VERSION ""

NS_ :

BS_:

BU_: BMS CVC_P EVCC FMCU RMCU POD_GW PCU ADCU_P DUMMY_ECU

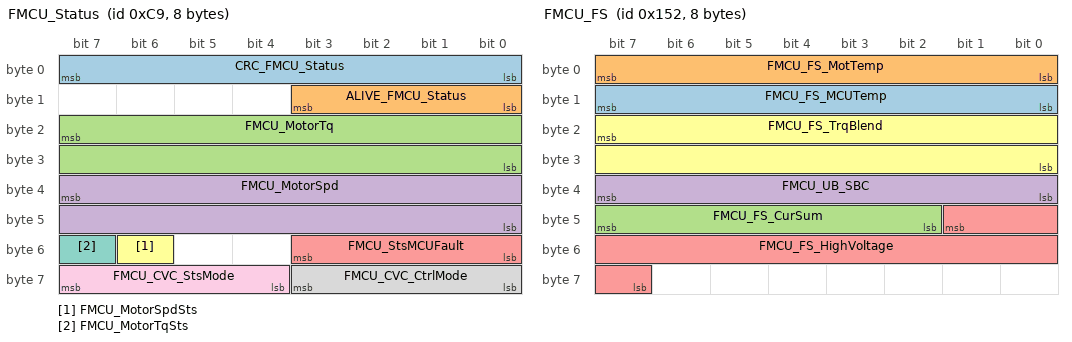
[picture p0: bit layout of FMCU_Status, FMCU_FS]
BO_ 201 FMCU_Status: 8 FMCU
 SG_ CRC_FMCU_Status : 7|8@0+ (1,0) [0|255] ""  BMS,CVC_P,EVCC
 SG_ ALIVE_FMCU_Status : 11|4@0+ (1,0) [0|15] ""  BMS,CVC_P,EVCC
 SG_ FMCU_MotorTq : 23|16@0+ (0.1,-400) [-400|400] "Nm"  BMS,CVC_P,EVCC
 SG_ FMCU_MotorSpd : 39|16@0+ (1,-20000) [-20000|45531] "rpm"  BMS,CVC_P,EVCC
 SG_ FMCU_StsMCUFault : 51|4@0+ (1,0) [0|15] ""  BMS,CVC_P,EVCC
 SG_ FMCU_MotorSpdSts : 54|1@0+ (1,0) [0|1] ""  BMS,CVC_P,EVCC
 SG_ FMCU_MotorTqSts : 55|1@0+ (1,0) [0|1] ""  BMS,CVC_P,EVCC
 SG_ FMCU_CVC_CtrlMode : 59|4@0+ (1,0) [0|15] ""  BMS,CVC_P,EVCC
 SG_ FMCU_CVC_StsMode : 63|4@0+ (1,0) [0|15] ""  BMS,CVC_P,EVCC

BO_ 202 FMCU_Ability: 12 FMCU
 SG_ CRC_FMCU_Ability : 7|8@0+ (1,0) [0|255] ""  CVC_P
 SG_ ALIVE_FMCU_Ability : 11|4@0+ (1,0) [0|15] ""  CVC_P
 SG_ FMCU_CVC_PosTrqLmt : 53|12@0+ (0.1,0) [0|400] ""  CVC_P
 SG_ FMCU_CVC_NegTrqLmt : 57|12@0+ (0.1,-400) [-400|0] "Nm"  CVC_P
 SG_ FMCU_ActInputCurrent : 31|12@0+ (0.5,-1000) [-1000|1000] "A"  CVC_P
 SG_ FMCU_ActInputVolt : 35|12@0+ (0.5,0) [0|1000] "V"  CVC_P
 SG_ FMCU_ActInputVoltV : 54|1@0+ (1,0) [0|1] ""  CVC_P
 SG_ FMCU_ActInputCurrentV : 55|1@0+ (1,0) [0|1] ""  CVC_P

BO_ 338 FMCU_FS: 8 FMCU
 SG_ FMCU_FS_MCUTemp : 15|8@0+ (1,-50) [-50|200] "Degree C"  DUMMY_ECU
 SG_ FMCU_FS_MotTemp : 7|8@0+ (1,-50) [-50|200] "Degree C"  DUMMY_ECU
 SG_ FMCU_FS_CurSum : 47|6@0+ (1,0) [0|63] "V"  DUMMY_ECU
 SG_ FMCU_UB_SBC : 39|8@0+ (0.1,0) [0|25.5] "V"  DUMMY_ECU
 SG_ FMCU_FS_HighVoltage : 41|11@0+ (0.5,0) [0|1023.5] "V"  DUMMY_ECU
 SG_ FMCU_FS_TrqBlend : 23|16@0+ (0.1,-400) [-400|400] "Nm"  DUMMY_ECU

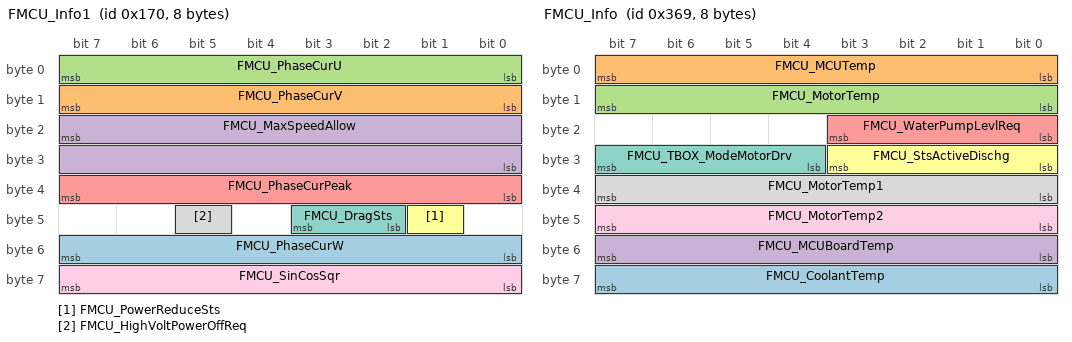
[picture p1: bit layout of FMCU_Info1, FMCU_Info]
BO_ 368 FMCU_Info1: 8 FMCU
 SG_ FMCU_PhaseCurW : 55|8@0+ (12,-1500) [-1500|1560] "A"  CVC_P
 SG_ FMCU_PhaseCurV : 15|8@0+ (12,-1500) [-1500|1560] "A"  CVC_P
 SG_ FMCU_PhaseCurU : 7|8@0+ (12,-1500) [-1500|1560] "A"  CVC_P
 SG_ FMCU_MaxSpeedAllow : 23|16@0+ (1,-17000) [-17000|17000] "rpm"  CVC_P
 SG_ FMCU_PhaseCurPeak : 39|8@0+ (12,-1500) [-1500|1560] "A"  CVC_P
 SG_ FMCU_PowerReduceSts : 41|1@0+ (1,0) [0|1] ""  CVC_P
 SG_ FMCU_DragSts : 43|2@0+ (1,0) [0|3] ""  CVC_P
 SG_ FMCU_HighVoltPowerOffReq : 45|1@0+ (1,0) [0|1] ""  CVC_P
 SG_ FMCU_SinCosSqr : 63|8@0+ (0.2,0) [0|51] ""  CVC_P

BO_ 568 FMCU_curSts: 12 FMCU
 SG_ FMCU_IGBT_WTemp : 63|8@0+ (1,-50) [-50|200] "Degree C"  CVC_P
 SG_ FMCU_IGBT_VTemp : 55|8@0+ (1,-50) [-50|200] "Degree C"  CVC_P
 SG_ FMCU_IGBT_UTemp : 47|8@0+ (1,-50) [-50|200] "Degree C"  CVC_P
 SG_ FMCU_JunctionIGBT_WTemp : 31|8@0+ (1,-50) [-50|200] "Degree C"  CVC_P
 SG_ FMCU_JunctionIGBT_VTemp : 23|8@0+ (1,-50) [-50|200] "Degree C"  CVC_P
 SG_ FMCU_JunctionIGBT_UTemp : 15|8@0+ (1,-50) [-50|200] "Degree C"  CVC_P
 SG_ FMCU_KL15 : 32|1@0+ (1,0) [0|1] ""  CVC_P
 SG_ FMCU_KL30 : 71|8@0+ (0.1,0) [0|25.5] "V"  CVC_P
 SG_ FMCU_SSUState : 36|3@0+ (1,0) [0|7] ""  CVC_P
 SG_ FMCU_DampingState : 37|1@0+ (1,0) [0|1] ""  CVC_P
 SG_ FMCU_IGBTState : 39|2@0+ (1,0) [0|3] ""  CVC_P
 SG_ FMCU_ASRSts : 33|1@0+ (1,0) [0|1] ""  CVC_P
 SG_ FMCU_ActualActiveHeatingPwr : 74|3@0+ (1,0) [0|8] "kW"  CVC_P

BO_ 872 FMCU_Fault: 8 FMCU
 SG_ FMCU_PhaseOverCurrentSWFault : 0|1@0+ (1,0) [0|1] ""  CVC_P
 SG_ FMCU_MCUOverTempFault : 1|1@0+ (1,0) [0|1] ""  CVC_P
 SG_ FMCU_MCUOverTempAlarm : 2|1@0+ (1,0) [0|1] ""  CVC_P
 SG_ FMCU_MotOverTemp2Fault : 5|1@0+ (1,0) [0|1] ""  CVC_P
 SG_ FMCU_MotTempSenFault : 6|1@0+ (1,0) [0|1] ""  CVC_P
 SG_ FMCU_MotOverTemp1Fault : 7|1@0+ (1,0) [0|1] ""  CVC_P
 SG_ FMCU_MotOverTempAlarm : 8|1@0+ (1,0) [0|1] ""  CVC_P
 SG_ FMCU_MCUHVUnderVoltageFault : 9|1@0+ (1,0) [0|1] ""  CVC_P
 SG_ FMCU_MCUHVUnderVoltageAlarm : 10|1@0+ (1,0) [0|1] ""  CVC_P
 SG_ FMCU_MCUHVOverVoltageFault : 11|1@0+ (1,0) [0|1] ""  CVC_P
 SG_ FMCU_MCUHVOverVoltageAlarm : 12|1@0+ (1,0) [0|1] ""  CVC_P
 SG_ FMCU_MCUCurrentSenWFault : 13|1@0+ (1,0) [0|1] ""  CVC_P
 SG_ FMCU_MCUCurrentSenVFault : 14|1@0+ (1,0) [0|1] ""  CVC_P
 SG_ FMCU_MCUCurrentSenUFault : 15|1@0+ (1,0) [0|1] ""  CVC_P
 SG_ FMCU_PhaseOverCurrentHWFault : 16|1@0+ (1,0) [0|1] ""  CVC_P
 SG_ FMCU_MotOverFault : 17|1@0+ (1,0) [0|1] ""  CVC_P
 SG_ FMCU_MotOverAlarm : 18|1@0+ (1,0) [0|1] ""  CVC_P
 SG_ FMCU_12VUnderVoltageAlarm : 20|1@0+ (1,0) [0|1] ""  CVC_P
 SG_ FMCU_12VOverVoltageAlarm : 21|1@0+ (1,0) [0|1] ""  CVC_P
 SG_ FMCU_MCUHVSensorFault : 22|1@0+ (1,0) [0|1] ""  CVC_P
 SG_ FMCU_MCUDisChgFault : 24|1@0+ (1,0) [0|1] ""  CVC_P
 SG_ FMCU_MotBlockedFault : 30|1@0+ (1,0) [0|1] ""  CVC_P
 SG_ FMCU_MotRotSenFault : 31|1@0+ (1,0) [0|1] ""  CVC_P
 SG_ FMCU_BMSLostFault : 34|1@0+ (1,0) [0|1] ""  CVC_P
 SG_ FMCU_CVCLostFault : 35|1@0+ (1,0) [0|1] ""  CVC_P
 SG_ FMCU_CANBusoffFault : 36|1@0+ (1,0) [0|1] ""  CVC_P
 SG_ FMCU_IGBTFault : 37|1@0+ (1,0) [0|1] ""  CVC_P
 SG_ FMCU_MCUCurrentSenWZeroFault : 38|1@0+ (1,0) [0|1] ""  CVC_P
 SG_ FMCU_MCUCurrentSenVZeroFault : 43|1@0+ (1,0) [0|1] ""  CVC_P
 SG_ FMCU_MCUCurrentSenUZeroFault : 44|1@0+ (1,0) [0|1] ""  CVC_P
 SG_ FMCU_MCUTempSenWFault : 45|1@0+ (1,0) [0|1] ""  CVC_P
 SG_ FMCU_MCUTempSenVFault : 46|1@0+ (1,0) [0|1] ""  CVC_P
 SG_ FMCU_MCUTempSenUFault : 47|1@0+ (1,0) [0|1] ""  CVC_P
 SG_ FMCU_InitMode : 50|1@0+ (1,0) [0|1] ""  CVC_P
 SG_ FMCU_MCUFaultCode : 63|8@0+ (1,0) [0|255] ""  CVC_P

BO_ 873 FMCU_Info: 8 FMCU
 SG_ FMCU_CoolantTemp : 63|8@0+ (1,-50) [-50|200] "Degree C"  CVC_P
 SG_ FMCU_MCUTemp : 7|8@0+ (1,-40) [-40|210] "Degree C"  CVC_P
 SG_ FMCU_MotorTemp : 15|8@0+ (1,-40) [-40|210] "Degree C"  CVC_P
 SG_ FMCU_MCUBoardTemp : 55|8@0+ (1,-40) [-40|210] "Degree C"  CVC_P
 SG_ FMCU_WaterPumpLevlReq : 19|4@0+ (2,0) [0|30] "lpm"  CVC_P
 SG_ FMCU_StsActiveDischg : 27|4@0+ (1,0) [0|15] ""  CVC_P
 SG_ FMCU_TBOX_ModeMotorDrv : 31|4@0+ (1,0) [0|15] ""  CVC_P
 SG_ FMCU_MotorTemp1 : 39|8@0+ (1,-40) [-40|210] "Degree C"  CVC_P
 SG_ FMCU_MotorTemp2 : 47|8@0+ (1,-40) [-40|210] "Degree C"  CVC_P

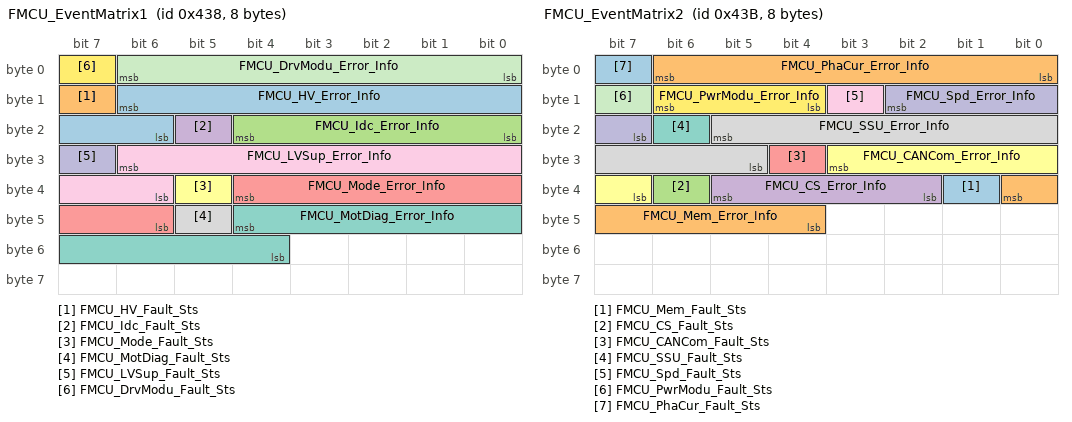
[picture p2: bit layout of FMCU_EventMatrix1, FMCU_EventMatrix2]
BO_ 1080 FMCU_EventMatrix1: 8 FMCU
 SG_ FMCU_HV_Error_Info : 14|9@0+ (1,0) [0|511] ""  DUMMY_ECU
 SG_ FMCU_HV_Fault_Sts : 15|1@0+ (1,0) [0|1] ""  DUMMY_ECU
 SG_ FMCU_Idc_Error_Info : 20|5@0+ (1,0) [0|31] ""  DUMMY_ECU
 SG_ FMCU_Idc_Fault_Sts : 21|1@0+ (1,0) [0|1] ""  DUMMY_ECU
 SG_ FMCU_Mode_Error_Info : 36|7@0+ (1,0) [0|127] ""  DUMMY_ECU
 SG_ FMCU_Mode_Fault_Sts : 37|1@0+ (1,0) [0|1] ""  DUMMY_ECU
 SG_ FMCU_MotDiag_Error_Info : 44|9@0+ (1,0) [0|511] ""  DUMMY_ECU
 SG_ FMCU_MotDiag_Fault_Sts : 45|1@0+ (1,0) [0|1] ""  DUMMY_ECU
 SG_ FMCU_LVSup_Error_Info : 30|9@0+ (1,0) [0|511] ""  DUMMY_ECU
 SG_ FMCU_LVSup_Fault_Sts : 31|1@0+ (1,0) [0|1] ""  DUMMY_ECU
 SG_ FMCU_DrvModu_Error_Info : 6|7@0+ (1,0) [0|127] ""  DUMMY_ECU
 SG_ FMCU_DrvModu_Fault_Sts : 7|1@0+ (1,0) [0|1] ""  DUMMY_ECU

BO_ 1083 FMCU_EventMatrix2: 8 FMCU
 SG_ FMCU_Mem_Fault_Sts : 33|1@0+ (1,0) [0|1] ""  DUMMY_ECU
 SG_ FMCU_Mem_Error_Info : 32|5@0+ (1,0) [0|31] ""  DUMMY_ECU
 SG_ FMCU_CS_Fault_Sts : 38|1@0+ (1,0) [0|1] ""  DUMMY_ECU
 SG_ FMCU_CS_Error_Info : 37|4@0+ (1,0) [0|15] ""  DUMMY_ECU
 SG_ FMCU_CANCom_Fault_Sts : 28|1@0+ (1,0) [0|1] ""  DUMMY_ECU
 SG_ FMCU_CANCom_Error_Info : 27|5@0+ (1,0) [0|31] ""  DUMMY_ECU
 SG_ FMCU_SSU_Fault_Sts : 22|1@0+ (1,0) [0|1] ""  DUMMY_ECU
 SG_ FMCU_SSU_Error_Info : 21|9@0+ (1,0) [0|511] ""  DUMMY_ECU
 SG_ FMCU_Spd_Fault_Sts : 11|1@0+ (1,0) [0|1] ""  DUMMY_ECU
 SG_ FMCU_Spd_Error_Info : 10|4@0+ (1,0) [0|15] ""  DUMMY_ECU
 SG_ FMCU_PwrModu_Fault_Sts : 15|1@0+ (1,0) [0|1] ""  DUMMY_ECU
 SG_ FMCU_PwrModu_Error_Info : 14|3@0+ (1,0) [0|7] ""  DUMMY_ECU
 SG_ FMCU_PhaCur_Fault_Sts : 7|1@0+ (1,0) [0|1] ""  DUMMY_ECU
 SG_ FMCU_PhaCur_Error_Info : 6|7@0+ (1,0) [0|127] ""  DUMMY_ECU

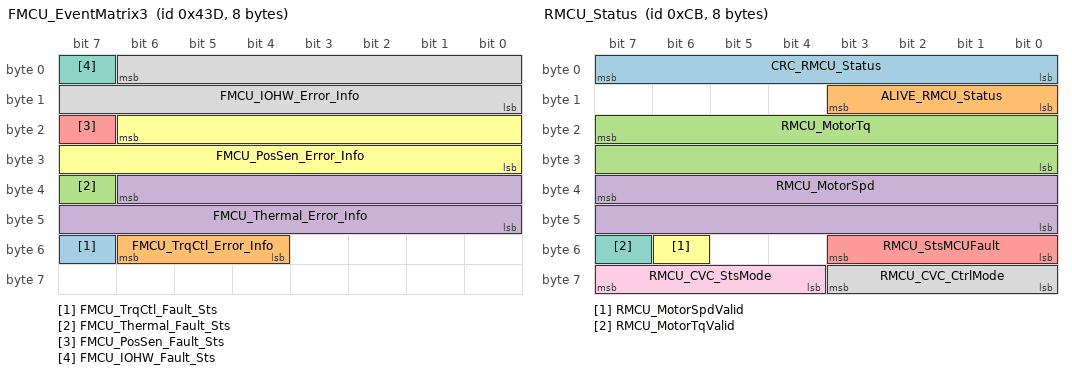
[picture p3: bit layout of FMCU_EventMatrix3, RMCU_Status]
BO_ 1085 FMCU_EventMatrix3: 8 FMCU
 SG_ FMCU_TrqCtl_Fault_Sts : 55|1@0+ (1,0) [0|1] ""  DUMMY_ECU
 SG_ FMCU_TrqCtl_Error_Info : 54|3@0+ (1,0) [0|7] ""  DUMMY_ECU
 SG_ FMCU_Thermal_Fault_Sts : 39|1@0+ (1,0) [0|1] ""  DUMMY_ECU
 SG_ FMCU_Thermal_Error_Info : 38|15@0+ (1,0) [0|32767] ""  DUMMY_ECU
 SG_ FMCU_PosSen_Fault_Sts : 23|1@0+ (1,0) [0|1] ""  DUMMY_ECU
 SG_ FMCU_PosSen_Error_Info : 22|15@0+ (1,0) [0|32767] ""  DUMMY_ECU
 SG_ FMCU_IOHW_Fault_Sts : 7|1@0+ (1,0) [0|1] ""  DUMMY_ECU
 SG_ FMCU_IOHW_Error_Info : 6|15@0+ (1,0) [0|32767] ""  DUMMY_ECU

BO_ 1087 FMCU_EventMatrix4: 8 FMCU
 SG_ FMCU_FS_PhaCurMon_Error_Info : 28|4@0+ (1,0) [0|15] ""  DUMMY_ECU
 SG_ FMCU_FS_SOPMon_Error_Info : 48|5@0+ (1,0) [0|15] ""  DUMMY_ECU
 SG_ FMCU_FS_MCUMon_Error_Info : 53|4@0+ (1,0) [0|15] ""  DUMMY_ECU
 SG_ FMCU_FS_SBCMon_Error_Info : 42|4@0+ (1,0) [0|15] ""  DUMMY_ECU
 SG_ FMCU_FS_TempMon_Error_Info : 35|8@0+ (1,0) [0|255] ""  DUMMY_ECU
 SG_ FMCU_FS_SpdMon_Error_Info : 39|3@0+ (1,0) [0|7] ""  DUMMY_ECU
 SG_ FMCU_FS_TrqMon_Error_Info : 21|8@0+ (1,0) [0|255] ""  DUMMY_ECU
 SG_ FMCU_FS_HVMon_Error_Info : 6|8@0+ (1,0) [0|255] ""  DUMMY_ECU
 SG_ FMCU_FS_LVMon_Error_Info : 13|7@0+ (1,0) [0|127] ""  DUMMY_ECU
 SG_ FMCU_FS_SOPMonFault : 49|1@0+ (1,0) [0|1] ""  DUMMY_ECU
 SG_ FMCU_FS_MCUMonFault : 54|1@0+ (1,0) [0|1] ""  DUMMY_ECU
 SG_ FMCU_FS_SBCMonFault : 43|1@0+ (1,0) [0|1] ""  DUMMY_ECU
 SG_ FMCU_FS_TempMonFault : 36|1@0+ (1,0) [0|1] ""  DUMMY_ECU
 SG_ FMCU_FS_SpdMonFault : 24|1@0+ (1,0) [0|1] ""  DUMMY_ECU
 SG_ FMCU_FS_PhaCurMonFault : 29|1@0+ (1,0) [0|1] ""  DUMMY_ECU
 SG_ FMCU_FS_TrqMonFault : 22|1@0+ (1,0) [0|1] ""  DUMMY_ECU
 SG_ FMCU_FS_LVMonFault : 14|1@0+ (1,0) [0|1] ""  DUMMY_ECU
 SG_ FMCU_FS_HVFault : 7|1@0+ (1,0) [0|1] ""  DUMMY_ECU

BO_ 1179 FMCU_WarnMsg: 8 FMCU
 SG_ CRC_FMCU_WarnMsg : 7|8@0+ (1,0) [0|255] ""  CVC_P
 SG_ ALIVE_FMCU_WarnMsg : 11|4@0+ (1,0) [0|15] ""  CVC_P
 SG_ FMCU_Warning_Flag_1 : 12|1@0+ (1,0) [0|1] ""  CVC_P
 SG_ FMCU_Warning_Flag_2 : 13|1@0+ (1,0) [0|1] ""  CVC_P
 SG_ FMCU_Warning_Flag_3 : 14|1@0+ (1,0) [0|1] ""  CVC_P
 SG_ FMCU_Warning_Flag_4 : 15|1@0+ (1,0) [0|1] ""  CVC_P
 SG_ FMCU_Warning_Flag_5 : 16|1@0+ (1,0) [0|1] ""  CVC_P
 SG_ FMCU_Warning_Flag_6 : 17|1@0+ (1,0) [0|1] ""  CVC_P
 SG_ FMCU_Warning_Flag_7 : 18|1@0+ (1,0) [0|1] ""  CVC_P
 SG_ FMCU_Warning_Flag_8 : 19|1@0+ (1,0) [0|1] ""  CVC_P
 SG_ FMCU_Warning_Flag_9 : 20|1@0+ (1,0) [0|1] ""  CVC_P
 SG_ FMCU_Warning_Flag_10 : 21|1@0+ (1,0) [0|1] ""  CVC_P
 SG_ FMCU_Warning_Flag_11 : 22|1@0+ (1,0) [0|1] ""  CVC_P
 SG_ FMCU_Warning_Flag_12 : 23|1@0+ (1,0) [0|1] ""  CVC_P
 SG_ FMCU_Reserved_signal1 : 31|8@0+ (1,0) [0|255] ""  CVC_P
 SG_ FMCU_Reserved_signal2 : 39|8@0+ (1,0) [0|255] ""  CVC_P
 SG_ FMCU_Reserved_signal3 : 47|8@0+ (1,0) [0|255] ""  CVC_P
 SG_ FMCU_Reserved_signal4 : 55|8@0+ (1,0) [0|255] ""  CVC_P
 SG_ FMCU_Reserved_signal5 : 63|8@0+ (1,0) [0|255] ""  CVC_P

BO_ 1976 FMCU_Synchronization_Req: 8 FMCU
 SG_ FMCU_Req_RandomData : 7|24@0+ (1,0) [0|16777215] ""  CVC_P
 SG_ FMCU_Req_MAC : 31|40@0+ (1,0) [0|1099511627775] ""  CVC_P

BO_ 91 RMCU_ResetInfo: 12 RMCU
 SG_ RMCU_Trap_Tin : 7|16@0+ (1,0) [0|65535] ""  DUMMY_ECU
 SG_ RMCU_Trap_Class : 23|16@0+ (1,0) [0|65535] ""  DUMMY_ECU
 SG_ RMCU_ReturnAddress : 71|32@0+ (1,0) [0|4294967295] ""  DUMMY_ECU
 SG_ RMCU_DEADD_Value : 39|32@0+ (1,0) [0|4294967295] ""  DUMMY_ECU

BO_ 203 RMCU_Status: 8 RMCU
 SG_ CRC_RMCU_Status : 7|8@0+ (1,0) [0|255] ""  CVC_P,EVCC,PCU
 SG_ ALIVE_RMCU_Status : 11|4@0+ (1,0) [0|15] ""  CVC_P,EVCC,PCU
 SG_ RMCU_MotorTq : 23|16@0+ (0.1,-400) [-400|400] "Nm"  CVC_P,EVCC,PCU
 SG_ RMCU_MotorSpd : 39|16@0+ (1,-20000) [-20000|45531] "rpm"  CVC_P,EVCC,PCU
 SG_ RMCU_StsMCUFault : 51|4@0+ (1,0) [0|15] ""  CVC_P,EVCC
 SG_ RMCU_MotorSpdValid : 54|1@0+ (1,0) [0|1] ""  CVC_P,EVCC
 SG_ RMCU_MotorTqValid : 55|1@0+ (1,0) [0|1] ""  CVC_P,EVCC
 SG_ RMCU_CVC_CtrlMode : 59|4@0+ (1,0) [0|15] ""  CVC_P,EVCC
 SG_ RMCU_CVC_StsMode : 63|4@0+ (1,0) [0|15] ""  CVC_P,EVCC

BO_ 204 RMCU_Ability: 12 RMCU
 SG_ CRC_RMCU_Ability : 7|8@0+ (1,0) [0|255] ""  CVC_P,PCU
 SG_ ALIVE_RMCU_Ability : 11|4@0+ (1,0) [0|15] ""  CVC_P,PCU
 SG_ RMCU_CVC_PosTrqLmt : 53|12@0+ (0.1,0) [0|400] ""  CVC_P
 SG_ RMCU_CVC_NegTrqLmt : 57|12@0+ (0.1,-400) [-400|0] "Nm"  CVC_P
 SG_ RMCU_ActInputCurrent : 31|12@0+ (0.5,-1000) [-1000|1000] "A"  CVC_P,PCU
 SG_ RMCU_ActInputVolt : 35|12@0+ (0.5,0) [0|1000] "V"  CVC_P,PCU
 SG_ RMCU_ActInputVoltV : 54|1@0+ (1,0) [0|1] ""  CVC_P,PCU
 SG_ RMCU_ActInputCurrentV : 55|1@0+ (1,0) [0|1] ""  CVC_P,PCU

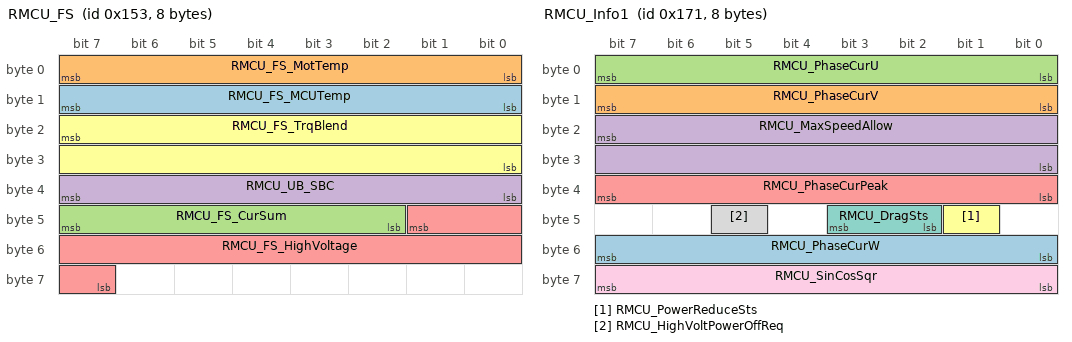
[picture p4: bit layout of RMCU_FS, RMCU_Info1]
BO_ 339 RMCU_FS: 8 RMCU
 SG_ RMCU_FS_MCUTemp : 15|8@0+ (1,-50) [-50|200] "Degree C"  DUMMY_ECU
 SG_ RMCU_FS_MotTemp : 7|8@0+ (1,-50) [-50|200] "Degree C"  DUMMY_ECU
 SG_ RMCU_FS_CurSum : 47|6@0+ (1,0) [0|63] "V"  DUMMY_ECU
 SG_ RMCU_UB_SBC : 39|8@0+ (0.1,0) [0|25.5] "V"  DUMMY_ECU
 SG_ RMCU_FS_HighVoltage : 41|11@0+ (0.5,0) [0|1023.5] "V"  DUMMY_ECU
 SG_ RMCU_FS_TrqBlend : 23|16@0+ (0.1,-400) [-400|400] "Nm"  DUMMY_ECU

BO_ 369 RMCU_Info1: 8 RMCU
 SG_ RMCU_PhaseCurW : 55|8@0+ (12,-1500) [-1500|1560] "A"  CVC_P
 SG_ RMCU_PhaseCurV : 15|8@0+ (12,-1500) [-1500|1560] "A"  CVC_P
 SG_ RMCU_PhaseCurU : 7|8@0+ (12,-1500) [-1500|1560] "A"  CVC_P
 SG_ RMCU_MaxSpeedAllow : 23|16@0+ (1,-17000) [-17000|17000] "rpm"  CVC_P
 SG_ RMCU_PhaseCurPeak : 39|8@0+ (12,-1500) [-1500|1560] "A"  CVC_P
 SG_ RMCU_PowerReduceSts : 41|1@0+ (1,0) [0|1] ""  CVC_P
 SG_ RMCU_DragSts : 43|2@0+ (1,0) [0|3] ""  CVC_P
 SG_ RMCU_HighVoltPowerOffReq : 45|1@0+ (1,0) [0|1] ""  CVC_P
 SG_ RMCU_SinCosSqr : 63|8@0+ (0.2,0) [0|51] ""  CVC_P

BO_ 569 RMCU_curSts: 12 RMCU
 SG_ RMCU_IGBT_WTemp : 63|8@0+ (1,-50) [-50|200] "Degree C"  CVC_P
 SG_ RMCU_IGBT_VTemp : 55|8@0+ (1,-50) [-50|200] "Degree C"  CVC_P
 SG_ RMCU_IGBT_UTemp : 47|8@0+ (1,-50) [-50|200] "Degree C"  CVC_P
 SG_ RMCU_JunctionIGBT_WTemp : 31|8@0+ (1,-50) [-50|200] "Degree C"  CVC_P
 SG_ RMCU_JunctionIGBT_VTemp : 23|8@0+ (1,-50) [-50|200] "Degree C"  CVC_P
 SG_ RMCU_JunctionIGBT_UTemp : 15|8@0+ (1,-50) [-50|200] "Degree C"  CVC_P
 SG_ RMCU_KL15 : 32|1@0+ (1,0) [0|1] ""  CVC_P
 SG_ RMCU_KL30 : 71|8@0+ (0.1,0) [0|25.5] "V"  CVC_P
 SG_ RMCU_SSUState : 36|3@0+ (1,0) [0|7] ""  CVC_P
 SG_ RMCU_DampingState : 37|1@0+ (1,0) [0|1] ""  CVC_P
 SG_ RMCU_IGBTState : 39|2@0+ (1,0) [0|3] ""  CVC_P
 SG_ RMCU_ASRSts : 33|1@0+ (1,0) [0|1] ""  CVC_P
 SG_ RMCU_ActualActiveHeatingPwr : 74|3@0+ (1,0) [0|8] "kW"  CVC_P

BO_ 874 RMCU_Fault: 8 RMCU
 SG_ RMCU_PhaseOverCurrentSWFault : 0|1@0+ (1,0) [0|1] ""  CVC_P
 SG_ RMCU_MCUOverTempFault : 1|1@0+ (1,0) [0|1] ""  CVC_P
 SG_ RMCU_MCUOverTempAlarm : 2|1@0+ (1,0) [0|1] ""  CVC_P
 SG_ RMCU_MotOverTemp2Fault : 5|1@0+ (1,0) [0|1] ""  CVC_P
 SG_ RMCU_MotTempSenFault : 6|1@0+ (1,0) [0|1] ""  CVC_P
 SG_ RMCU_MotOverTemp1Fault : 7|1@0+ (1,0) [0|1] ""  CVC_P
 SG_ RMCU_MotOverTempAlarm : 8|1@0+ (1,0) [0|1] ""  CVC_P
 SG_ RMCU_MCUHVUnderVoltageFault : 9|1@0+ (1,0) [0|1] ""  CVC_P
 SG_ RMCU_MCUHVUnderVoltageAlarm : 10|1@0+ (1,0) [0|1] ""  CVC_P
 SG_ RMCU_MCUHVOverVoltageFault : 11|1@0+ (1,0) [0|1] ""  CVC_P
 SG_ RMCU_MCUHVOverVoltageAlarm : 12|1@0+ (1,0) [0|1] ""  CVC_P
 SG_ RMCU_MCUCurrentSenWFault : 13|1@0+ (1,0) [0|1] ""  CVC_P
 SG_ RMCU_MCUCurrentSenVFault : 14|1@0+ (1,0) [0|1] ""  CVC_P
 SG_ RMCU_MCUCurrentSenUFault : 15|1@0+ (1,0) [0|1] ""  CVC_P
 SG_ RMCU_PhaseOverCurrentHWFault : 16|1@0+ (1,0) [0|1] ""  CVC_P
 SG_ RMCU_MotOverFault : 17|1@0+ (1,0) [0|1] ""  CVC_P
 SG_ RMCU_MotOverAlarm : 18|1@0+ (1,0) [0|1] ""  CVC_P
 SG_ RMCU_12VUnderVoltageAlarm : 20|1@0+ (1,0) [0|1] ""  CVC_P
 SG_ RMCU_12VOverVoltageAlarm : 21|1@0+ (1,0) [0|1] ""  CVC_P
 SG_ RMCU_MCUHVSensorFault : 22|1@0+ (1,0) [0|1] ""  CVC_P
 SG_ RMCU_MCUDisChgFault : 24|1@0+ (1,0) [0|1] ""  CVC_P
 SG_ RMCU_MotBlockedFault : 30|1@0+ (1,0) [0|1] ""  CVC_P
 SG_ RMCU_MotRotSenFault : 31|1@0+ (1,0) [0|1] ""  CVC_P
 SG_ RMCU_BMSLostFault : 34|1@0+ (1,0) [0|1] ""  CVC_P
 SG_ RMCU_CVCLostFault : 35|1@0+ (1,0) [0|1] ""  CVC_P
 SG_ RMCU_CANBusoffFault : 36|1@0+ (1,0) [0|1] ""  CVC_P
 SG_ RMCU_IGBTFault : 37|1@0+ (1,0) [0|1] ""  CVC_P
 SG_ RMCU_MCUCurrentSenWZeroFault : 38|1@0+ (1,0) [0|1] ""  CVC_P
 SG_ RMCU_MCUCurrentSenVZeroFault : 43|1@0+ (1,0) [0|1] ""  CVC_P
 SG_ RMCU_MCUCurrentSenUZeroFault : 44|1@0+ (1,0) [0|1] ""  CVC_P
 SG_ RMCU_MCUTempSenWFault : 45|1@0+ (1,0) [0|1] ""  CVC_P
 SG_ RMCU_MCUTempSenVFault : 46|1@0+ (1,0) [0|1] ""  CVC_P
 SG_ RMCU_MCUTempSenUFault : 47|1@0+ (1,0) [0|1] ""  CVC_P
 SG_ RMCU_InitMode : 50|1@0+ (1,0) [0|1] ""  CVC_P
 SG_ RMCU_MCUFaultCode : 63|8@0+ (1,0) [0|255] ""  CVC_P

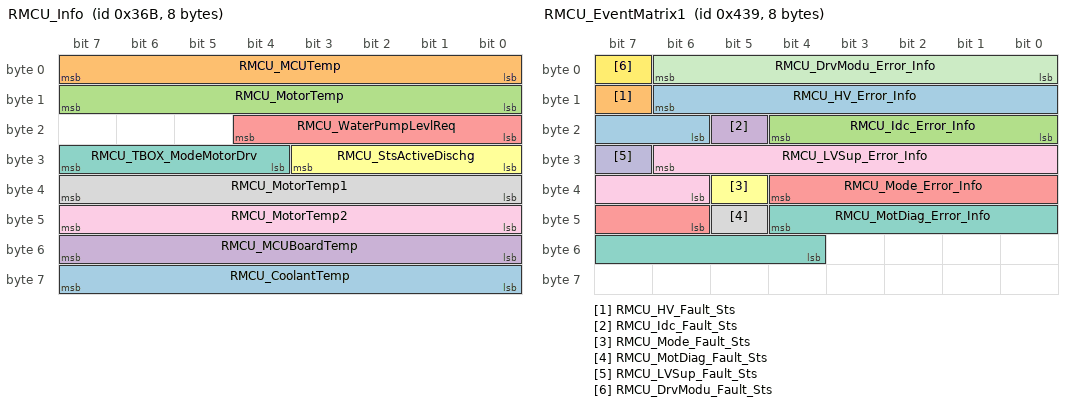
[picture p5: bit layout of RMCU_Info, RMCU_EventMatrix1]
BO_ 875 RMCU_Info: 8 RMCU
 SG_ RMCU_CoolantTemp : 63|8@0+ (1,-50) [-50|200] "Degree C"  CVC_P
 SG_ RMCU_MCUTemp : 7|8@0+ (1,-40) [-40|210] "Degree C"  CVC_P
 SG_ RMCU_MotorTemp : 15|8@0+ (1,-40) [-40|210] "Degree C"  CVC_P
 SG_ RMCU_MCUBoardTemp : 55|8@0+ (1,-40) [-40|210] "Degree C"  CVC_P
 SG_ RMCU_WaterPumpLevlReq : 20|5@0+ (1,0) [0|30] "l/min"  CVC_P
 SG_ RMCU_StsActiveDischg : 27|4@0+ (1,0) [0|15] ""  CVC_P
 SG_ RMCU_TBOX_ModeMotorDrv : 31|4@0+ (1,0) [0|15] ""  CVC_P
 SG_ RMCU_MotorTemp1 : 39|8@0+ (1,-40) [-40|210] "Degree C"  CVC_P
 SG_ RMCU_MotorTemp2 : 47|8@0+ (1,-40) [-40|210] "Degree C"  CVC_P

BO_ 1081 RMCU_EventMatrix1: 8 RMCU
 SG_ RMCU_HV_Error_Info : 14|9@0+ (1,0) [0|511] ""  DUMMY_ECU
 SG_ RMCU_HV_Fault_Sts : 15|1@0+ (1,0) [0|1] ""  DUMMY_ECU
 SG_ RMCU_Idc_Error_Info : 20|5@0+ (1,0) [0|31] ""  DUMMY_ECU
 SG_ RMCU_Idc_Fault_Sts : 21|1@0+ (1,0) [0|1] ""  DUMMY_ECU
 SG_ RMCU_Mode_Error_Info : 36|7@0+ (1,0) [0|127] ""  DUMMY_ECU
 SG_ RMCU_Mode_Fault_Sts : 37|1@0+ (1,0) [0|1] ""  DUMMY_ECU
 SG_ RMCU_MotDiag_Error_Info : 44|9@0+ (1,0) [0|511] ""  DUMMY_ECU
 SG_ RMCU_MotDiag_Fault_Sts : 45|1@0+ (1,0) [0|1] ""  DUMMY_ECU
 SG_ RMCU_LVSup_Error_Info : 30|9@0+ (1,0) [0|511] ""  DUMMY_ECU
 SG_ RMCU_LVSup_Fault_Sts : 31|1@0+ (1,0) [0|1] ""  DUMMY_ECU
 SG_ RMCU_DrvModu_Error_Info : 6|7@0+ (1,0) [0|127] ""  DUMMY_ECU
 SG_ RMCU_DrvModu_Fault_Sts : 7|1@0+ (1,0) [0|1] ""  DUMMY_ECU

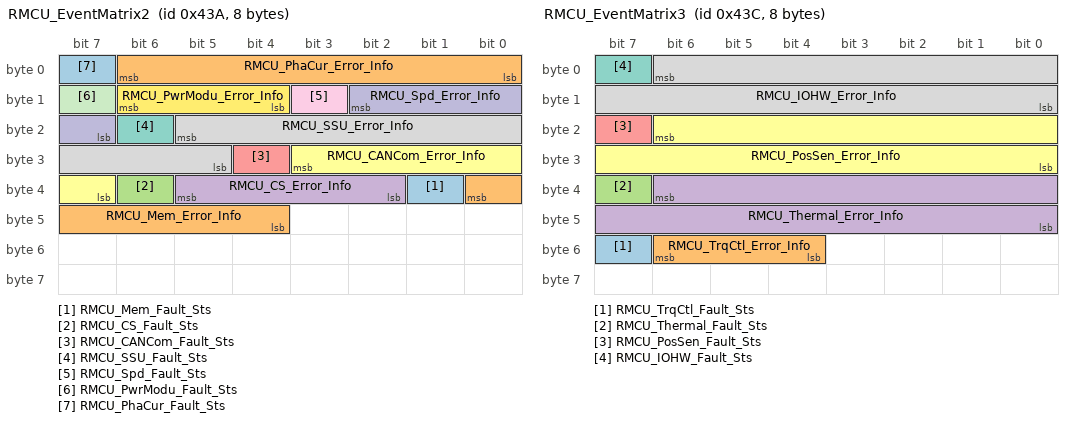
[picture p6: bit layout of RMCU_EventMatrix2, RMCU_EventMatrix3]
BO_ 1082 RMCU_EventMatrix2: 8 RMCU
 SG_ RMCU_Mem_Fault_Sts : 33|1@0+ (1,0) [0|1] ""  DUMMY_ECU
 SG_ RMCU_Mem_Error_Info : 32|5@0+ (1,0) [0|31] ""  DUMMY_ECU
 SG_ RMCU_CS_Fault_Sts : 38|1@0+ (1,0) [0|1] ""  DUMMY_ECU
 SG_ RMCU_CS_Error_Info : 37|4@0+ (1,0) [0|15] ""  DUMMY_ECU
 SG_ RMCU_CANCom_Fault_Sts : 28|1@0+ (1,0) [0|1] ""  DUMMY_ECU
 SG_ RMCU_CANCom_Error_Info : 27|5@0+ (1,0) [0|31] ""  DUMMY_ECU
 SG_ RMCU_SSU_Fault_Sts : 22|1@0+ (1,0) [0|1] ""  DUMMY_ECU
 SG_ RMCU_SSU_Error_Info : 21|9@0+ (1,0) [0|511] ""  DUMMY_ECU
 SG_ RMCU_Spd_Fault_Sts : 11|1@0+ (1,0) [0|1] ""  DUMMY_ECU
 SG_ RMCU_Spd_Error_Info : 10|4@0+ (1,0) [0|15] ""  DUMMY_ECU
 SG_ RMCU_PwrModu_Fault_Sts : 15|1@0+ (1,0) [0|1] ""  DUMMY_ECU
 SG_ RMCU_PwrModu_Error_Info : 14|3@0+ (1,0) [0|7] ""  DUMMY_ECU
 SG_ RMCU_PhaCur_Fault_Sts : 7|1@0+ (1,0) [0|1] ""  DUMMY_ECU
 SG_ RMCU_PhaCur_Error_Info : 6|7@0+ (1,0) [0|127] ""  DUMMY_ECU

BO_ 1084 RMCU_EventMatrix3: 8 RMCU
 SG_ RMCU_TrqCtl_Fault_Sts : 55|1@0+ (1,0) [0|1] ""  DUMMY_ECU
 SG_ RMCU_TrqCtl_Error_Info : 54|3@0+ (1,0) [0|7] ""  DUMMY_ECU
 SG_ RMCU_Thermal_Fault_Sts : 39|1@0+ (1,0) [0|1] ""  DUMMY_ECU
 SG_ RMCU_Thermal_Error_Info : 38|15@0+ (1,0) [0|32767] ""  DUMMY_ECU
 SG_ RMCU_PosSen_Fault_Sts : 23|1@0+ (1,0) [0|1] ""  DUMMY_ECU
 SG_ RMCU_PosSen_Error_Info : 22|15@0+ (1,0) [0|32767] ""  DUMMY_ECU
 SG_ RMCU_IOHW_Fault_Sts : 7|1@0+ (1,0) [0|1] ""  DUMMY_ECU
 SG_ RMCU_IOHW_Error_Info : 6|15@0+ (1,0) [0|32767] ""  DUMMY_ECU

BO_ 1091 RMCU_EventMatrix4: 8 RMCU
 SG_ RMCU_FS_PhaCurMon_Error_Info : 28|4@0+ (1,0) [0|15] ""  DUMMY_ECU
 SG_ RMCU_FS_SOPMon_Error_Info : 48|5@0+ (1,0) [0|15] ""  DUMMY_ECU
 SG_ RMCU_FS_MCUMon_Error_Info : 53|4@0+ (1,0) [0|15] ""  DUMMY_ECU
 SG_ RMCU_FS_SBCMon_Error_Info : 42|4@0+ (1,0) [0|15] ""  DUMMY_ECU
 SG_ RMCU_FS_TempMon_Error_Info : 35|8@0+ (1,0) [0|255] ""  DUMMY_ECU
 SG_ RMCU_FS_SpdMon_Error_Info : 39|3@0+ (1,0) [0|7] ""  DUMMY_ECU
 SG_ RMCU_FS_TrqMon_Error_Info : 21|8@0+ (1,0) [0|255] ""  DUMMY_ECU
 SG_ RMCU_FS_HVMon_Error_Info : 6|8@0+ (1,0) [0|255] ""  DUMMY_ECU
 SG_ RMCU_FS_LVMon_Error_Info : 13|7@0+ (1,0) [0|127] ""  DUMMY_ECU
 SG_ RMCU_FS_SOPMonFault : 49|1@0+ (1,0) [0|1] ""  DUMMY_ECU
 SG_ RMCU_FS_MCUMonFault : 54|1@0+ (1,0) [0|1] ""  DUMMY_ECU
 SG_ RMCU_FS_SBCMonFault : 43|1@0+ (1,0) [0|1] ""  DUMMY_ECU
 SG_ RMCU_FS_TempMonFault : 36|1@0+ (1,0) [0|1] ""  DUMMY_ECU
 SG_ RMCU_FS_SpdMonFault : 24|1@0+ (1,0) [0|1] ""  DUMMY_ECU
 SG_ RMCU_FS_PhaCurMonFault : 29|1@0+ (1,0) [0|1] ""  DUMMY_ECU
 SG_ RMCU_FS_TrqMonFault : 22|1@0+ (1,0) [0|1] ""  DUMMY_ECU
 SG_ RMCU_FS_LVMonFault : 14|1@0+ (1,0) [0|1] ""  DUMMY_ECU
 SG_ RMCU_FS_HVFault : 7|1@0+ (1,0) [0|1] ""  DUMMY_ECU

BO_ 1178 RMCU_WarnMsg: 8 RMCU
 SG_ CRC_RMCU_WarnMsg : 7|8@0+ (1,0) [0|255] ""  CVC_P
 SG_ ALIVE_RMCU_WarnMsg : 11|4@0+ (1,0) [0|15] ""  CVC_P
 SG_ RMCU_Warning_Flag_1 : 12|1@0+ (1,0) [0|1] ""  CVC_P
 SG_ RMCU_Warning_Flag_2 : 13|1@0+ (1,0) [0|1] ""  CVC_P
 SG_ RMCU_Warning_Flag_3 : 14|1@0+ (1,0) [0|1] ""  CVC_P
 SG_ RMCU_Warning_Flag_4 : 15|1@0+ (1,0) [0|1] ""  CVC_P
 SG_ RMCU_Warning_Flag_5 : 16|1@0+ (1,0) [0|1] ""  CVC_P
 SG_ RMCU_Warning_Flag_6 : 17|1@0+ (1,0) [0|1] ""  CVC_P
 SG_ RMCU_Warning_Flag_7 : 18|1@0+ (1,0) [0|1] ""  CVC_P
 SG_ RMCU_Warning_Flag_8 : 19|1@0+ (1,0) [0|1] ""  CVC_P
 SG_ RMCU_Warning_Flag_9 : 20|1@0+ (1,0) [0|1] ""  CVC_P
 SG_ RMCU_Warning_Flag_10 : 21|1@0+ (1,0) [0|1] ""  CVC_P
 SG_ RMCU_Warning_Flag_11 : 22|1@0+ (1,0) [0|1] ""  CVC_P
 SG_ RMCU_Warning_Flag_12 : 23|1@0+ (1,0) [0|1] ""  CVC_P
 SG_ RMCU_Reserved_signal1 : 31|8@0+ (1,0) [0|255] ""  CVC_P
 SG_ RMCU_Reserved_signal2 : 39|8@0+ (1,0) [0|255] ""  CVC_P
 SG_ RMCU_Reserved_signal3 : 47|8@0+ (1,0) [0|255] ""  CVC_P
 SG_ RMCU_Reserved_signal4 : 55|8@0+ (1,0) [0|255] ""  CVC_P
 SG_ RMCU_Reserved_signal5 : 63|8@0+ (1,0) [0|255] ""  CVC_P

BO_ 661 POD_DCFC_Status: 12 POD_GW
 SG_ CRC_POD_DCFC_Status : 7|8@0+ (1,0) [0|255] ""  EVCC
 SG_ ALIVE_POD_DCFC_Status : 11|4@0+ (1,0) [0|15] ""  EVCC
 SG_ POD_DCFC_State_Contactor : 15|4@0+ (1,0) [0|15] ""  EVCC
 SG_ POD_DCFC_Sts_reversed0 : 23|8@0+ (1,0) [0|255] ""  EVCC
 SG_ POD_DCFC_Sts_reversed1 : 31|8@0+ (1,0) [0|255] ""  EVCC
 SG_ POD_DCFC_Sts_reversed2 : 39|8@0+ (1,0) [0|255] ""  EVCC
 SG_ POD_DCFC_Sts_reversed3 : 47|8@0+ (1,0) [0|255] ""  EVCC
 SG_ POD_DCFC_ChgPortVolt : 51|12@0+ (0.5,0) [0|1000] ""  EVCC
 SG_ POD_DCFC_Sts_reversed4 : 55|4@0+ (1,0) [0|15] ""  EVCC
 SG_ POD_tempHVBusNeg : 71|8@0+ (1,-30) [-30|150] "degC"  CVC_P,EVCC
 SG_ POD_tempHVBusPlus : 79|8@0+ (1,-30) [-30|150] "degC"  CVC_P,EVCC

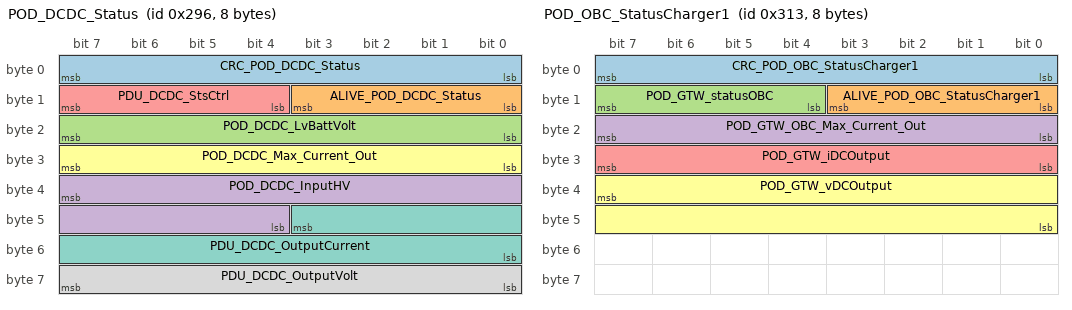
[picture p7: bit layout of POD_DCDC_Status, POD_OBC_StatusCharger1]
BO_ 662 POD_DCDC_Status: 8 POD_GW
 SG_ CRC_POD_DCDC_Status : 7|8@0+ (1,0) [0|255] ""  CVC_P,EVCC,PCU
 SG_ ALIVE_POD_DCDC_Status : 11|4@0+ (1,0) [0|15] ""  CVC_P,EVCC,PCU
 SG_ POD_DCDC_LvBattVolt : 23|8@0+ (0.1,0) [0|15] ""  CVC_P,EVCC
 SG_ POD_DCDC_InputHV : 39|12@0+ (0.5,0) [0|1000] "V"  CVC_P,EVCC
 SG_ PDU_DCDC_StsCtrl : 15|4@0+ (1,0) [0|15] ""  CVC_P,EVCC
 SG_ POD_DCDC_Max_Current_Out : 31|8@0+ (1,0) [0|250] ""  CVC_P,EVCC
 SG_ PDU_DCDC_OutputCurrent : 43|12@0+ (0.1,-100) [-100|300] "A"  CVC_P,EVCC,PCU
 SG_ PDU_DCDC_OutputVolt : 63|8@0+ (0.125,0) [0|31.875] "V"  CVC_P,EVCC,PCU

BO_ 663 POD_DCDC_EventMatrix: 8 POD_GW
 SG_ POD_DCDC_evt_BUS_OFF : 0|1@0+ (1,0) [0|1] ""  DUMMY_ECU
 SG_ POD_DCDC_evt_MIA : 1|1@0+ (1,0) [0|1] ""  DUMMY_ECU
 SG_ POD_DCDC_evt_E2E : 2|1@0+ (1,0) [0|1] ""  DUMMY_ECU
 SG_ POD_DCDC_evt_CalibFlt : 3|1@0+ (1,0) [0|1] ""  DUMMY_ECU
 SG_ POD_DCDC_evt_ExtMemFlt : 4|1@0+ (1,0) [0|1] ""  DUMMY_ECU
 SG_ POD_DCDC_evt_FaultLatchCircuit : 5|1@0+ (1,0) [0|1] ""  DUMMY_ECU
 SG_ POD_DCDC_evt_HVBat_VSensFail : 6|1@0+ (1,0) [0|1] ""  DUMMY_ECU
 SG_ POD_DCDC_evt_HVBat_OverVolt_SW : 7|1@0+ (1,0) [0|1] ""  DUMMY_ECU
 SG_ POD_DCDC_evt_HVBat_UnderVolt_SW : 8|1@0+ (1,0) [0|1] ""  DUMMY_ECU
 SG_ POD_DCDC_evt_LVOut_VSensFail : 9|1@0+ (1,0) [0|1] ""  DUMMY_ECU
 SG_ POD_DCDC_evt_LVBat_OverVolt_SW : 10|1@0+ (1,0) [0|1] ""  DUMMY_ECU
 SG_ POD_DCDC_evt_LVBat_UnderVolt_SW : 11|1@0+ (1,0) [0|1] ""  DUMMY_ECU
 SG_ POD_DCDC_evt_LVBat_VSensFail : 12|1@0+ (1,0) [0|1] ""  DUMMY_ECU
 SG_ POD_DCDC_evt_LV_RedundancyFlt : 13|1@0+ (1,0) [0|1] ""  DUMMY_ECU
 SG_ POD_DCDC_evt_LVOut_ISensFail : 14|1@0+ (1,0) [0|1] ""  DUMMY_ECU
 SG_ POD_DCDC_evt_LVOut_OverCurr_SW : 15|1@0+ (1,0) [0|1] ""  DUMMY_ECU
 SG_ POD_DCDC_evt_LVOut_RevrsCurr_SW : 16|1@0+ (1,0) [0|1] ""  DUMMY_ECU
 SG_ PDU_DCDC_evt_Heater_SensorFlt : 17|1@0+ (1,0) [0|1] ""  DUMMY_ECU
 SG_ POD_DCDC_evt_Mosfet_TSensFail : 18|1@0+ (1,0) [0|1] ""  DUMMY_ECU
 SG_ POD_DCDC_evt_Mosfet_OverTemp : 19|1@0+ (1,0) [0|1] ""  DUMMY_ECU
 SG_ PDU_DCDC_evt_Coldplate_TSensFail : 20|1@0+ (1,0) [0|1] ""  DUMMY_ECU
 SG_ PDU_DCDC_evt_ColdPlate_OverTemp : 21|1@0+ (1,0) [0|1] ""  DUMMY_ECU
 SG_ PDU_DCDC_evt_HeaterOverTemp : 22|1@0+ (1,0) [0|1] ""  DUMMY_ECU
 SG_ PDU_DCDC_evt_HeaterShortIGBTFlt : 23|1@0+ (1,0) [0|1] ""  DUMMY_ECU
 SG_ POD_DCDC_evt_LV_ShortOutputFlt : 24|1@0+ (1,0) [0|1] ""  DUMMY_ECU
 SG_ POD_DCDC_evt_reserved6 : 25|1@0+ (1,0) [0|1] ""  DUMMY_ECU
 SG_ POD_DCDC_evt_reserved5 : 26|1@0+ (1,0) [0|1] ""  DUMMY_ECU
 SG_ POD_DCDC_evt_PwrFail : 27|1@0+ (1,0) [0|1] ""  DUMMY_ECU
 SG_ POD_DCDC_evt_Mosfet_HighTemp : 28|1@0+ (1,0) [0|1] ""  DUMMY_ECU
 SG_ PDU_DCDC_evt_ColdPlate_HighTemp : 29|1@0+ (1,0) [0|1] ""  DUMMY_ECU
 SG_ POD_DCDC_evt_Unchargeable : 30|1@0+ (1,0) [0|1] ""  DUMMY_ECU
 SG_ POD_DCDC_evt_reserved0 : 31|1@0+ (1,0) [0|1] ""  DUMMY_ECU
 SG_ POD_DCDC_evt_reserved1 : 39|1@0+ (1,0) [0|1] ""  DUMMY_ECU
 SG_ POD_DCDC_evt_reserved2 : 47|1@0+ (1,0) [0|1] ""  DUMMY_ECU
 SG_ POD_DCDC_evt_reserved3 : 55|1@0+ (1,0) [0|1] ""  DUMMY_ECU
 SG_ POD_DCDC_evt_reserved4 : 63|1@0+ (1,0) [0|1] ""  DUMMY_ECU
 SG_ POD_DCDC_evt_SelfTestFlt : 38|1@0+ (1,0) [0|1] ""  DUMMY_ECU
 SG_ POD_DCDC_evt_PMICComFlt : 37|1@0+ (1,0) [0|1] ""  DUMMY_ECU
 SG_ POD_DCDC_evt_IOExpComFlt : 36|1@0+ (1,0) [0|1] ""  DUMMY_ECU
 SG_ POD_DCDC_evt_WdgFlt : 35|1@0+ (1,0) [0|1] ""  DUMMY_ECU
 SG_ POD_DCDC_evt_PFMFlt : 34|1@0+ (1,0) [0|1] ""  DUMMY_ECU
 SG_ POD_DCDC_evt_TCANFlt : 33|1@0+ (1,0) [0|1] ""  DUMMY_ECU
 SG_ POD_DCDC_evt_LVOut_OverCurr_CMP : 32|1@0+ (1,0) [0|1] ""  DUMMY_ECU
 SG_ POD_DCDC_evt_LVOut_RevrsCurr_CMP : 40|1@0+ (1,0) [0|1] ""  DUMMY_ECU
 SG_ POD_DCDC_evt_LVBat_OverVolt_CMP : 41|1@0+ (1,0) [0|1] ""  DUMMY_ECU
 SG_ POD_DCDC_evt_LVBat_UnderVolt_CMP : 42|1@0+ (1,0) [0|1] ""  DUMMY_ECU
 SG_ POD_DCDC_evt_HVBat_OverVolt_CMP : 43|1@0+ (1,0) [0|1] ""  DUMMY_ECU
 SG_ POD_DCDC_evt_HVBat_UnderVolt_CMP : 44|1@0+ (1,0) [0|1] ""  DUMMY_ECU
 SG_ POD_DCDC_evt_LVOut_OverCurr_HW : 45|1@0+ (1,0) [0|1] ""  DUMMY_ECU
 SG_ POD_DCDC_evt_LVOut_OverVolt_HW : 46|1@0+ (1,0) [0|1] ""  DUMMY_ECU
 SG_ PDU_DCDC_evt_LVOut_UnderVolt_HW : 54|1@0+ (1,0) [0|1] ""  DUMMY_ECU
 SG_ POD_DCDC_evt_AuxPwrFlt_HW : 53|1@0+ (1,0) [0|1] ""  DUMMY_ECU
 SG_ POD_DCDC_evt_LVOut_OverVolt_SW : 52|1@0+ (1,0) [0|1] ""  DUMMY_ECU
 SG_ PDU_DCDC_evt_LVOut_UnderVolt_SW : 51|1@0+ (1,0) [0|1] ""  DUMMY_ECU
 SG_ POD_DCDC_evt_GATEDRV_Flt : 48|1@0+ (1,0) [0|1] ""  DUMMY_ECU
 SG_ POD_DCDC_evt_OutFET_GATEDRV_Flt : 49|1@0+ (1,0) [0|1] ""  DUMMY_ECU
 SG_ POD_DCDC_evt_PT_DataInvalid : 50|1@0+ (1,0) [0|1] ""  DUMMY_ECU
 SG_ POD_evt_Pri_Temp_Redundancy_Flt : 62|1@0+ (1,0) [0|1] ""  DUMMY_ECU
 SG_ POD_DCDC_evt_Pmic_OverVoltFlt : 56|1@0+ (1,0) [0|1] ""  DUMMY_ECU
 SG_ POD_DCDC_evt_Pmic_UnderVoltFlt : 57|1@0+ (1,0) [0|1] ""  DUMMY_ECU
 SG_ POD_DCDC_evt_Pmic_DataWrongFlt : 58|1@0+ (1,0) [0|1] ""  DUMMY_ECU
 SG_ POD_DCDC_evt_reserved7 : 59|1@0+ (1,0) [0|1] ""  DUMMY_ECU
 SG_ POD_DCDC_evt_reserved8 : 60|1@0+ (1,0) [0|1] ""  DUMMY_ECU
 SG_ POD_DCDC_evt_reserved9 : 61|1@0+ (1,0) [0|1] ""  DUMMY_ECU

BO_ 664 POD_OBC_EventMatrix3: 8 POD_GW
 SG_ POD_OBC_evt_Invert_iDCIn_ocflt_s : 16|1@0+ (1,0) [0|1] ""  CVC_P
 SG_ POD_OBC_evt_Invert_vDCin_uvflt_s : 17|1@0+ (1,0) [0|1] ""  CVC_P
 SG_ POD_OBC_evt_Invert_vDCIn_ovflt_s : 18|1@0+ (1,0) [0|1] ""  CVC_P
 SG_ POD_OBC_evt_Invert_vACOut_ovflt_ : 19|1@0+ (1,0) [0|1] ""  CVC_P
 SG_ POD_OBC_evt_Invert_iACOut_ocflt_ : 20|1@0+ (1,0) [0|1] ""  CVC_P
 SG_ POD_OBC_evt_Invert_iACOut_o_0000 : 21|1@0+ (1,0) [0|1] ""  CVC_P
 SG_ POD_OBC_evt_Invert_vACOut_o_0000 : 22|1@0+ (1,0) [0|1] ""  CVC_P
 SG_ POD_OBC_evt_Invert_vACOut_uvflt_ : 23|1@0+ (1,0) [0|1] ""  CVC_P
 SG_ POD_OBC_evt_Invert_iDCIn_ocflt_c : 30|1@0+ (1,0) [0|1] ""  CVC_P
 SG_ POD_OBC_evt_Invert_vDCIn_ovflt_c : 31|1@0+ (1,0) [0|1] ""  CVC_P
 SG_ POD_OBC_evt_Invert_vDClink_uvflt : 32|1@0+ (1,0) [0|1] ""  CVC_P
 SG_ POD_OBC_evt_Invert_vDClink_ovflt : 33|1@0+ (1,0) [0|1] ""  CVC_P
 SG_ POD_OBC_evt_Invert_vDClink__0000 : 34|1@0+ (1,0) [0|1] ""  CVC_P
 SG_ POD_OBC_evt_Invert_vACOut_Sensor : 35|1@0+ (1,0) [0|1] ""  CVC_P
 SG_ POD_OBC_Inv_iACOut_ImBalFlt : 36|1@0+ (1,0) [0|1] ""  CVC_P
 SG_ POD_OBC_Inv_iACOut_ImBalWrn : 37|1@0+ (1,0) [0|1] ""  CVC_P
 SG_ POD_OBC_Inv_FET_OverTempFlt : 24|1@0+ (1,0) [0|1] ""  CVC_P
 SG_ POD_OBC_Inv_FET_TempWrn : 25|1@0+ (1,0) [0|1] ""  CVC_P
 SG_ POD_OBC_Inv_FET_UnderTempFlt : 26|1@0+ (1,0) [0|1] ""  CVC_P
 SG_ POD_OBC_Inv_Coolant_OverTempFlt : 27|1@0+ (1,0) [0|1] ""  CVC_P
 SG_ POD_OBC_Inv_Coolant_TempWrn : 28|1@0+ (1,0) [0|1] ""  CVC_P
 SG_ POD_OBC_Inv_Coolant_UnderTempFlt : 29|1@0+ (1,0) [0|1] ""  CVC_P

BO_ 695 POD_OBC_StatusDischage: 16 POD_GW
 SG_ CRC_POD_OBC_StatusDischage : 7|8@0+ (1,0) [0|255] ""  CVC_P,EVCC,PCU
 SG_ ALIVE_POD_OBC_StatusDischage : 11|4@0+ (1,0) [0|15] ""  CVC_P,EVCC,PCU
 SG_ POD_OBC_Dischage_vDCInput : 19|12@0+ (0.5,0) [0|1000] "V"  CVC_P,EVCC
 SG_ POD_OBC_Dischage_iDCinput : 119|11@0+ (0.1,-50) [-50|100] "A"  CVC_P,EVCC
 SG_ POD_OBC_Dischage_vACOutput : 45|10@0+ (0.5,0) [0|500] "V"  CVC_P,EVCC
 SG_ POD_OBC_Dischage_iACOutput : 57|10@0+ (0.1,0) [0|100] "A"  CVC_P,EVCC
 SG_ POD_OBC_BMS_MaxOutputCurAC : 79|10@0+ (0.1,0) [0|100] "A"  CVC_P,EVCC,PCU
 SG_ POD_OBC_CVC_ACDisChgVoltAllow : 95|16@0+ (0.1,0) [0|1000] "V"  CVC_P,EVCC,PCU
 SG_ POD_OBC_Invert_Power : 111|8@0+ (0.1,0) [0|25] "Kw"  CVC_P,EVCC,PCU

BO_ 787 POD_OBC_StatusCharger1: 8 POD_GW
 SG_ CRC_POD_OBC_StatusCharger1 : 7|8@0+ (1,0) [0|255] ""  CVC_P,EVCC
 SG_ ALIVE_POD_OBC_StatusCharger1 : 11|4@0+ (1,0) [0|15] ""  CVC_P,EVCC
 SG_ POD_GTW_statusOBC : 15|4@0+ (1,0) [0|15] ""  CVC_P,EVCC
 SG_ POD_GTW_OBC_Max_Current_Out : 23|8@0+ (1,0) [0|64] ""  CVC_P,EVCC
 SG_ POD_GTW_iDCOutput : 31|8@0+ (1,-50) [-50|50] "A"  CVC_P,EVCC
 SG_ POD_GTW_vDCOutput : 39|16@0+ (0.0625,0) [0|512] "V"  CVC_P,EVCC

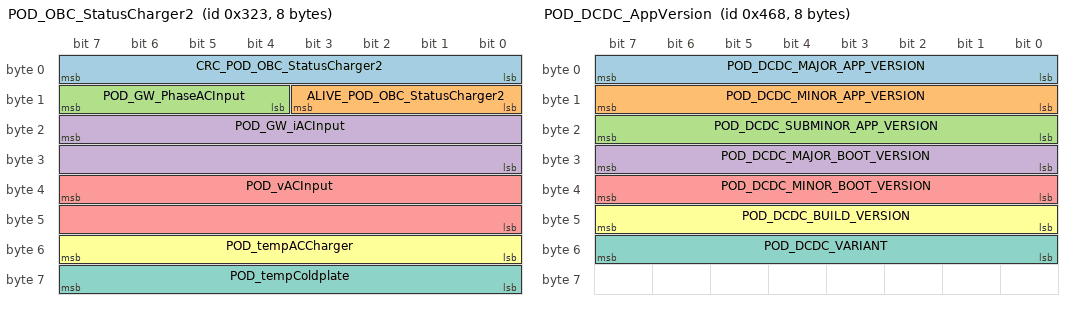
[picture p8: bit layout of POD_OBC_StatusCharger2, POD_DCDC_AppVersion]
BO_ 803 POD_OBC_StatusCharger2: 8 POD_GW
 SG_ CRC_POD_OBC_StatusCharger2 : 7|8@0+ (1,0) [0|255] ""  CVC_P,EVCC
 SG_ ALIVE_POD_OBC_StatusCharger2 : 11|4@0+ (1,0) [0|15] ""  CVC_P,EVCC
 SG_ POD_GW_PhaseACInput : 15|4@0+ (1,0) [0|3] ""  CVC_P,EVCC
 SG_ POD_GW_iACInput : 23|16@0+ (0.0625,0) [0|60] "amps"  CVC_P,EVCC
 SG_ POD_vACInput : 39|16@0+ (0.0625,0) [0|512] "V"  CVC_P,EVCC
 SG_ POD_tempACCharger : 55|8@0+ (1,-40) [-40|150] "degC"  CVC_P,EVCC
 SG_ POD_tempColdplate : 63|8@0+ (1,-40) [-40|150] "degC"  CVC_P,EVCC

BO_ 870 POD_DCDC_Thermal: 12 POD_GW
 SG_ PDU_DCDC_Thermal_CpltTemp : 7|8@0+ (1,-40) [-40|215] "degC"  CVC_P,EVCC
 SG_ PDU_DCDC_Thermal_IntTemp : 15|8@0+ (1,-40) [-40|215] "degC"  CVC_P,EVCC
 SG_ POD_DCDC_Thermal_NegBBTemp : 23|8@0+ (1,-40) [-40|215] ""  CVC_P,EVCC
 SG_ POD_DCDC_Thermal_PosBBTemp : 31|8@0+ (1,-40) [-40|215] ""  CVC_P,EVCC
 SG_ POD_DCDC_Thermal_reversed0 : 39|8@0+ (1,-40) [-40|215] ""  CVC_P,EVCC
 SG_ POD_DCDC_Thermal_reversed1 : 47|8@0+ (1,-40) [-40|215] ""  CVC_P,EVCC
 SG_ PDU_DCDC_Thermal_CoolPwrReq : 55|8@0+ (0.1,0) [0|10] "KW"  CVC_P,EVCC
 SG_ PDU_DCDC_Thermal_FlowRateReq : 63|8@0+ (1,0) [0|50] "l/min"  CVC_P,EVCC
 SG_ POD_DCDC_Thermal_PriFetTemp1 : 95|8@0+ (1,-40) [-40|215] ""  CVC_P,EVCC
 SG_ POD_DCDC_Thermal_PriFetTemp2 : 87|8@0+ (1,-40) [-40|215] ""  CVC_P,EVCC
 SG_ POD_DCDC_Thermal_OutFetTemp : 79|8@0+ (1,-40) [-40|215] ""  CVC_P,EVCC
 SG_ POD_DCDC_Thermal_SecFetTemp : 71|8@0+ (1,-40) [-40|215] ""  CVC_P,EVCC

BO_ 1128 POD_DCDC_AppVersion: 8 POD_GW
 SG_ POD_DCDC_MAJOR_APP_VERSION : 7|8@0+ (1,0) [0|255] ""  DUMMY_ECU
 SG_ POD_DCDC_MINOR_APP_VERSION : 15|8@0+ (1,0) [0|255] ""  DUMMY_ECU
 SG_ POD_DCDC_SUBMINOR_APP_VERSION : 23|8@0+ (1,0) [0|255] ""  DUMMY_ECU
 SG_ POD_DCDC_MAJOR_BOOT_VERSION : 31|8@0+ (1,0) [0|255] ""  DUMMY_ECU
 SG_ POD_DCDC_MINOR_BOOT_VERSION : 39|8@0+ (1,0) [0|255] ""  DUMMY_ECU
 SG_ POD_DCDC_BUILD_VERSION : 47|8@0+ (1,0) [0|255] ""  DUMMY_ECU
 SG_ POD_DCDC_VARIANT : 55|8@0+ (1,0) [0|255] ""  DUMMY_ECU

BO_ 1141 POD_DCFC_EventMatrix: 8 POD_GW
 SG_ POD_DCFC_evt_NegBB_TempSensFlt : 0|1@0+ (1,0) [0|1] ""  DUMMY_ECU
 SG_ POD_DCFC_evt_PosBB_TempSensFlt : 1|1@0+ (1,0) [0|1] ""  DUMMY_ECU
 SG_ POD_DCFC_evt_Contactor_Welded : 2|1@0+ (1,0) [0|1] ""  DUMMY_ECU
 SG_ POD_DCFC_evt_Contactor_StuckOpen : 3|1@0+ (1,0) [0|1] ""  DUMMY_ECU
 SG_ POD_DCFC_evt_ChgPort_OverVolt_SW : 4|1@0+ (1,0) [0|1] ""  DUMMY_ECU
 SG_ POD_DCFC_evt_NegBB_OverTempFlt : 5|1@0+ (1,0) [0|1] ""  DUMMY_ECU
 SG_ POD_DCFC_evt_PosBB_OverTempFlt : 6|1@0+ (1,0) [0|1] ""  DUMMY_ECU
 SG_ POD_DCFC_evt_ChgPort_UnderVolt_S : 7|1@0+ (1,0) [0|1] ""  DUMMY_ECU
 SG_ POD_DCFC_evt_reserved7 : 8|1@0+ (1,0) [0|1] ""  DUMMY_ECU
 SG_ POD_DCFC_evt_MIA : 9|1@0+ (1,0) [0|1] ""  DUMMY_ECU
 SG_ POD_DCFC_evt_E2E : 10|1@0+ (1,0) [0|1] ""  DUMMY_ECU
 SG_ POD_DCFC_evt_ChgPort_VSensFlt : 11|1@0+ (1,0) [0|1] ""  DUMMY_ECU
 SG_ POD_DCFC_evt_CoilPwrFlt_HW : 12|1@0+ (1,0) [0|1] ""  DUMMY_ECU
 SG_ POD_DCFC_evt_reserved0 : 15|1@0+ (1,0) [0|1] ""  DUMMY_ECU
 SG_ POD_DCFC_evt_reserved1 : 23|1@0+ (1,0) [0|1] ""  DUMMY_ECU
 SG_ POD_DCFC_evt_reserved2 : 31|1@0+ (1,0) [0|1] ""  DUMMY_ECU
 SG_ POD_DCFC_evt_reserved3 : 39|8@0+ (1,0) [0|255] ""  DUMMY_ECU
 SG_ POD_DCFC_evt_reserved4 : 47|8@0+ (1,0) [0|255] ""  DUMMY_ECU
 SG_ POD_DCFC_evt_reserved5 : 55|8@0+ (1,0) [0|255] ""  DUMMY_ECU
 SG_ POD_DCFC_evt_reserved6 : 63|8@0+ (1,0) [0|255] ""  DUMMY_ECU
 SG_ POD_DCFC_evt_reserved9 : 13|1@0+ (1,0) [0|1] ""  DUMMY_ECU
 SG_ POD_DCFC_evt_reserved8 : 14|1@0+ (1,0) [0|1] ""  DUMMY_ECU
 SG_ POD_DCFC_evt_MCUPWRFAIL : 16|1@0+ (1,0) [0|1] ""  DUMMY_ECU
 SG_ POD_DCFC_evt_EXTMEMFAIL : 17|1@0+ (1,0) [0|1] ""  DUMMY_ECU
 SG_ POD_DCFC_evt_BUSOFF : 18|1@0+ (1,0) [0|1] ""  DUMMY_ECU
 SG_ POD_DCFC_evt_ChgPort_OverVolt_CM : 19|1@0+ (1,0) [0|1] ""  DUMMY_ECU
 SG_ POD_DCFC_evt_ChgPort_UnderVolt_C : 20|1@0+ (1,0) [0|1] ""  DUMMY_ECU
 SG_ POD_DCFC_evt_ChgPort_RevrsPolari : 21|1@0+ (1,0) [0|1] ""  DUMMY_ECU

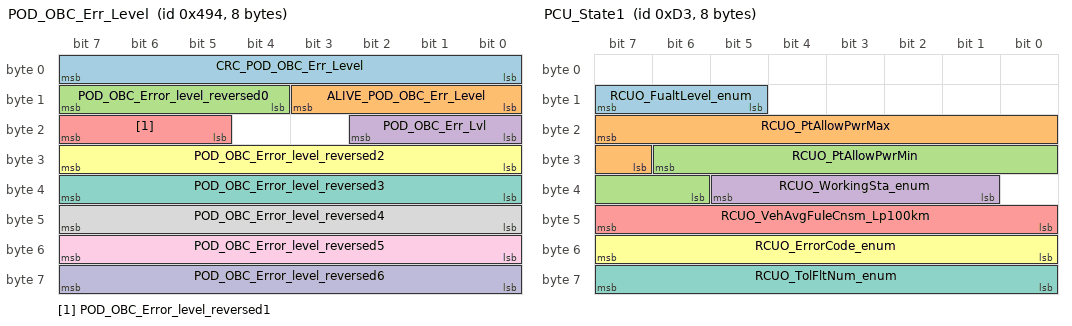
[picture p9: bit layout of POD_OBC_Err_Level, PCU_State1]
BO_ 1172 POD_OBC_Err_Level: 8 POD_GW
 SG_ CRC_POD_OBC_Err_Level : 7|8@0+ (1,0) [0|255] ""  EVCC
 SG_ ALIVE_POD_OBC_Err_Level : 11|4@0+ (1,0) [0|15] ""  EVCC
 SG_ POD_OBC_Error_level_reversed0 : 15|4@0+ (1,0) [0|15] ""  EVCC
 SG_ POD_OBC_Err_Lvl : 18|3@0+ (1,0) [0|7] ""  EVCC
 SG_ POD_OBC_Error_level_reversed1 : 23|3@0+ (1,0) [0|7] ""  EVCC
 SG_ POD_OBC_Error_level_reversed2 : 31|8@0+ (1,0) [0|255] ""  EVCC
 SG_ POD_OBC_Error_level_reversed3 : 39|8@0+ (1,0) [0|255] ""  EVCC
 SG_ POD_OBC_Error_level_reversed4 : 47|8@0+ (1,0) [0|255] ""  EVCC
 SG_ POD_OBC_Error_level_reversed5 : 55|8@0+ (1,0) [0|255] ""  EVCC
 SG_ POD_OBC_Error_level_reversed6 : 63|8@0+ (1,0) [0|255] ""  EVCC

BO_ 1864 POD_OBC_AppVersion: 16 POD_GW
 SG_ POD_OBC_Major_App_Ver : 7|8@0+ (1,0) [0|255] ""  DUMMY_ECU
 SG_ POD_OBC_Minor_App_Ver : 15|8@0+ (1,0) [0|255] ""  DUMMY_ECU
 SG_ POD_OBC_Subminor_App_Ver : 23|8@0+ (1,0) [0|255] ""  DUMMY_ECU
 SG_ POD_OBC_Major_Boot_Ver : 31|8@0+ (1,0) [0|255] ""  DUMMY_ECU
 SG_ POD_OBC_Minor_Boot_Ver : 39|8@0+ (1,0) [0|255] ""  DUMMY_ECU
 SG_ POD_OBC_Subminor_Boot_Ver : 47|8@0+ (1,0) [0|255] ""  DUMMY_ECU
 SG_ POD_OBC_Variant : 51|4@0+ (1,0) [0|3] ""  DUMMY_ECU
 SG_ POD_tempPfcMosfet1 : 87|8@0+ (1,-40) [-40|150] ""  DUMMY_ECU
 SG_ POD_tempPfcMosfet2 : 79|8@0+ (1,-40) [-40|150] ""  DUMMY_ECU
 SG_ POD_tempDchvPri : 71|8@0+ (1,-40) [-40|150] ""  DUMMY_ECU
 SG_ POD_tempDchvSec : 63|8@0+ (1,-40) [-40|150] ""  DUMMY_ECU
 SG_ POD_OBC_DCLinkVolt : 95|10@0+ (1,0) [0|1000] "V"  DUMMY_ECU

BO_ 1870 POD_OBC_EventMatrix: 8 POD_GW
 SG_ POD_OBC_evt_iLine1SensorErr : 0|1@0+ (1,0) [0|1] ""  DUMMY_ECU
 SG_ POD_OBC_evt_fLineUFFlt : 2|1@0+ (1,0) [0|1] ""  DUMMY_ECU
 SG_ POD_OBC_evt_fLineOFFlt : 3|1@0+ (1,0) [0|1] ""  DUMMY_ECU
 SG_ POD_OBC_evt_fault_latch : 4|1@0+ (1,0) [0|1] ""  DUMMY_ECU
 SG_ POD_OBC_evt_eStopFlt : 5|1@0+ (1,0) [0|1] ""  DUMMY_ECU
 SG_ POD_OBC_evt_iLineImbalWrn : 8|1@0+ (1,0) [0|1] ""  DUMMY_ECU
 SG_ POD_OBC_evt_iLineImbalFlt : 9|1@0+ (1,0) [0|1] ""  DUMMY_ECU
 SG_ POD_OBC_evt_iline_ocflt_sw_rms : 10|1@0+ (1,0) [0|1] ""  DUMMY_ECU
 SG_ POD_OBC_evt_iline_ocflt_hw_trig : 11|1@0+ (1,0) [0|1] ""  DUMMY_ECU
 SG_ POD_OBC_evt_iline_ocflt_cmp_trig : 12|1@0+ (1,0) [0|1] ""  DUMMY_ECU
 SG_ POD_OBC_evt_iLine2SensorErr : 15|1@0+ (1,0) [0|1] ""  DUMMY_ECU
 SG_ POD_OBC_evt_pfcerr : 16|1@0+ (1,0) [0|1] ""  DUMMY_ECU
 SG_ POD_OBC_evt_iOutSensorErr : 18|1@0+ (1,0) [0|1] ""  DUMMY_ECU
 SG_ POD_OBC_evt_iOutOCFlt_SW : 19|1@0+ (1,0) [0|1] ""  DUMMY_ECU
 SG_ POD_OBC_evt_iOutOCFlt_HW : 20|1@0+ (1,0) [0|1] ""  DUMMY_ECU
 SG_ POD_OBC_evt_iOutOCFlt_CMP : 21|1@0+ (1,0) [0|1] ""  DUMMY_ECU
 SG_ POD_OBC_evt_iOutNEGOCFlt_HW : 22|1@0+ (1,0) [0|1] ""  DUMMY_ECU
 SG_ POD_OBC_evt_iOutNEGOCFlt_CMP : 23|1@0+ (1,0) [0|1] ""  DUMMY_ECU
 SG_ POD_OBC_evt_secCurrFlt_SW : 24|1@0+ (1,0) [0|1] ""  DUMMY_ECU
 SG_ POD_OBC_evt_secCurrFlt_CMP : 26|1@0+ (1,0) [0|1] ""  DUMMY_ECU
 SG_ POD_OBC_evt_priCurrFlt_SW : 27|1@0+ (1,0) [0|1] ""  DUMMY_ECU
 SG_ POD_OBC_evt_priCurrFlt_CMP : 29|1@0+ (1,0) [0|1] ""  DUMMY_ECU
 SG_ POD_OBC_evt_BusOff : 30|1@0+ (1,0) [0|1] ""  DUMMY_ECU
 SG_ POD_OBC_evt_Coolant_Temp_Warn : 32|1@0+ (1,0) [0|1] ""  DUMMY_ECU
 SG_ POD_OBC_evt_Coolant_OverTemp : 33|1@0+ (1,0) [0|1] ""  DUMMY_ECU
 SG_ POD_OBC_evt_PwrOutOPFLt : 34|1@0+ (1,0) [0|1] ""  DUMMY_ECU
 SG_ POD_OBC_evt_PT_mia : 35|1@0+ (1,0) [0|1] ""  DUMMY_ECU
 SG_ POD_OBC_evt_PT_DataInvalid : 36|1@0+ (1,0) [0|1] ""  DUMMY_ECU
 SG_ POD_OBC_evt_PT_ChsFlt : 37|1@0+ (1,0) [0|1] ""  DUMMY_ECU
 SG_ POD_OBC_evt_PT_AlvFlt : 38|1@0+ (1,0) [0|1] ""  DUMMY_ECU
 SG_ POD_OBC_evt_dchvErr : 39|1@0+ (1,0) [0|1] ""  DUMMY_ECU
 SG_ POD_OBC_evt_vDCLinkOVFlt_HW : 40|1@0+ (1,0) [0|1] ""  DUMMY_ECU
 SG_ POD_OBC_evt_FET_UnderTemp : 42|1@0+ (1,0) [0|1] ""  DUMMY_ECU
 SG_ POD_OBC_evt_FET_Temp_Warn : 43|1@0+ (1,0) [0|1] ""  DUMMY_ECU
 SG_ POD_OBC_evt_FET_Temp_SensorFlt : 44|1@0+ (1,0) [0|1] ""  DUMMY_ECU
 SG_ POD_OBC_evt_FET_OverTemp : 45|1@0+ (1,0) [0|1] ""  DUMMY_ECU
 SG_ POD_OBC_evt_Coolant_UnderTemp : 46|1@0+ (1,0) [0|1] ""  DUMMY_ECU
 SG_ POD_OBC_evt_Coolant_Temp_SensorF : 47|1@0+ (1,0) [0|1] ""  DUMMY_ECU
 SG_ POD_OBC_evt_vout_ovflt_cmp_trig : 48|1@0+ (1,0) [0|1] ""  DUMMY_ECU
 SG_ POD_OBC_evt_vLineUVFlt : 49|1@0+ (1,0) [0|1] ""  DUMMY_ECU
 SG_ POD_OBC_evt_vLineOVFlt : 50|1@0+ (1,0) [0|1] ""  DUMMY_ECU
 SG_ POD_OBC_evt_vDCLinkUVFlt : 53|1@0+ (1,0) [0|1] ""  DUMMY_ECU
 SG_ POD_OBC_evt_vDCLinkPchgFail : 54|1@0+ (1,0) [0|1] ""  DUMMY_ECU
 SG_ POD_OBC_evt_vDCLinkOVFlt_SW : 55|1@0+ (1,0) [0|1] ""  DUMMY_ECU
 SG_ POD_OBC_evt_vout_uvflt_sw_trig : 57|1@0+ (1,0) [0|1] ""  DUMMY_ECU
 SG_ POD_OBC_evt_Vout_SensorErr : 58|1@0+ (1,0) [0|1] ""  DUMMY_ECU
 SG_ POD_OBC_evt_vout_ovflt_sw_trig : 59|1@0+ (1,0) [0|1] ""  DUMMY_ECU
 SG_ POD_OBC_evt_vout_ovflt_hw_trig : 60|1@0+ (1,0) [0|1] ""  DUMMY_ECU
 SG_ POD_OBC_evt_SFT_PMICFail : 1|1@0+ (1,0) [0|1] ""  DUMMY_ECU
 SG_ POD_OBC_evt_SFT_PFMFail : 6|1@0+ (1,0) [0|1] ""  DUMMY_ECU
 SG_ POD_OBC_evt_SFT_MemFail : 7|1@0+ (1,0) [0|1] ""  DUMMY_ECU
 SG_ POD_OBC_evt_SFT_ExtWDGFail : 13|1@0+ (1,0) [0|1] ""  DUMMY_ECU
 SG_ POD_OBC_evt_SFT_ClockFail : 14|1@0+ (1,0) [0|1] ""  DUMMY_ECU
 SG_ POD_OBC_evt_SFT_ADCFail : 17|1@0+ (1,0) [0|1] ""  DUMMY_ECU
 SG_ POD_OBC_evt_ExtMem_Flt : 25|1@0+ (1,0) [0|1] ""  DUMMY_ECU
 SG_ POD_OBC_evt_Threscheck_Flt : 28|1@0+ (1,0) [0|1] ""  DUMMY_ECU
 SG_ POD_OBC_evt_SWData_Corrupt : 31|1@0+ (1,0) [0|1] ""  DUMMY_ECU
 SG_ POD_OBC_evt_SOPT_Flt : 41|1@0+ (1,0) [0|1] ""  DUMMY_ECU
 SG_ POD_OBC_evt_iline_ocflt_sw_peak : 51|1@0+ (1,0) [0|1] ""  DUMMY_ECU
 SG_ POD_OBC_evt_iOutNEGOCFlt_SW : 52|1@0+ (1,0) [0|1] ""  DUMMY_ECU

BO_ 341 POD_DCDC_Error_Level: 12 POD_GW
 SG_ CRC_POD_DCDC_Error_Level : 7|8@0+ (1,0) [0|255] ""  CVC_P,EVCC
 SG_ ALIVE_POD_DCDC_Error_Level : 11|4@0+ (1,0) [0|15] ""  CVC_P,EVCC
 SG_ POD_DCDC_Error_level_reversed0 : 15|4@0+ (1,0) [0|15] ""  CVC_P,EVCC
 SG_ POD_DCDC_Err_Lvl : 18|3@0+ (1,0) [0|7] ""  CVC_P,EVCC
 SG_ POD_DCFC_Err_Lvl : 66|3@0+ (1,0) [0|7] ""  CVC_P,EVCC
 SG_ POD_DCDC_Error_level_reversed1 : 23|3@0+ (1,0) [0|7] ""  CVC_P,EVCC
 SG_ POD_DCDC_Error_level_reversed2 : 31|8@0+ (1,0) [0|255] ""  CVC_P,EVCC
 SG_ POD_DCDC_Error_level_reversed3 : 39|8@0+ (1,0) [0|255] ""  CVC_P,EVCC
 SG_ POD_DCDC_Error_level_reversed4 : 47|8@0+ (1,0) [0|255] ""  CVC_P,EVCC
 SG_ POD_DCDC_Error_level_reversed5 : 55|8@0+ (1,0) [0|255] ""  CVC_P,EVCC
 SG_ POD_DCDC_Error_level_reversed6 : 63|8@0+ (1,0) [0|255] ""  CVC_P,EVCC

BO_ 211 PCU_State1: 8 PCU
 SG_ RCUO_FualtLevel_enum : 15|3@0+ (1,0) [0|7] ""  CVC_P,EVCC,RMCU
 SG_ RCUO_PtAllowPwrMax : 23|9@0+ (1,0) [0|511] "kW"  CVC_P,EVCC,RMCU
 SG_ RCUO_PtAllowPwrMin : 30|9@0+ (1,0) [0|511] "kW"  CVC_P,EVCC,RMCU
 SG_ RCUO_WorkingSta_enum : 37|5@0+ (1,0) [0|31] ""  CVC_P,EVCC,RMCU
 SG_ RCUO_VehAvgFuleCnsm_Lp100km : 47|8@0+ (0.1,0) [0|25.5] "km/L"  CVC_P
 SG_ RCUO_ErrorCode_enum : 55|8@0+ (1,0) [0|255] ""  CVC_P
 SG_ RCUO_TolFltNum_enum : 63|8@0+ (1,0) [0|255] ""  CVC_P

BO_ 298 PCU_State2: 12 PCU
 SG_ RCUO_RCUActOutpPwr_kW : 23|9@0+ (1,0) [0|511] "kW"  CVC_P
 SG_ PCU_FaultSts : 30|5@0+ (1,0) [0|31] ""  CVC_P
 SG_ PCU_FastTorqueFlag : 25|1@0+ (1,0) [0|1] ""  CVC_P
 SG_ PCU_CVC_ActvDischg_Sts : 39|2@0+ (1,0) [0|3] ""  CVC_P
 SG_ PCU_CVC_GenVoltAct : 37|14@0+ (0.1,0) [0|1500] "V"  CVC_P
 SG_ PCU_CVC_GenCurrAct : 55|16@0+ (0.1,-3276.8) [-3276.8|3276.7] "A"  CVC_P
 SG_ PCU_EngineFuelLvl : 71|10@0+ (0.1,0) [0|100] "%"  CVC_P
 SG_ PCU_LowOilAlert : 77|2@0+ (1,0) [0|3] ""  CVC_P
 SG_ PCU_FlowRate_Req : 87|8@0+ (1,0) [0|50] "l/min"  CVC_P
 SG_ EMS_ElectricFan_Req : 95|8@0+ (1,0) [0|100] "%"  CVC_P

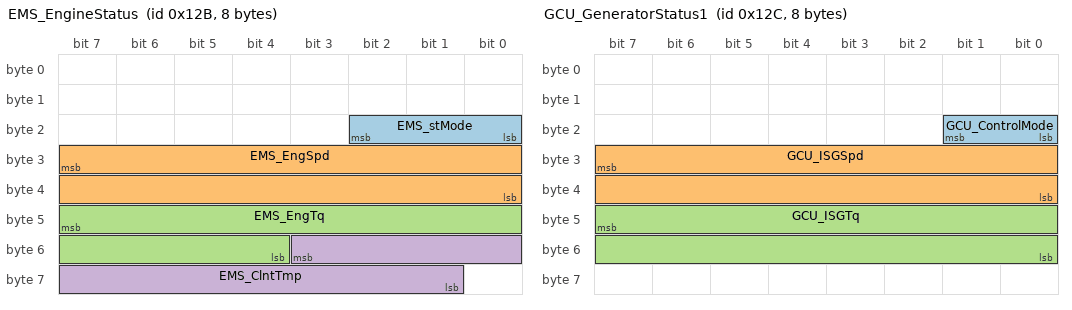
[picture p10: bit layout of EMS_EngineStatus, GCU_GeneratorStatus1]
BO_ 299 EMS_EngineStatus: 8 PCU
 SG_ EMS_stMode : 18|3@0+ (1,0) [0|7] ""  CVC_P
 SG_ EMS_EngSpd : 31|16@0+ (0.25,0) [0|16383.8] "rpm"  CVC_P
 SG_ EMS_EngTq : 47|12@0+ (0.5,-500) [-500|1547] "Nm"  CVC_P
 SG_ EMS_ClntTmp : 51|11@0+ (0.1,-36.8) [-36.8|137.2] "Degree C"  CVC_P

BO_ 300 GCU_GeneratorStatus1: 8 PCU
 SG_ GCU_ControlMode : 17|2@0+ (1,0) [0|3] ""  CVC_P
 SG_ GCU_ISGSpd : 31|16@0+ (1,-20000) [-20000|40000] "rpm"  CVC_P
 SG_ GCU_ISGTq : 47|16@0+ (0.1,-100) [-100|600] "Nm"  CVC_P

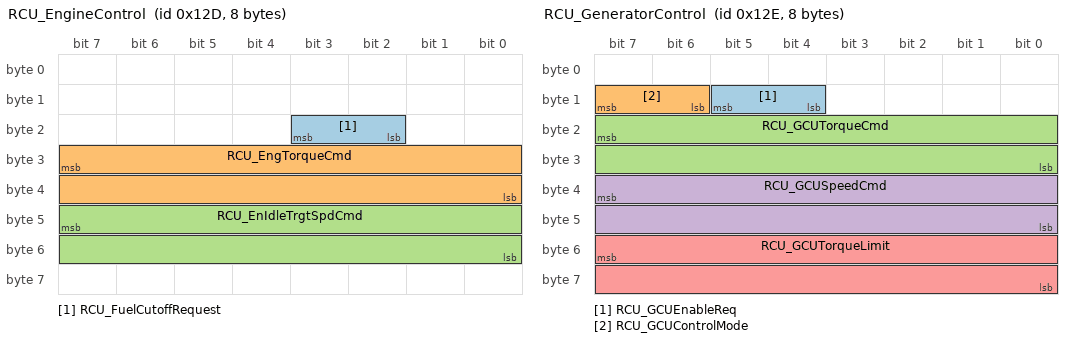
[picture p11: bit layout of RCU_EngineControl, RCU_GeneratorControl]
BO_ 301 RCU_EngineControl: 8 PCU
 SG_ RCU_FuelCutoffRequest : 19|2@0+ (1,0) [0|3] ""  CVC_P
 SG_ RCU_EngTorqueCmd : 31|16@0+ (0.1,-100) [-100|600] "Nm"  CVC_P
 SG_ RCU_EnIdleTrgtSpdCmd : 47|16@0+ (1,0) [0|8000] "rpm"  CVC_P

BO_ 302 RCU_GeneratorControl: 8 PCU
 SG_ RCU_GCUEnableReq : 13|2@0+ (1,0) [0|3] ""  CVC_P
 SG_ RCU_GCUControlMode : 15|2@0+ (1,0) [0|3] ""  CVC_P
 SG_ RCU_GCUTorqueCmd : 23|16@0+ (0.1,-100) [-100|600] "Nm"  CVC_P
 SG_ RCU_GCUSpeedCmd : 39|16@0+ (1,-20000) [-20000|40000] "rpm"  CVC_P
 SG_ RCU_GCUTorqueLimit : 55|16@0+ (0.1,0) [0|600] "Nm"  CVC_P

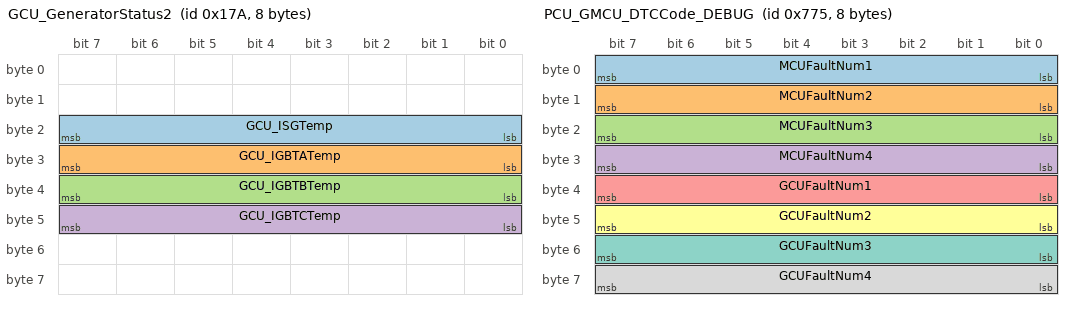
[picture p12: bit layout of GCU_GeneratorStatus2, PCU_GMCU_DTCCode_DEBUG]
BO_ 378 GCU_GeneratorStatus2: 8 PCU
 SG_ GCU_ISGTemp : 23|8@0+ (1,-40) [-40|210] "Degree C"  DUMMY_ECU
 SG_ GCU_IGBTATemp : 31|8@0+ (1,-40) [-40|210] "Degree C"  DUMMY_ECU
 SG_ GCU_IGBTBTemp : 39|8@0+ (1,-40) [-40|210] "Degree C"  DUMMY_ECU
 SG_ GCU_IGBTCTemp : 47|8@0+ (1,-40) [-40|210] "Degree C"  DUMMY_ECU

BO_ 1909 PCU_GMCU_DTCCode_DEBUG: 8 PCU
 SG_ MCUFaultNum1 : 7|8@0+ (1,0) [0|255] ""  DUMMY_ECU
 SG_ MCUFaultNum2 : 15|8@0+ (1,0) [0|255] ""  DUMMY_ECU
 SG_ MCUFaultNum3 : 23|8@0+ (1,0) [0|255] ""  DUMMY_ECU
 SG_ MCUFaultNum4 : 31|8@0+ (1,0) [0|255] ""  DUMMY_ECU
 SG_ GCUFaultNum1 : 39|8@0+ (1,0) [0|255] ""  DUMMY_ECU
 SG_ GCUFaultNum2 : 47|8@0+ (1,0) [0|255] ""  DUMMY_ECU
 SG_ GCUFaultNum3 : 55|8@0+ (1,0) [0|255] ""  DUMMY_ECU
 SG_ GCUFaultNum4 : 63|8@0+ (1,0) [0|255] ""  DUMMY_ECU

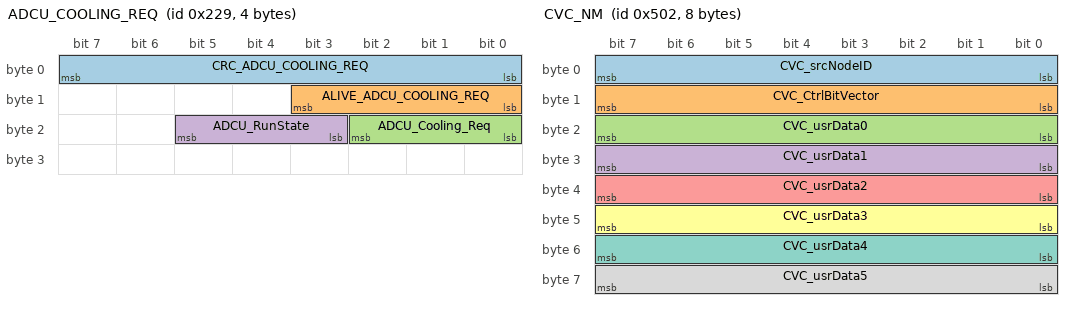
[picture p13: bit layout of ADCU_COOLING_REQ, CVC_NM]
BO_ 553 ADCU_COOLING_REQ: 4 ADCU_P
 SG_ CRC_ADCU_COOLING_REQ : 7|8@0+ (1,0) [0|255] ""  CVC_P
 SG_ ALIVE_ADCU_COOLING_REQ : 11|4@0+ (1,0) [0|15] ""  CVC_P
 SG_ ADCU_Cooling_Req : 18|3@0+ (1,0) [0|3] ""  CVC_P
 SG_ ADCU_RunState : 21|3@0+ (1,0) [0|7] ""  CVC_P

BO_ 1282 CVC_NM: 8 CVC_P
 SG_ CVC_srcNodeID : 7|8@0+ (1,0) [0|255] ""  BMS,EVCC,FMCU,RMCU,POD_GW,PCU,ADCU_P
 SG_ CVC_CtrlBitVector : 15|8@0+ (1,0) [0|255] ""  BMS,EVCC,FMCU,RMCU,POD_GW,PCU,ADCU_P
 SG_ CVC_usrData0 : 23|8@0+ (1,0) [0|255] ""  BMS,EVCC,FMCU,RMCU,POD_GW,PCU,ADCU_P
 SG_ CVC_usrData1 : 31|8@0+ (1,0) [0|255] ""  BMS,EVCC,FMCU,RMCU,POD_GW,PCU,ADCU_P
 SG_ CVC_usrData2 : 39|8@0+ (1,0) [0|255] ""  BMS,EVCC,FMCU,RMCU,POD_GW,PCU,ADCU_P
 SG_ CVC_usrData3 : 47|8@0+ (1,0) [0|255] ""  BMS,EVCC,FMCU,RMCU,POD_GW,PCU,ADCU_P
 SG_ CVC_usrData4 : 55|8@0+ (1,0) [0|255] ""  BMS,EVCC,FMCU,RMCU,POD_GW,PCU,ADCU_P
 SG_ CVC_usrData5 : 63|8@0+ (1,0) [0|255] ""  BMS,EVCC,FMCU,RMCU,POD_GW,PCU,ADCU_P

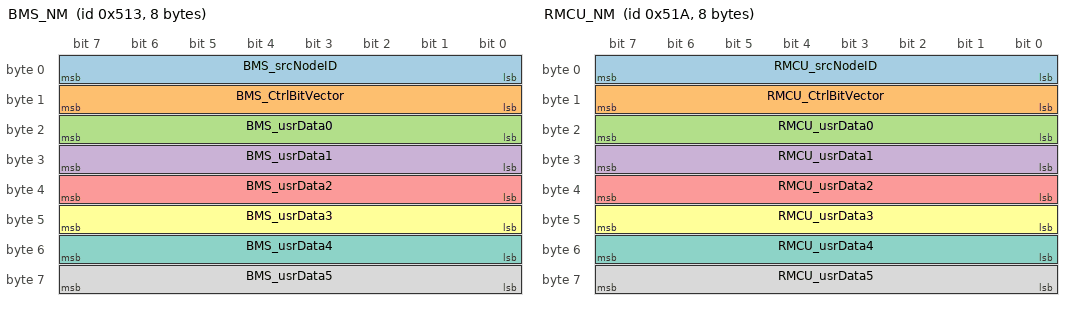
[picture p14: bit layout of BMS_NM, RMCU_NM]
BO_ 1299 BMS_NM: 8 BMS
 SG_ BMS_srcNodeID : 7|8@0+ (1,0) [0|255] ""  CVC_P,EVCC,FMCU,RMCU,POD_GW,PCU,ADCU_P
 SG_ BMS_CtrlBitVector : 15|8@0+ (1,0) [0|255] ""  CVC_P,EVCC,FMCU,RMCU,POD_GW,PCU,ADCU_P
 SG_ BMS_usrData0 : 23|8@0+ (1,0) [0|255] ""  CVC_P,EVCC,FMCU,RMCU,POD_GW,PCU,ADCU_P
 SG_ BMS_usrData1 : 31|8@0+ (1,0) [0|255] ""  CVC_P,EVCC,FMCU,RMCU,POD_GW,PCU,ADCU_P
 SG_ BMS_usrData2 : 39|8@0+ (1,0) [0|255] ""  CVC_P,EVCC,FMCU,RMCU,POD_GW,PCU,ADCU_P
 SG_ BMS_usrData3 : 47|8@0+ (1,0) [0|255] ""  CVC_P,EVCC,FMCU,RMCU,POD_GW,PCU,ADCU_P
 SG_ BMS_usrData4 : 55|8@0+ (1,0) [0|255] ""  CVC_P,EVCC,FMCU,RMCU,POD_GW,PCU,ADCU_P
 SG_ BMS_usrData5 : 63|8@0+ (1,0) [0|255] ""  CVC_P,EVCC,FMCU,RMCU,POD_GW,PCU,ADCU_P

BO_ 1306 RMCU_NM: 8 RMCU
 SG_ RMCU_srcNodeID : 7|8@0+ (1,0) [0|255] ""  BMS,CVC_P,EVCC,FMCU,POD_GW,PCU,ADCU_P
 SG_ RMCU_CtrlBitVector : 15|8@0+ (1,0) [0|255] ""  BMS,CVC_P,EVCC,FMCU,POD_GW,PCU,ADCU_P
 SG_ RMCU_usrData0 : 23|8@0+ (1,0) [0|255] ""  BMS,CVC_P,EVCC,FMCU,POD_GW,PCU,ADCU_P
 SG_ RMCU_usrData1 : 31|8@0+ (1,0) [0|255] ""  BMS,CVC_P,EVCC,FMCU,POD_GW,PCU,ADCU_P
 SG_ RMCU_usrData2 : 39|8@0+ (1,0) [0|255] ""  BMS,CVC_P,EVCC,FMCU,POD_GW,PCU,ADCU_P
 SG_ RMCU_usrData3 : 47|8@0+ (1,0) [0|255] ""  BMS,CVC_P,EVCC,FMCU,POD_GW,PCU,ADCU_P
 SG_ RMCU_usrData4 : 55|8@0+ (1,0) [0|255] ""  BMS,CVC_P,EVCC,FMCU,POD_GW,PCU,ADCU_P
 SG_ RMCU_usrData5 : 63|8@0+ (1,0) [0|255] ""  BMS,CVC_P,EVCC,FMCU,POD_GW,PCU,ADCU_P

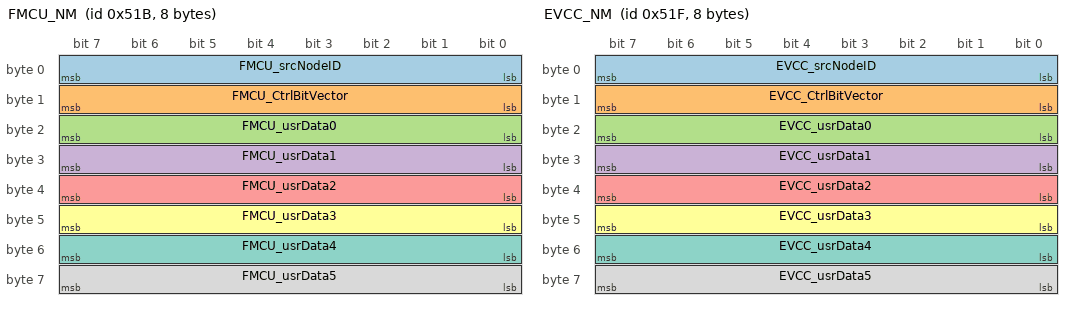
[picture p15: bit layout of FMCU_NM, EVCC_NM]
BO_ 1307 FMCU_NM: 8 FMCU
 SG_ FMCU_srcNodeID : 7|8@0+ (1,0) [0|255] ""  BMS,CVC_P,EVCC,RMCU,POD_GW,ADCU_P
 SG_ FMCU_CtrlBitVector : 15|8@0+ (1,0) [0|255] ""  BMS,CVC_P,EVCC,RMCU,POD_GW,ADCU_P
 SG_ FMCU_usrData0 : 23|8@0+ (1,0) [0|255] ""  BMS,CVC_P,EVCC,RMCU,POD_GW,ADCU_P
 SG_ FMCU_usrData1 : 31|8@0+ (1,0) [0|255] ""  BMS,CVC_P,EVCC,RMCU,POD_GW,ADCU_P
 SG_ FMCU_usrData2 : 39|8@0+ (1,0) [0|255] ""  BMS,CVC_P,EVCC,RMCU,POD_GW,ADCU_P
 SG_ FMCU_usrData3 : 47|8@0+ (1,0) [0|255] ""  BMS,CVC_P,EVCC,RMCU,POD_GW,ADCU_P
 SG_ FMCU_usrData4 : 55|8@0+ (1,0) [0|255] ""  BMS,CVC_P,EVCC,RMCU,POD_GW,ADCU_P
 SG_ FMCU_usrData5 : 63|8@0+ (1,0) [0|255] ""  BMS,CVC_P,EVCC,RMCU,POD_GW,ADCU_P

BO_ 1311 EVCC_NM: 8 EVCC
 SG_ EVCC_srcNodeID : 7|8@0+ (1,0) [0|255] ""  BMS,CVC_P,FMCU,RMCU,POD_GW,PCU,ADCU_P
 SG_ EVCC_CtrlBitVector : 15|8@0+ (1,0) [0|255] ""  BMS,CVC_P,FMCU,RMCU,POD_GW,PCU,ADCU_P
 SG_ EVCC_usrData0 : 23|8@0+ (1,0) [0|255] ""  BMS,CVC_P,FMCU,RMCU,POD_GW,PCU,ADCU_P
 SG_ EVCC_usrData1 : 31|8@0+ (1,0) [0|255] ""  BMS,CVC_P,FMCU,RMCU,POD_GW,PCU,ADCU_P
 SG_ EVCC_usrData2 : 39|8@0+ (1,0) [0|255] ""  BMS,CVC_P,FMCU,RMCU,POD_GW,PCU,ADCU_P
 SG_ EVCC_usrData3 : 47|8@0+ (1,0) [0|255] ""  BMS,CVC_P,FMCU,RMCU,POD_GW,PCU,ADCU_P
 SG_ EVCC_usrData4 : 55|8@0+ (1,0) [0|255] ""  BMS,CVC_P,FMCU,RMCU,POD_GW,PCU,ADCU_P
 SG_ EVCC_usrData5 : 63|8@0+ (1,0) [0|255] ""  BMS,CVC_P,FMCU,RMCU,POD_GW,PCU,ADCU_P

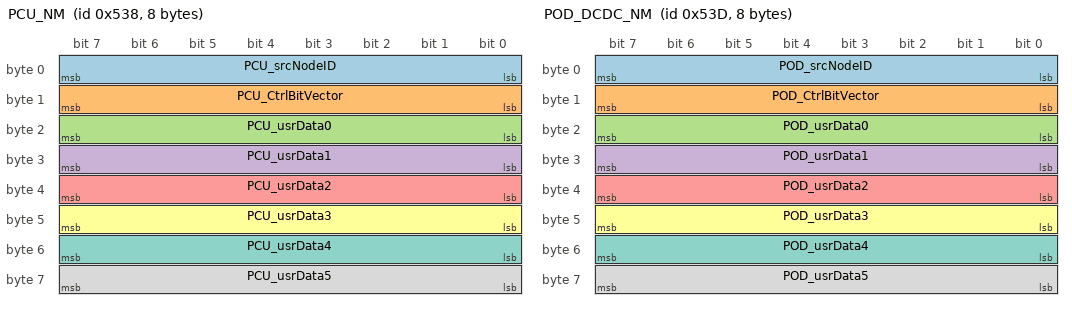
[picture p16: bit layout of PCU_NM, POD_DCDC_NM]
BO_ 1336 PCU_NM: 8 PCU
 SG_ PCU_srcNodeID : 7|8@0+ (1,0) [0|255] ""  BMS,CVC_P,EVCC,RMCU,POD_GW,ADCU_P
 SG_ PCU_CtrlBitVector : 15|8@0+ (1,0) [0|255] ""  BMS,CVC_P,EVCC,RMCU,POD_GW,ADCU_P
 SG_ PCU_usrData0 : 23|8@0+ (1,0) [0|255] ""  BMS,CVC_P,EVCC,RMCU,POD_GW,ADCU_P
 SG_ PCU_usrData1 : 31|8@0+ (1,0) [0|255] ""  BMS,CVC_P,EVCC,RMCU,POD_GW,ADCU_P
 SG_ PCU_usrData2 : 39|8@0+ (1,0) [0|255] ""  BMS,CVC_P,EVCC,RMCU,POD_GW,ADCU_P
 SG_ PCU_usrData3 : 47|8@0+ (1,0) [0|255] ""  BMS,CVC_P,EVCC,RMCU,POD_GW,ADCU_P
 SG_ PCU_usrData4 : 55|8@0+ (1,0) [0|255] ""  BMS,CVC_P,EVCC,RMCU,POD_GW,ADCU_P
 SG_ PCU_usrData5 : 63|8@0+ (1,0) [0|255] ""  BMS,CVC_P,EVCC,RMCU,POD_GW,ADCU_P

BO_ 1341 POD_DCDC_NM: 8 POD_GW
 SG_ POD_srcNodeID : 7|8@0+ (1,0) [0|255] ""  BMS,CVC_P,EVCC,FMCU,RMCU,PCU,ADCU_P
 SG_ POD_CtrlBitVector : 15|8@0+ (1,0) [0|255] ""  BMS,CVC_P,EVCC,FMCU,RMCU,PCU,ADCU_P
 SG_ POD_usrData0 : 23|8@0+ (1,0) [0|255] ""  BMS,CVC_P,EVCC,FMCU,RMCU,PCU,ADCU_P
 SG_ POD_usrData1 : 31|8@0+ (1,0) [0|255] ""  BMS,CVC_P,EVCC,FMCU,RMCU,PCU,ADCU_P
 SG_ POD_usrData2 : 39|8@0+ (1,0) [0|255] ""  BMS,CVC_P,EVCC,FMCU,RMCU,PCU,ADCU_P
 SG_ POD_usrData3 : 47|8@0+ (1,0) [0|255] ""  BMS,CVC_P,EVCC,FMCU,RMCU,PCU,ADCU_P
 SG_ POD_usrData4 : 55|8@0+ (1,0) [0|255] ""  BMS,CVC_P,EVCC,FMCU,RMCU,PCU,ADCU_P
 SG_ POD_usrData5 : 63|8@0+ (1,0) [0|255] ""  BMS,CVC_P,EVCC,FMCU,RMCU,PCU,ADCU_P

BO_ 1683 BMS_DiagReq: 64 CVC_P
 SG_ BMS_DiagReqData0 : 7|8@0+ (1,0) [0|255] ""  BMS
 SG_ BMS_DiagReqData1 : 15|8@0+ (1,0) [0|255] ""  BMS
 SG_ BMS_DiagReqData2 : 23|8@0+ (1,0) [0|255] ""  BMS
 SG_ BMS_DiagReqData3 : 31|8@0+ (1,0) [0|255] ""  BMS
 SG_ BMS_DiagReqData4 : 39|8@0+ (1,0) [0|255] ""  BMS
 SG_ BMS_DiagReqData5 : 47|8@0+ (1,0) [0|255] ""  BMS
 SG_ BMS_DiagReqData6 : 55|8@0+ (1,0) [0|255] ""  BMS
 SG_ BMS_DiagReqData7 : 63|8@0+ (1,0) [0|255] ""  BMS
 SG_ BMS_DiagReqData8 : 71|8@0+ (1,0) [0|255] ""  BMS
 SG_ BMS_DiagReqData9 : 79|8@0+ (1,0) [0|255] ""  BMS
 SG_ BMS_DiagReqData10 : 87|8@0+ (1,0) [0|255] ""  BMS
 SG_ BMS_DiagReqData11 : 95|8@0+ (1,0) [0|255] ""  BMS
 SG_ BMS_DiagReqData12 : 103|8@0+ (1,0) [0|255] ""  BMS
 SG_ BMS_DiagReqData13 : 111|8@0+ (1,0) [0|255] ""  BMS
 SG_ BMS_DiagReqData14 : 119|8@0+ (1,0) [0|255] ""  BMS
 SG_ BMS_DiagReqData15 : 127|8@0+ (1,0) [0|255] ""  BMS
 SG_ BMS_DiagReqData16 : 135|8@0+ (1,0) [0|255] ""  BMS
 SG_ BMS_DiagReqData17 : 143|8@0+ (1,0) [0|255] ""  BMS
 SG_ BMS_DiagReqData18 : 151|8@0+ (1,0) [0|255] ""  BMS
 SG_ BMS_DiagReqData19 : 159|8@0+ (1,0) [0|255] ""  BMS
 SG_ BMS_DiagReqData20 : 167|8@0+ (1,0) [0|255] ""  BMS
 SG_ BMS_DiagReqData21 : 175|8@0+ (1,0) [0|255] ""  BMS
 SG_ BMS_DiagReqData22 : 183|8@0+ (1,0) [0|255] ""  BMS
 SG_ BMS_DiagReqData23 : 191|8@0+ (1,0) [0|255] ""  BMS
 SG_ BMS_DiagReqData24 : 199|8@0+ (1,0) [0|255] ""  BMS
 SG_ BMS_DiagReqData25 : 207|8@0+ (1,0) [0|255] ""  BMS
 SG_ BMS_DiagReqData26 : 215|8@0+ (1,0) [0|255] ""  BMS
 SG_ BMS_DiagReqData27 : 223|8@0+ (1,0) [0|255] ""  BMS
 SG_ BMS_DiagReqData28 : 231|8@0+ (1,0) [0|255] ""  BMS
 SG_ BMS_DiagReqData29 : 239|8@0+ (1,0) [0|255] ""  BMS
 SG_ BMS_DiagReqData30 : 247|8@0+ (1,0) [0|255] ""  BMS
 SG_ BMS_DiagReqData31 : 255|8@0+ (1,0) [0|255] ""  BMS
 SG_ BMS_DiagReqData32 : 263|8@0+ (1,0) [0|255] ""  BMS
 SG_ BMS_DiagReqData33 : 271|8@0+ (1,0) [0|255] ""  BMS
 SG_ BMS_DiagReqData34 : 279|8@0+ (1,0) [0|255] ""  BMS
 SG_ BMS_DiagReqData35 : 287|8@0+ (1,0) [0|255] ""  BMS
 SG_ BMS_DiagReqData36 : 295|8@0+ (1,0) [0|255] ""  BMS
 SG_ BMS_DiagReqData37 : 303|8@0+ (1,0) [0|255] ""  BMS
 SG_ BMS_DiagReqData38 : 311|8@0+ (1,0) [0|255] ""  BMS
 SG_ BMS_DiagReqData39 : 319|8@0+ (1,0) [0|255] ""  BMS
 SG_ BMS_DiagReqData40 : 327|8@0+ (1,0) [0|255] ""  BMS
 SG_ BMS_DiagReqData41 : 335|8@0+ (1,0) [0|255] ""  BMS
 SG_ BMS_DiagReqData42 : 343|8@0+ (1,0) [0|255] ""  BMS
 SG_ BMS_DiagReqData43 : 351|8@0+ (1,0) [0|255] ""  BMS
 SG_ BMS_DiagReqData44 : 359|8@0+ (1,0) [0|255] ""  BMS
 SG_ BMS_DiagReqData45 : 367|8@0+ (1,0) [0|255] ""  BMS
 SG_ BMS_DiagReqData46 : 375|8@0+ (1,0) [0|255] ""  BMS
 SG_ BMS_DiagReqData47 : 383|8@0+ (1,0) [0|255] ""  BMS
 SG_ BMS_DiagReqData48 : 391|8@0+ (1,0) [0|255] ""  BMS
 SG_ BMS_DiagReqData49 : 399|8@0+ (1,0) [0|255] ""  BMS
 SG_ BMS_DiagReqData50 : 407|8@0+ (1,0) [0|255] ""  BMS
 SG_ BMS_DiagReqData51 : 415|8@0+ (1,0) [0|255] ""  BMS
 SG_ BMS_DiagReqData52 : 423|8@0+ (1,0) [0|255] ""  BMS
 SG_ BMS_DiagReqData53 : 431|8@0+ (1,0) [0|255] ""  BMS
 SG_ BMS_DiagReqData54 : 439|8@0+ (1,0) [0|255] ""  BMS
 SG_ BMS_DiagReqData55 : 447|8@0+ (1,0) [0|255] ""  BMS
 SG_ BMS_DiagReqData56 : 455|8@0+ (1,0) [0|255] ""  BMS
 SG_ BMS_DiagReqData57 : 463|8@0+ (1,0) [0|255] ""  BMS
 SG_ BMS_DiagReqData58 : 471|8@0+ (1,0) [0|255] ""  BMS
 SG_ BMS_DiagReqData59 : 479|8@0+ (1,0) [0|255] ""  BMS
 SG_ BMS_DiagReqData60 : 487|8@0+ (1,0) [0|255] ""  BMS
 SG_ BMS_DiagReqData61 : 495|8@0+ (1,0) [0|255] ""  BMS
 SG_ BMS_DiagReqData62 : 503|8@0+ (1,0) [0|255] ""  BMS
 SG_ BMS_DiagReqData63 : 511|8@0+ (1,0) [0|255] ""  BMS

CM_ SG_ 201 CRC_FMCU_Status "Checksum of this message";
CM_ SG_ 201 ALIVE_FMCU_Status "Signal counting the times of this message";
CM_ SG_ 201 FMCU_MotorTq "Front Motor torque";
CM_ SG_ 201 FMCU_MotorSpd "Front Motor rotating speed";
CM_ SG_ 201 FMCU_StsMCUFault "FMCU Fault Status";
CM_ SG_ 201 FMCU_MotorSpdSts "Front Motor rotating speed Invalid";
CM_ SG_ 201 FMCU_MotorTqSts "Front Motor torque Invalid";
CM_ SG_ 201 FMCU_CVC_CtrlMode "FMCU control mode";
CM_ SG_ 201 FMCU_CVC_StsMode "FMCU Operating Mode";
CM_ SG_ 202 FMCU_CVC_PosTrqLmt "Maximum positive Torque available (motor) for Front Motor Torque requests";
CM_ SG_ 202 FMCU_CVC_NegTrqLmt "Maximum negative torque available (generator) for Front Motor Torque requests";
CM_ SG_ 202 FMCU_ActInputCurrent "Front Motor Actual input DC current";
CM_ SG_ 202 FMCU_ActInputVolt "Front Motor Actual input DC voltage";
CM_ SG_ 202 FMCU_ActInputVoltV "Front Motor Actual input DC voltage validity";
CM_ SG_ 202 FMCU_ActInputCurrentV "Front Motor Actual input DC current validity";
CM_ BO_ 338 "FMCU FUSA Data";
CM_ SG_ 338 FMCU_FS_MCUTemp "FMCU FUSA MCU Temperature";
CM_ SG_ 338 FMCU_FS_MotTemp "FMCU FUSA Motor Temperature";
CM_ SG_ 338 FMCU_FS_CurSum "FUSA 3 Phase Current Sum";
CM_ SG_ 338 FMCU_UB_SBC "FMCU UBSBC";
CM_ SG_ 338 FMCU_FS_HighVoltage "Front Motor L2 DC voltage";
CM_ SG_ 338 FMCU_FS_TrqBlend "L2 Motor torque blend";
CM_ SG_ 368 FMCU_PhaseCurW "EDS phase current W";
CM_ SG_ 368 FMCU_PhaseCurV "EDS phase current V";
CM_ SG_ 368 FMCU_PhaseCurU "EDS phase current U";
CM_ SG_ 368 FMCU_MaxSpeedAllow "Front motor max speed allowed";
CM_ SG_ 368 FMCU_PhaseCurPeak "EDS phase current (max value)";
CM_ SG_ 368 FMCU_PowerReduceSts "FMCU reduce power status";
CM_ SG_ 368 FMCU_DragSts "Front motor Drag status";
CM_ SG_ 368 FMCU_HighVoltPowerOffReq "FMCU HV Power off request";
CM_ SG_ 368 FMCU_SinCosSqr "Front Sum of Sin Cos Square Value";
CM_ SG_ 568 FMCU_IGBT_WTemp "Front MCU NTC IGBT temperature phase W";
CM_ SG_ 568 FMCU_IGBT_VTemp "Front MCU NTC IGBT temperature phase V";
CM_ SG_ 568 FMCU_IGBT_UTemp "Front MCU NTC IGBT temperature phase U";
CM_ SG_ 568 FMCU_JunctionIGBT_WTemp "Front MCU Junction IGBT temperature phase W";
CM_ SG_ 568 FMCU_JunctionIGBT_VTemp "Front MCU Junction IGBT temperature phase V";
CM_ SG_ 568 FMCU_JunctionIGBT_UTemp "Front MCU Junction IGBT temperature phase U";
CM_ SG_ 568 FMCU_KL15 "FMCU KL15 Status";
CM_ SG_ 568 FMCU_KL30 "FMCU KL30 LV input";
CM_ SG_ 568 FMCU_SSUState "FMCU SSU State";
CM_ SG_ 568 FMCU_DampingState "FMCU Damping state";
CM_ SG_ 568 FMCU_IGBTState "FMCU IGBT State";
CM_ SG_ 568 FMCU_ASRSts "Antiskid system status";
CM_ SG_ 872 FMCU_PhaseOverCurrentSWFault "Front Phase Current Overcurrent software fault";
CM_ SG_ 872 FMCU_MCUOverTempFault "FMCU over temperture fault";
CM_ SG_ 872 FMCU_MCUOverTempAlarm "FMCU over temperture alarm";
CM_ SG_ 872 FMCU_MotOverTemp2Fault "Front Motor temperature sensorU fault";
CM_ SG_ 872 FMCU_MotTempSenFault "Front Motor temperature sensor fault";
CM_ SG_ 872 FMCU_MotOverTemp1Fault "Front Motor over temperture fault";
CM_ SG_ 872 FMCU_MotOverTempAlarm "Front Motor over temperture alarm";
CM_ SG_ 872 FMCU_MCUHVUnderVoltageFault "FMCU high voltage under voltage fault";
CM_ SG_ 872 FMCU_MCUHVUnderVoltageAlarm "FMCU high voltage under voltage alarm";
CM_ SG_ 872 FMCU_MCUHVOverVoltageFault "FMCU high voltage over voltage fault";
CM_ SG_ 872 FMCU_MCUHVOverVoltageAlarm "FMCU high voltage over voltage alarm";
CM_ SG_ 872 FMCU_MCUCurrentSenWFault "FMCU current sensorW fault";
CM_ SG_ 872 FMCU_MCUCurrentSenVFault "FMCU current sensorV fault";
CM_ SG_ 872 FMCU_MCUCurrentSenUFault "FMCU current sensorU fault";
CM_ SG_ 872 FMCU_PhaseOverCurrentHWFault "Phase Current Overcurrent hardware fault";
CM_ SG_ 872 FMCU_MotOverFault "Motor overspeed fault fault";
CM_ SG_ 872 FMCU_MotOverAlarm "Motor overspeed fault alarm";
CM_ SG_ 872 FMCU_12VUnderVoltageAlarm "12V Power under voltage alarm";
CM_ SG_ 872 FMCU_12VOverVoltageAlarm "12V Power over voltage alarm";
CM_ SG_ 872 FMCU_MCUHVSensorFault "FMCU high voltage sensor fault";
CM_ SG_ 872 FMCU_MCUDisChgFault "FMCU Active discharge fault";
CM_ SG_ 872 FMCU_MotBlockedFault "Motor blocked fault";
CM_ SG_ 872 FMCU_MotRotSenFault "Motor resolver fault";
CM_ SG_ 872 FMCU_BMSLostFault "BMS lost communication fault";
CM_ SG_ 872 FMCU_CVCLostFault "CVC lost communication fault";
CM_ SG_ 872 FMCU_CANBusoffFault "CAN busoff fault";
CM_ SG_ 872 FMCU_IGBTFault "IGBT fault";
CM_ SG_ 872 FMCU_MCUCurrentSenWZeroFault "FMCU current sensorW Zero fault";
CM_ SG_ 872 FMCU_MCUCurrentSenVZeroFault "FMCU current sensorV Zero fault";
CM_ SG_ 872 FMCU_MCUCurrentSenUZeroFault "FMCU current sensorU Zero fault";
CM_ SG_ 872 FMCU_MCUTempSenWFault "FMCU temperature sensorW fault";
CM_ SG_ 872 FMCU_MCUTempSenVFault "FMCU temperature sensorV fault";
CM_ SG_ 872 FMCU_MCUTempSenUFault "FMCU temperature sensorU fault";
CM_ SG_ 872 FMCU_InitMode "Initial mode";
CM_ SG_ 872 FMCU_MCUFaultCode "FMCU Fault Code";
CM_ SG_ 873 FMCU_CoolantTemp "Front inlet temp";
CM_ SG_ 873 FMCU_MCUTemp "FMCU IGBT temperature";
CM_ SG_ 873 FMCU_MotorTemp "Front Motor temperature";
CM_ SG_ 873 FMCU_MCUBoardTemp "FMCU internal temperature";
CM_ SG_ 873 FMCU_WaterPumpLevlReq "FMCU waterpump request";
CM_ SG_ 873 FMCU_StsActiveDischg "FMCU Active discharge state";
CM_ SG_ 873 FMCU_TBOX_ModeMotorDrv "Front Motor driving mode";
CM_ SG_ 873 FMCU_MotorTemp1 "Front Motor U temperature";
CM_ SG_ 873 FMCU_MotorTemp2 "Front Motor V temperature";
CM_ SG_ 1080 FMCU_HV_Error_Info "FMCU High Voltage Error Information";
CM_ SG_ 1080 FMCU_HV_Fault_Sts "FMCU High Voltage Fault Status";
CM_ SG_ 1080 FMCU_Idc_Error_Info "FMCU Bus Current Error Information";
CM_ SG_ 1080 FMCU_Idc_Fault_Sts "FMCU Bus Current Fault Status";
CM_ SG_ 1080 FMCU_Mode_Error_Info "FMCU Mode Error Information";
CM_ SG_ 1080 FMCU_Mode_Fault_Sts "FMCU Mode Fault Status";
CM_ SG_ 1080 FMCU_MotDiag_Error_Info "FMCU Motor Diagnostic Error Information";
CM_ SG_ 1080 FMCU_MotDiag_Fault_Sts "FMCU Motor Diagnostic Fault Status";
CM_ SG_ 1080 FMCU_LVSup_Error_Info "FMCU LV Supply Error Information";
CM_ SG_ 1080 FMCU_LVSup_Fault_Sts "FMCU LV Supply Fault Status";
CM_ SG_ 1080 FMCU_DrvModu_Error_Info "FMCU Power Driver Module Error Information";
CM_ SG_ 1080 FMCU_DrvModu_Fault_Sts "FMCU Power Driver Module Fault Status";
CM_ SG_ 1083 FMCU_Mem_Fault_Sts "FMCU Memory Fault Status";
CM_ SG_ 1083 FMCU_Mem_Error_Info "FMCU Memory Error Information";
CM_ SG_ 1083 FMCU_CS_Fault_Sts "FMCU Cyber Security Fault Status";
CM_ SG_ 1083 FMCU_CS_Error_Info "FMCU Cyber Secrity Error Information";
CM_ SG_ 1083 FMCU_CANCom_Fault_Sts "FMCU CAN Communication Fault Status";
CM_ SG_ 1083 FMCU_CANCom_Error_Info "FMCU CAN Communication Error Information";
CM_ SG_ 1083 FMCU_SSU_Fault_Sts "FMCU SSU Fault Status";
CM_ SG_ 1083 FMCU_SSU_Error_Info "FMCU SSU Error Information";
CM_ SG_ 1083 FMCU_Spd_Fault_Sts "FMCU Speed Fault Status";
CM_ SG_ 1083 FMCU_Spd_Error_Info "FMCU Speed Error Information";
CM_ SG_ 1083 FMCU_PwrModu_Fault_Sts "FMCU Power Supply Module Fault Status";
CM_ SG_ 1083 FMCU_PwrModu_Error_Info "FMCU Power Supply Module Error Information";
CM_ SG_ 1083 FMCU_PhaCur_Fault_Sts "FMCU Phase Current Fault Status";
CM_ SG_ 1083 FMCU_PhaCur_Error_Info "FMCU Phase Current Error Information";
CM_ SG_ 1085 FMCU_TrqCtl_Fault_Sts "FMCU Torque Control Fault Status";
CM_ SG_ 1085 FMCU_TrqCtl_Error_Info "FMCU Torque Control Error Information";
CM_ SG_ 1085 FMCU_Thermal_Fault_Sts "FMCU Thermal Fault Status";
CM_ SG_ 1085 FMCU_Thermal_Error_Info "FMCU Thermal Error Information";
CM_ SG_ 1085 FMCU_PosSen_Fault_Sts "FMCU Position Sensor Fault Status";
CM_ SG_ 1085 FMCU_PosSen_Error_Info "FMCU Position Sensor Error Information";
CM_ SG_ 1085 FMCU_IOHW_Fault_Sts "FMCU IOHWAB Fault Status";
CM_ SG_ 1085 FMCU_IOHW_Error_Info "FMCU IOHWAB Error Information";
CM_ SG_ 1087 FMCU_FS_PhaCurMon_Error_Info "FUSA Phase Current Monitor Error Information";
CM_ SG_ 1087 FMCU_FS_SOPMon_Error_Info "FUSA SOP Monitor Error Information";
CM_ SG_ 1087 FMCU_FS_MCUMon_Error_Info "FUSA MCU Monitor Error Information";
CM_ SG_ 1087 FMCU_FS_SBCMon_Error_Info "FUSA SBC Monitor Error Information";
CM_ SG_ 1087 FMCU_FS_TempMon_Error_Info "FUSA Temperature Monitor Error Information";
CM_ SG_ 1087 FMCU_FS_SpdMon_Error_Info "FUSA Speed Monitor Error Information";
CM_ SG_ 1087 FMCU_FS_TrqMon_Error_Info "FUSA Torque Monitor Error Information";
CM_ SG_ 1087 FMCU_FS_HVMon_Error_Info "FUSA High Voltage Monitor Error Information";
CM_ SG_ 1087 FMCU_FS_LVMon_Error_Info "FUSA Low Voltage Monitor Error Information";
CM_ SG_ 1087 FMCU_FS_SOPMonFault "FUSA Shut Off Path Monitor Fault";
CM_ SG_ 1087 FMCU_FS_MCUMonFault "FUSA MCU Monitor Fault";
CM_ SG_ 1087 FMCU_FS_SBCMonFault "FUSA SBC Monitor Fault";
CM_ SG_ 1087 FMCU_FS_TempMonFault "FUSA Temperature Monitor Fault";
CM_ SG_ 1087 FMCU_FS_SpdMonFault "FUSA Speed Monitor Fault";
CM_ SG_ 1087 FMCU_FS_PhaCurMonFault "FUSA Phase Current Monitor Fault";
CM_ SG_ 1087 FMCU_FS_TrqMonFault "FUSA Torque Monitor Fault";
CM_ SG_ 1087 FMCU_FS_LVMonFault "FUSA Low Voltage Monitor Fault";
CM_ SG_ 1087 FMCU_FS_HVFault "FUSA High Voltage Monitor Fault";
CM_ SG_ 1179 CRC_FMCU_WarnMsg "Checksum";
CM_ SG_ 1179 ALIVE_FMCU_WarnMsg "Alive Counter";
CM_ SG_ 1179 FMCU_Warning_Flag_1 "Warning Message Flag, Component owner, Supplier align and define for this signal";
CM_ SG_ 1179 FMCU_Warning_Flag_2 "Warning Message Flag, Component owner, Supplier align and define for this signal";
CM_ SG_ 1179 FMCU_Warning_Flag_3 "Warning Message Flag, Component owner, Supplier align and define for this signal";
CM_ SG_ 1179 FMCU_Warning_Flag_4 "Warning Message Flag, Component owner, Supplier align and define for this signal";
CM_ SG_ 1179 FMCU_Warning_Flag_5 "Warning Message Flag, Component owner, Supplier align and define for this signal";
CM_ SG_ 1179 FMCU_Warning_Flag_6 "Warning Message Flag, Component owner, Supplier align and define for this signal";
CM_ SG_ 1179 FMCU_Warning_Flag_7 "Warning Message Flag, Component owner, Supplier align and define for this signal";
CM_ SG_ 1179 FMCU_Warning_Flag_8 "Warning Message Flag, Component owner, Supplier align and define for this signal";
CM_ SG_ 1179 FMCU_Warning_Flag_9 "Warning Message Flag, Component owner, Supplier align and define for this signal";
CM_ SG_ 1179 FMCU_Warning_Flag_10 "Warning Message Flag, Component owner, Supplier align and define for this signal";
CM_ SG_ 1179 FMCU_Warning_Flag_11 "Warning Message Flag, Component owner, Supplier align and define for this signal";
CM_ SG_ 1179 FMCU_Warning_Flag_12 "Warning Message Flag, Component owner, Supplier align and define for this signal";
CM_ SG_ 1179 FMCU_Reserved_signal1 "Warning Message Flag, Component owner, Supplier align and define for this signal";
CM_ SG_ 1179 FMCU_Reserved_signal2 "Warning Message Flag, Component owner, Supplier align and define for this signal";
CM_ SG_ 1179 FMCU_Reserved_signal3 "Warning Message Flag, Component owner, Supplier align and define for this signal";
CM_ SG_ 1179 FMCU_Reserved_signal4 "Warning Message Flag, Component owner, Supplier align and define for this signal";
CM_ SG_ 1179 FMCU_Reserved_signal5 "Warning Message Flag, Component owner, Supplier align and define for this signal";
CM_ SG_ 91 RMCU_Trap_Tin "RMCU Trap Tin";
CM_ SG_ 91 RMCU_Trap_Class "RMCU Trap Class";
CM_ SG_ 91 RMCU_ReturnAddress "RMCU Return Address";
CM_ SG_ 91 RMCU_DEADD_Value "RMCU DEADD Value";
CM_ SG_ 203 CRC_RMCU_Status "Checksum of this message";
CM_ SG_ 203 ALIVE_RMCU_Status "Signal counting the times of this message";
CM_ SG_ 203 RMCU_MotorTq "Rear Motor torque";
CM_ SG_ 203 RMCU_MotorSpd "Rear Motor rotating speed";
CM_ SG_ 203 RMCU_StsMCUFault "RMCU Fault Status";
CM_ SG_ 203 RMCU_MotorSpdValid "Rear Motor rotating speed Invalid";
CM_ SG_ 203 RMCU_MotorTqValid "Rear Motor torque Invalid";
CM_ SG_ 203 RMCU_CVC_CtrlMode "RMCU control mode";
CM_ SG_ 203 RMCU_CVC_StsMode "RMCU Operating Mode";
CM_ SG_ 204 RMCU_CVC_PosTrqLmt "Maximum positive Torque available (motor) for rear Motor Torque requests";
CM_ SG_ 204 RMCU_CVC_NegTrqLmt "Maximum negative torque available (generator) for rear Motor Torque requests";
CM_ SG_ 204 RMCU_ActInputCurrent "rear Motor Actual input DC current";
CM_ SG_ 204 RMCU_ActInputVolt "rear Motor Actual input DC voltage";
CM_ SG_ 204 RMCU_ActInputVoltV "rear Motor Actual input DC voltage validity";
CM_ SG_ 204 RMCU_ActInputCurrentV "rear Motor Actual input DC current validity";
CM_ SG_ 339 RMCU_FS_MCUTemp "RMCU FUSA MCU Temperature";
CM_ SG_ 339 RMCU_FS_MotTemp "RMCU FUSA Motor Temperature";
CM_ SG_ 339 RMCU_FS_CurSum "FUSA 3 Phase Current Sum";
CM_ SG_ 339 RMCU_UB_SBC "RMCU UBSBC";
CM_ SG_ 339 RMCU_FS_HighVoltage "Front Motor L2 DC voltage";
CM_ SG_ 339 RMCU_FS_TrqBlend "L2 Motor torque blend";
CM_ SG_ 369 RMCU_PhaseCurW "EDS phase current W";
CM_ SG_ 369 RMCU_PhaseCurV "EDS phase current V";
CM_ SG_ 369 RMCU_PhaseCurU "EDS phase current U";
CM_ SG_ 369 RMCU_MaxSpeedAllow "Rear motor max speed allowed";
CM_ SG_ 369 RMCU_PhaseCurPeak "EDS phase current (max value)";
CM_ SG_ 369 RMCU_PowerReduceSts "RMCU reduce power status";
CM_ SG_ 369 RMCU_DragSts "Rear motor Drag status";
CM_ SG_ 369 RMCU_HighVoltPowerOffReq "RMCU HV Power off request";
CM_ SG_ 369 RMCU_SinCosSqr "Rear Sum of Sin Cos Square Value";
CM_ SG_ 569 RMCU_IGBT_WTemp "Rear MCU NTC IGBT temperature phase W";
CM_ SG_ 569 RMCU_IGBT_VTemp "Rear MCU NTC IGBT temperature phase V";
CM_ SG_ 569 RMCU_IGBT_UTemp "Rear MCU NTC IGBT temperature phase U";
CM_ SG_ 569 RMCU_JunctionIGBT_WTemp "Rear MCU Junction IGBT temperature phase W";
CM_ SG_ 569 RMCU_JunctionIGBT_VTemp "Rear MCU Junction IGBT temperature phase V";
CM_ SG_ 569 RMCU_JunctionIGBT_UTemp "Rear MCU Junction IGBT temperature phase U";
CM_ SG_ 569 RMCU_KL15 "RMCU KL15 Status";
CM_ SG_ 569 RMCU_KL30 "RMCU KL30 LV input";
CM_ SG_ 569 RMCU_SSUState "RMCU SSU State";
CM_ SG_ 569 RMCU_DampingState "RMCU Damping state";
CM_ SG_ 569 RMCU_IGBTState "RMCU IGBT State";
CM_ SG_ 569 RMCU_ASRSts "Antiskid system status";
CM_ SG_ 874 RMCU_PhaseOverCurrentSWFault "Rear Phase Current Overcurrent software fault";
CM_ SG_ 874 RMCU_MCUOverTempFault "RMCU over temperture fault";
CM_ SG_ 874 RMCU_MCUOverTempAlarm "RMCU over temperture alarm";
CM_ SG_ 874 RMCU_MotOverTemp2Fault "Rear Motor temperature sensorU fault";
CM_ SG_ 874 RMCU_MotTempSenFault "Rear Motor temperature sensor fault";
CM_ SG_ 874 RMCU_MotOverTemp1Fault "Rear Motor over temperture fault";
CM_ SG_ 874 RMCU_MotOverTempAlarm "Rear Motor over temperture alarm";
CM_ SG_ 874 RMCU_MCUHVUnderVoltageFault "RMCU high voltage under voltage fault";
CM_ SG_ 874 RMCU_MCUHVUnderVoltageAlarm "RMCU high voltage under voltage alarm";
CM_ SG_ 874 RMCU_MCUHVOverVoltageFault "RMCU high voltage over voltage fault";
CM_ SG_ 874 RMCU_MCUHVOverVoltageAlarm "RMCU high voltage over voltage alarm";
CM_ SG_ 874 RMCU_MCUCurrentSenWFault "RMCU current sensorW fault";
CM_ SG_ 874 RMCU_MCUCurrentSenVFault "RMCU current sensorV fault";
CM_ SG_ 874 RMCU_MCUCurrentSenUFault "RMCU current sensorU fault";
CM_ SG_ 874 RMCU_PhaseOverCurrentHWFault "Phase Current Overcurrent hardware fault";
CM_ SG_ 874 RMCU_MotOverFault "Motor overspeed fault fault";
CM_ SG_ 874 RMCU_MotOverAlarm "Motor overspeed fault alarm";
CM_ SG_ 874 RMCU_12VUnderVoltageAlarm "12V Power under voltage alarm";
CM_ SG_ 874 RMCU_12VOverVoltageAlarm "12V Power over voltage alarm";
CM_ SG_ 874 RMCU_MCUHVSensorFault "RMCU high voltage sensor fault";
CM_ SG_ 874 RMCU_MCUDisChgFault "RMCU Active discharge fault";
CM_ SG_ 874 RMCU_MotBlockedFault "Motor blocked fault";
CM_ SG_ 874 RMCU_MotRotSenFault "Motor resolver fault";
CM_ SG_ 874 RMCU_BMSLostFault "BMS lost communication fault";
CM_ SG_ 874 RMCU_CVCLostFault "CVC lost communication fault";
CM_ SG_ 874 RMCU_CANBusoffFault "CAN busoff fault";
CM_ SG_ 874 RMCU_IGBTFault "IGBT fault";
CM_ SG_ 874 RMCU_MCUCurrentSenWZeroFault "RMCU current sensorW Zero fault";
CM_ SG_ 874 RMCU_MCUCurrentSenVZeroFault "RMCU current sensorV Zero fault";
CM_ SG_ 874 RMCU_MCUCurrentSenUZeroFault "RMCU current sensorU Zero fault";
CM_ SG_ 874 RMCU_MCUTempSenWFault "RMCU temperature sensorW fault";
CM_ SG_ 874 RMCU_MCUTempSenVFault "RMCU temperature sensorV fault";
CM_ SG_ 874 RMCU_MCUTempSenUFault "RMCU temperature sensorU fault";
CM_ SG_ 874 RMCU_InitMode "Initial mode";
CM_ SG_ 874 RMCU_MCUFaultCode "RMCU Fault Code";
CM_ SG_ 875 RMCU_CoolantTemp "Rear inlet temp";
CM_ SG_ 875 RMCU_MCUTemp "RMCU IGBT temperature";
CM_ SG_ 875 RMCU_MotorTemp "Rear Motor temperature";
CM_ SG_ 875 RMCU_MCUBoardTemp "RMCU internal temperature";
CM_ SG_ 875 RMCU_WaterPumpLevlReq "RMCU waterpump request";
CM_ SG_ 875 RMCU_StsActiveDischg "RMCU Active discharge state";
CM_ SG_ 875 RMCU_TBOX_ModeMotorDrv "Rear Motor driving mode";
CM_ SG_ 875 RMCU_MotorTemp1 "Rear Motor U temperature";
CM_ SG_ 875 RMCU_MotorTemp2 "Rear Motor V temperature";
CM_ SG_ 1081 RMCU_HV_Error_Info "RMCU High Voltage Error Information";
CM_ SG_ 1081 RMCU_HV_Fault_Sts "RMCU High Voltage Fault Status";
CM_ SG_ 1081 RMCU_Idc_Error_Info "RMCU Bus Current Error Information";
CM_ SG_ 1081 RMCU_Idc_Fault_Sts "RMCU Bus Current Fault Status";
CM_ SG_ 1081 RMCU_Mode_Error_Info "RMCU Mode Error Information";
CM_ SG_ 1081 RMCU_Mode_Fault_Sts "RMCU Mode Fault Status";
CM_ SG_ 1081 RMCU_MotDiag_Error_Info "RMCU Motor Diagnostic Error Information";
CM_ SG_ 1081 RMCU_MotDiag_Fault_Sts "RMCU Motor Diagnostic Fault Status";
CM_ SG_ 1081 RMCU_LVSup_Error_Info "RMCU LV Supply Error Information";
CM_ SG_ 1081 RMCU_LVSup_Fault_Sts "RMCU LV Supply Fault Status";
CM_ SG_ 1081 RMCU_DrvModu_Error_Info "RMCU Power Driver Module Error Information";
CM_ SG_ 1081 RMCU_DrvModu_Fault_Sts "RMCU Power Driver Module Fault Status";
CM_ SG_ 1082 RMCU_Mem_Fault_Sts "RMCU Memory Fault Status";
CM_ SG_ 1082 RMCU_Mem_Error_Info "RMCU Memory Error Information";
CM_ SG_ 1082 RMCU_CS_Fault_Sts "RMCU Cyber Security Fault Status";
CM_ SG_ 1082 RMCU_CS_Error_Info "RMCU Cyber Secrity Error Information";
CM_ SG_ 1082 RMCU_CANCom_Fault_Sts "RMCU CAN Communication Fault Status";
CM_ SG_ 1082 RMCU_CANCom_Error_Info "RMCU CAN Communication Error Information";
CM_ SG_ 1082 RMCU_SSU_Fault_Sts "RMCU SSU Fault Status";
CM_ SG_ 1082 RMCU_SSU_Error_Info "RMCU SSU Error Information";
CM_ SG_ 1082 RMCU_Spd_Fault_Sts "RMCU Speed Fault Status";
CM_ SG_ 1082 RMCU_Spd_Error_Info "RMCU Speed Error Information";
CM_ SG_ 1082 RMCU_PwrModu_Fault_Sts "RMCU Power Supply Module Fault Status";
CM_ SG_ 1082 RMCU_PwrModu_Error_Info "RMCU Power Supply Module Error Information";
CM_ SG_ 1082 RMCU_PhaCur_Fault_Sts "RMCU Phase Current Fault Status";
CM_ SG_ 1082 RMCU_PhaCur_Error_Info "RMCU Phase Current Error Information";
CM_ SG_ 1084 RMCU_TrqCtl_Fault_Sts "RMCU Torque Control Fault Status";
CM_ SG_ 1084 RMCU_TrqCtl_Error_Info "RMCU Torque Control Error Information";
CM_ SG_ 1084 RMCU_Thermal_Fault_Sts "RMCU Thermal Fault Status";
CM_ SG_ 1084 RMCU_Thermal_Error_Info "RMCU Thermal Error Information";
CM_ SG_ 1084 RMCU_PosSen_Fault_Sts "RMCU Position Sensor Fault Status";
CM_ SG_ 1084 RMCU_PosSen_Error_Info "RMCU Position Sensor Error Information";
CM_ SG_ 1084 RMCU_IOHW_Fault_Sts "RMCU IOHWAB Fault Status";
CM_ SG_ 1084 RMCU_IOHW_Error_Info "RMCU IOHWAB Error Information";
CM_ SG_ 1091 RMCU_FS_PhaCurMon_Error_Info "FUSA Phase Current Monitor Error Information";
CM_ SG_ 1091 RMCU_FS_SOPMon_Error_Info "FUSA SOP Monitor Error Information";
CM_ SG_ 1091 RMCU_FS_MCUMon_Error_Info "FUSA MCU Monitor Error Information";
CM_ SG_ 1091 RMCU_FS_SBCMon_Error_Info "FUSA SBC Monitor Error Information";
CM_ SG_ 1091 RMCU_FS_TempMon_Error_Info "FUSA Temperature Monitor Error Information";
CM_ SG_ 1091 RMCU_FS_SpdMon_Error_Info "FUSA Speed Monitor Error Information";
CM_ SG_ 1091 RMCU_FS_TrqMon_Error_Info "FUSA Torque Monitor Error Information";
CM_ SG_ 1091 RMCU_FS_HVMon_Error_Info "FUSA High Voltage Monitor Error Information";
CM_ SG_ 1091 RMCU_FS_LVMon_Error_Info "FUSA Low Voltage Monitor Error Information";
CM_ SG_ 1091 RMCU_FS_SOPMonFault "FUSA Shut Off Path Monitor Fault";
CM_ SG_ 1091 RMCU_FS_MCUMonFault "FUSA MCU Monitor Fault";
CM_ SG_ 1091 RMCU_FS_SBCMonFault "FUSA SBC Monitor Fault";
CM_ SG_ 1091 RMCU_FS_TempMonFault "FUSA Temperature Monitor Fault";
CM_ SG_ 1091 RMCU_FS_SpdMonFault "FUSA Speed Monitor Fault";
CM_ SG_ 1091 RMCU_FS_PhaCurMonFault "FUSA Phase Current Monitor Fault";
CM_ SG_ 1091 RMCU_FS_TrqMonFault "FUSA Torque Monitor Fault";
CM_ SG_ 1091 RMCU_FS_LVMonFault "FUSA Low Voltage Monitor Fault";
CM_ SG_ 1091 RMCU_FS_HVFault "FUSA High Voltage Monitor Fault";
CM_ SG_ 1178 CRC_RMCU_WarnMsg "Checksum";
CM_ SG_ 1178 ALIVE_RMCU_WarnMsg "Alive Counter";
CM_ SG_ 1178 RMCU_Warning_Flag_1 "Warning Message Flag, Component owner, Supplier align and define for this signal";
CM_ SG_ 1178 RMCU_Warning_Flag_2 "Warning Message Flag, Component owner, Supplier align and define for this signal";
CM_ SG_ 1178 RMCU_Warning_Flag_3 "Warning Message Flag, Component owner, Supplier align and define for this signal";
CM_ SG_ 1178 RMCU_Warning_Flag_4 "Warning Message Flag, Component owner, Supplier align and define for this signal";
CM_ SG_ 1178 RMCU_Warning_Flag_5 "Warning Message Flag, Component owner, Supplier align and define for this signal";
CM_ SG_ 1178 RMCU_Warning_Flag_6 "Warning Message Flag, Component owner, Supplier align and define for this signal";
CM_ SG_ 1178 RMCU_Warning_Flag_7 "Warning Message Flag, Component owner, Supplier align and define for this signal";
CM_ SG_ 1178 RMCU_Warning_Flag_8 "Warning Message Flag, Component owner, Supplier align and define for this signal";
CM_ SG_ 1178 RMCU_Warning_Flag_9 "Warning Message Flag, Component owner, Supplier align and define for this signal";
CM_ SG_ 1178 RMCU_Warning_Flag_10 "Warning Message Flag, Component owner, Supplier align and define for this signal";
CM_ SG_ 1178 RMCU_Warning_Flag_11 "Warning Message Flag, Component owner, Supplier align and define for this signal";
CM_ SG_ 1178 RMCU_Warning_Flag_12 "Warning Message Flag, Component owner, Supplier align and define for this signal";
CM_ SG_ 1178 RMCU_Reserved_signal1 "Warning Message Flag, Component owner, Supplier align and define for this signal";
CM_ SG_ 1178 RMCU_Reserved_signal2 "Warning Message Flag, Component owner, Supplier align and define for this signal";
CM_ SG_ 1178 RMCU_Reserved_signal3 "Warning Message Flag, Component owner, Supplier align and define for this signal";
CM_ SG_ 1178 RMCU_Reserved_signal4 "Warning Message Flag, Component owner, Supplier align and define for this signal";
CM_ SG_ 1178 RMCU_Reserved_signal5 "Warning Message Flag, Component owner, Supplier align and define for this signal";
CM_ SG_ 661 POD_DCFC_State_Contactor "POD DCFC State Contactor";
CM_ SG_ 661 POD_DCFC_Sts_reversed0 "POD DCFC  state reversed0";
CM_ SG_ 661 POD_DCFC_Sts_reversed1 "POD DCFC  state reversed1";
CM_ SG_ 661 POD_DCFC_Sts_reversed2 "POD DCFC  state reversed2";
CM_ SG_ 661 POD_DCFC_Sts_reversed3 "POD DCFC  state reversed3";
CM_ SG_ 661 POD_DCFC_ChgPortVolt "POD DCFC CP Voltage";
CM_ SG_ 661 POD_DCFC_Sts_reversed4 "POD DCFC  state reversed4";
CM_ SG_ 661 POD_tempHVBusNeg "Indicate the temperature of the negative bus bar";
CM_ SG_ 661 POD_tempHVBusPlus "Indicate the temperature of the positive bus bar";
CM_ SG_ 662 POD_DCDC_InputHV "Input Voltage";
CM_ SG_ 662 PDU_DCDC_StsCtrl "DCDC Control Status to CVC";
CM_ SG_ 662 PDU_DCDC_OutputCurrent "Output Current";
CM_ SG_ 662 PDU_DCDC_OutputVolt "Output Voltage";
CM_ SG_ 663 POD_DCDC_evt_BUS_OFF "POD DC converter bus shutdown event";
CM_ SG_ 663 POD_DCDC_evt_MIA "POD DC Converter Message Loss Event";
CM_ SG_ 663 POD_DCDC_evt_E2E "End to end verification events for POD DC converters";
CM_ SG_ 663 POD_DCDC_evt_CalibFlt "POD DC converter calibration fault event";
CM_ SG_ 663 POD_DCDC_evt_ExtMemFlt "POD DC Converter External Memory Failure Event";
CM_ SG_ 663 POD_DCDC_evt_FaultLatchCircuit "POD DC converter fault latch circuit event";
CM_ SG_ 663 POD_DCDC_evt_HVBat_VSensFail "POD DC Converter High Voltage Battery Voltage Sensor Fault Event";
CM_ SG_ 663 POD_DCDC_evt_HVBat_OverVolt_SW "POD DC converter high-voltage battery overvoltage event (software triggered)";
CM_ SG_ 663 POD_DCDC_evt_HVBat_UnderVolt_SW "POD DC converter high-voltage battery undervoltage event (software triggered)";
CM_ SG_ 663 POD_DCDC_evt_LVOut_VSensFail "POD DC Converter Low Voltage Output Voltage Sensor Fault Event";
CM_ SG_ 663 POD_DCDC_evt_LVBat_OverVolt_SW "POD DC Converter Low Voltage Battery Overvoltage Event (Software Triggered)";
CM_ SG_ 663 POD_DCDC_evt_LVBat_UnderVolt_SW "POD DC Converter Low Voltage Battery Undervoltage Event (Software Triggered)";
CM_ SG_ 663 POD_DCDC_evt_LVBat_VSensFail "POD DC Converter Low Voltage Battery Voltage Sensor Fault Event";
CM_ SG_ 663 POD_DCDC_evt_LV_RedundancyFlt "POD DC Converter Low Voltage Redundant Circuit Fault Event";
CM_ SG_ 663 POD_DCDC_evt_LVOut_ISensFail "POD DC Converter Low Voltage Output Current Sensor Fault Event";
CM_ SG_ 663 POD_DCDC_evt_LVOut_OverCurr_SW "Low voltage output overcurrent event of POD DC converter (software triggered)";
CM_ SG_ 663 POD_DCDC_evt_LVOut_RevrsCurr_SW "POD DC Converter Low Voltage Output Reverse Current Event (Software Triggered)";
CM_ SG_ 663 PDU_DCDC_evt_Heater_SensorFlt "POD DC converter heater sensor fault event";
CM_ SG_ 663 POD_DCDC_evt_Mosfet_TSensFail "POD DC Converter Power MOS Tube Temperature Sensor Fault Event";
CM_ SG_ 663 POD_DCDC_evt_Mosfet_OverTemp "POD DC converter power MOS tube overheating event";
CM_ SG_ 663 PDU_DCDC_evt_Coldplate_TSensFail "POD DC Converter Cold Plate Temperature Sensor Fault Event";
CM_ SG_ 663 PDU_DCDC_evt_ColdPlate_OverTemp "POD DC converter cold plate overheating event";
CM_ SG_ 663 PDU_DCDC_evt_HeaterOverTemp "POD DC converter heater overheating event";
CM_ SG_ 663 PDU_DCDC_evt_HeaterShortIGBTFlt "POD DC converter heater IGBT short circuit fault event";
CM_ SG_ 663 POD_DCDC_evt_LV_ShortOutputFlt "POD DC Converter Low Voltage Output Short Circuit Fault Event";
CM_ SG_ 663 POD_DCDC_evt_reserved6 "POD DC Converter BMS High Voltage Interlock Event";
CM_ SG_ 663 POD_DCDC_evt_reserved5 "POD DC Converter BMS Collision Event";
CM_ SG_ 663 POD_DCDC_evt_PwrFail "POD DC converter power failure event";
CM_ SG_ 663 POD_DCDC_evt_Mosfet_HighTemp "POD DC Converter Power MOS Tube High Temperature Event";
CM_ SG_ 663 PDU_DCDC_evt_ColdPlate_HighTemp "POD DC Converter Cold Plate High Temperature Event";
CM_ SG_ 663 POD_DCDC_evt_Unchargeable "POD DC converter non rechargeable event";
CM_ SG_ 663 POD_DCDC_evt_reserved0 "POD DC converter reserved event 0";
CM_ SG_ 663 POD_DCDC_evt_reserved1 "POD DC converter reserved event 1";
CM_ SG_ 663 POD_DCDC_evt_reserved2 "POD DC converter reserved event 2";
CM_ SG_ 663 POD_DCDC_evt_reserved3 "POD DC Converter Reserve Event 3";
CM_ SG_ 663 POD_DCDC_evt_reserved4 "POD DC Converter Reserve Event 4";
CM_ SG_ 663 POD_DCDC_evt_SelfTestFlt "Self check fault event of POD DC converter";
CM_ SG_ 663 POD_DCDC_evt_PMICComFlt "POD DC Converter PMIC Communication Failure Event";
CM_ SG_ 663 POD_DCDC_evt_IOExpComFlt "POD DC Converter IO Expander Communication Failure Event";
CM_ SG_ 663 POD_DCDC_evt_WdgFlt "POD DC converter watchdog fault event";
CM_ SG_ 663 POD_DCDC_evt_PFMFlt "POD DC converter PFM fault event";
CM_ SG_ 663 POD_DCDC_evt_TCANFlt "POD DC Converter TCAN Fault Event";
CM_ SG_ 663 POD_DCDC_evt_LVOut_OverCurr_CMP "POD DC converter low voltage output overcurrent event (comparator triggered)";
CM_ SG_ 663 POD_DCDC_evt_LVOut_RevrsCurr_CMP "POD DC converter low voltage output reverse current event (comparator triggered)";
CM_ SG_ 663 POD_DCDC_evt_LVBat_OverVolt_CMP "POD DC converter low-voltage battery overvoltage event (comparator triggered)";
CM_ SG_ 663 POD_DCDC_evt_LVBat_UnderVolt_CMP "POD DC converter low voltage battery undervoltage event (comparator triggered)";
CM_ SG_ 663 POD_DCDC_evt_HVBat_OverVolt_CMP "POD DC converter high-voltage battery overvoltage event (comparator triggered)";
CM_ SG_ 663 POD_DCDC_evt_HVBat_UnderVolt_CMP "POD DC converter high-voltage battery undervoltage event (comparator triggered)";
CM_ SG_ 663 POD_DCDC_evt_LVOut_OverCurr_HW "POD DC Converter Low Voltage Output Overcurrent Event (Hardware Triggered)";
CM_ SG_ 663 POD_DCDC_evt_LVOut_OverVolt_HW "POD DC Converter Low Voltage Output Overvoltage Event (Hardware Triggered)";
CM_ SG_ 663 PDU_DCDC_evt_LVOut_UnderVolt_HW "POD DC Converter Low Voltage Output Undervoltage Event (Hardware Triggered)";
CM_ SG_ 663 POD_DCDC_evt_AuxPwrFlt_HW "POD DC converter auxiliary power failure event (hardware triggered)";
CM_ SG_ 663 POD_DCDC_evt_LVOut_OverVolt_SW "POD DC Converter Low Voltage Output Overvoltage Event (Software Triggered)";
CM_ SG_ 663 PDU_DCDC_evt_LVOut_UnderVolt_SW "POD DC Converter Low Voltage Output Undervoltage Event (Software Triggered)";
CM_ SG_ 664 POD_OBC_evt_Invert_iDCIn_ocflt_s "OBC inverter DC current input over current";
CM_ SG_ 664 POD_OBC_evt_Invert_vDCin_uvflt_s "OBC inverter DC  voltage input under voltage";
CM_ SG_ 664 POD_OBC_evt_Invert_vDCIn_ovflt_s "OBC inverter DC  voltage input over voltage";
CM_ SG_ 664 POD_OBC_evt_Invert_vACOut_ovflt_ "OBC inverter voltage Pfc under voltage";
CM_ SG_ 664 POD_OBC_evt_Invert_iACOut_ocflt_ "OBC inverter voltage Pfc over voltage";
CM_ SG_ 664 POD_OBC_evt_Invert_iACOut_o_0000 "OBC inverter AC current output over current";
CM_ SG_ 664 POD_OBC_evt_Invert_vACOut_o_0000 "OBC inverter AC voltage output over voltage";
CM_ SG_ 664 POD_OBC_evt_Invert_vACOut_uvflt_ "OBC inverter AC voltage output under voltage";
CM_ SG_ 664 POD_OBC_evt_Invert_iDCIn_ocflt_c "OBC inverter over temperature reduce power";
CM_ SG_ 664 POD_OBC_evt_Invert_vDCIn_ovflt_c "OBC inverter over temperature shutdown";
CM_ SG_ 664 POD_OBC_Inv_iACOut_ImBalFlt "V2L ac output current imbalance fault";
CM_ SG_ 664 POD_OBC_Inv_iACOut_ImBalWrn "V2L ac output current imbalance warning";
CM_ SG_ 664 POD_OBC_Inv_FET_OverTempFlt "V2L Mosfet over temp fault";
CM_ SG_ 664 POD_OBC_Inv_FET_TempWrn "V2L Mosfet over temp warning";
CM_ SG_ 664 POD_OBC_Inv_FET_UnderTempFlt "V2L Mosfet under temp fault";
CM_ SG_ 664 POD_OBC_Inv_Coolant_OverTempFlt "V2L Coolant over temp fault";
CM_ SG_ 664 POD_OBC_Inv_Coolant_TempWrn "V2L Coolant over temp warning";
CM_ SG_ 664 POD_OBC_Inv_Coolant_UnderTempFlt "V2L Coolant under temp fault";
CM_ SG_ 695 POD_OBC_Dischage_vDCInput "DC actual Voltage";
CM_ SG_ 695 POD_OBC_Dischage_iDCinput "DC actual current";
CM_ SG_ 695 POD_OBC_Dischage_vACOutput "AC actual Voltage";
CM_ SG_ 695 POD_OBC_Dischage_iACOutput "AC actual current";
CM_ SG_ 695 POD_OBC_BMS_MaxOutputCurAC "AC Max Output Current Available";
CM_ SG_ 695 POD_OBC_CVC_ACDisChgVoltAllow "CVC allow OBC Invert AC discharge voltage";
CM_ SG_ 695 POD_OBC_Invert_Power "OBC Invert Power";
CM_ SG_ 787 CRC_POD_OBC_StatusCharger1 "Check sum 0x313";
CM_ SG_ 787 ALIVE_POD_OBC_StatusCharger1 "Alive counter 0x313";
CM_ SG_ 787 POD_GTW_statusOBC "OBC status";
CM_ SG_ 787 POD_GTW_OBC_Max_Current_Out "Max DC current OBC able to output";
CM_ SG_ 787 POD_GTW_iDCOutput "GTW measured output current on OBC output";
CM_ SG_ 787 POD_GTW_vDCOutput "GTW measured bus voltage";
CM_ SG_ 803 CRC_POD_OBC_StatusCharger2 "Check sum 0x323";
CM_ SG_ 803 ALIVE_POD_OBC_StatusCharger2 "Alive counter 0x323";
CM_ SG_ 803 POD_GW_PhaseACInput "OBC Phase's Type value";
CM_ SG_ 803 POD_GW_iACInput "GTW measured current on AC input";
CM_ SG_ 803 POD_vACInput "GTW measured voltage on AC input";
CM_ SG_ 803 POD_tempACCharger "Reported AC Charger/OBC temperauture";
CM_ SG_ 803 POD_tempColdplate "Coolant temperature into the CPDU";
CM_ SG_ 870 PDU_DCDC_Thermal_CpltTemp "Overall comprehensive temperature of DCDC converter";
CM_ SG_ 870 PDU_DCDC_Thermal_IntTemp "Internal ambient temperature of DCDC converter";
CM_ SG_ 870 POD_DCDC_Thermal_NegBBTemp "Temperature of DCDC high-voltage negative busbar";
CM_ SG_ 870 POD_DCDC_Thermal_PosBBTemp "Temperature of DCDC high-voltage positive busbar";
CM_ SG_ 870 PDU_DCDC_Thermal_CoolPwrReq "DCDC cooling power request";
CM_ SG_ 870 PDU_DCDC_Thermal_FlowRateReq "DCDC coolant flow request";
CM_ SG_ 870 POD_DCDC_Thermal_PriFetTemp1 "Temperature of Field Effect Transistor 1";
CM_ SG_ 870 POD_DCDC_Thermal_PriFetTemp2 "Temperature of Field Effect Transistors 2";
CM_ SG_ 870 POD_DCDC_Thermal_OutFetTemp "Temperature of DCDC output side field-effect transistor";
CM_ SG_ 870 POD_DCDC_Thermal_SecFetTemp "Temperature of DCDC secondary side field-effect transistor";
CM_ SG_ 1172 CRC_POD_OBC_Err_Level "POD Checksum 0x494";
CM_ SG_ 1172 ALIVE_POD_OBC_Err_Level "POD Rolling Counter 0x494";
CM_ SG_ 1172 POD_OBC_Error_level_reversed0 "POD OBC Error level reversed0";
CM_ SG_ 1172 POD_OBC_Err_Lvl "POD OBC Err Lvl";
CM_ SG_ 1172 POD_OBC_Error_level_reversed1 "POD OBC Error level reversed1";
CM_ SG_ 1172 POD_OBC_Error_level_reversed2 "POD OBC Error level reversed2";
CM_ SG_ 1172 POD_OBC_Error_level_reversed3 "POD OBC Error level reversed3";
CM_ SG_ 1172 POD_OBC_Error_level_reversed4 "POD OBC Error level reversed4";
CM_ SG_ 1172 POD_OBC_Error_level_reversed5 "POD OBC Error level reversed5";
CM_ SG_ 1172 POD_OBC_Error_level_reversed6 "POD OBC Error level reversed6";
CM_ SG_ 1864 POD_OBC_Major_App_Ver "POD OBC CPU1 major application version";
CM_ SG_ 1864 POD_OBC_Minor_App_Ver "POD OBC CPU1 minor application version";
CM_ SG_ 1864 POD_OBC_Subminor_App_Ver "POD OBC CPU1 subminor application version";
CM_ SG_ 1864 POD_OBC_Major_Boot_Ver "OBC CPU2 app's major version";
CM_ SG_ 1864 POD_OBC_Minor_Boot_Ver "OBC CPU2 App's minor version";
CM_ SG_ 1864 POD_OBC_Subminor_Boot_Ver "OBC CPU2 App's sub minor version";
CM_ SG_ 1864 POD_OBC_Variant "OBC variant:";
CM_ SG_ 1864 POD_OBC_DCLinkVolt "information to debug related to DClink voltage";
CM_ SG_ 1870 POD_OBC_evt_iLine1SensorErr "Line1 Current Sensor Error";
CM_ SG_ 1870 POD_OBC_evt_fLineUFFlt "Line Frequency Under Fault";
CM_ SG_ 1870 POD_OBC_evt_fLineOFFlt "Line Frequency Over Fault";
CM_ SG_ 1870 POD_OBC_evt_fault_latch "The fault signal of Common Fault Latch Circuit is set";
CM_ SG_ 1870 POD_OBC_evt_eStopFlt "OBC SW Emergency Stop Fault";
CM_ SG_ 1870 POD_OBC_evt_iLineImbalWrn "Line Current Imbalance Warning";
CM_ SG_ 1870 POD_OBC_evt_iLineImbalFlt "Line Current Imbalance Fault";
CM_ SG_ 1870 POD_OBC_evt_iline_ocflt_sw_rms "Monitoring  SW Line Over Current Fault status";
CM_ SG_ 1870 POD_OBC_evt_iline_ocflt_hw_trig "Monitoring  HW Line Over Current Fault status";
CM_ SG_ 1870 POD_OBC_evt_iline_ocflt_cmp_trig "Monitoring  CMPSS Line Over Current Fault status";
CM_ SG_ 1870 POD_OBC_evt_iLine2SensorErr "Line2 Current Sensor Error";
CM_ SG_ 1870 POD_OBC_evt_pfcerr "Monitoring  PFC stage Error status";
CM_ SG_ 1870 POD_OBC_evt_iOutSensorErr "Output Current Sensor Error";
CM_ SG_ 1870 POD_OBC_evt_iOutOCFlt_SW "Output Over Current Fault triggered by SW";
CM_ SG_ 1870 POD_OBC_evt_iOutOCFlt_HW "Output Over Current Fault triggered by HW";
CM_ SG_ 1870 POD_OBC_evt_iOutOCFlt_CMP "Output Over Current Fault triggered by compare event";
CM_ SG_ 1870 POD_OBC_evt_iOutNEGOCFlt_HW "Output Over Current Fault Trigger by tripzone GPIO signal";
CM_ SG_ 1870 POD_OBC_evt_iOutNEGOCFlt_CMP "Output Over Current Fault Trigger by CMPSS compare event";
CM_ SG_ 1870 POD_OBC_evt_secCurrFlt_SW "Primary Current #2 bridge is fault detected by Software";
CM_ SG_ 1870 POD_OBC_evt_secCurrFlt_CMP "Primary Current 2 Fault Trigger by CMPSS compare event";
CM_ SG_ 1870 POD_OBC_evt_priCurrFlt_SW "Primary Current #1 bridge is fault detected by Software";
CM_ SG_ 1870 POD_OBC_evt_priCurrFlt_CMP "Primary Over Current 1 Fault Trigger by CMPSS compare event";
CM_ SG_ 1870 POD_OBC_evt_BusOff "E2E fault of CAN messages which are pre-condition for FOTA";
CM_ SG_ 1870 POD_OBC_evt_Coolant_Temp_Warn "Warning Temperature fault is found by QM monitoring";
CM_ SG_ 1870 POD_OBC_evt_Coolant_OverTemp "Over Temperature fault is found by QM monitoring";
CM_ SG_ 1870 POD_OBC_evt_PwrOutOPFLt "Over power output fault";
CM_ SG_ 1870 POD_OBC_evt_PT_mia "MIA Fault of CAN message sent from PT CAN";
CM_ SG_ 1870 POD_OBC_evt_PT_DataInvalid "Data invalid fault of CAN message sent from CVC";
CM_ SG_ 1870 POD_OBC_evt_PT_ChsFlt "Check Sum Fault of CAN message sent from PT CAN";
CM_ SG_ 1870 POD_OBC_evt_PT_AlvFlt "Alive Counter Fault of CAN message sent from PT CAN";
CM_ SG_ 1870 POD_OBC_evt_dchvErr "PSFB Error";
CM_ SG_ 1870 POD_OBC_evt_vDCLinkOVFlt_HW "DC Link Overvoltage Fault triggered by HW";
CM_ SG_ 1870 POD_OBC_evt_FET_UnderTemp "Under Temperature fault is found by Safety Monitoring";
CM_ SG_ 1870 POD_OBC_evt_FET_Temp_Warn "Warning Temperature fault is found by Safety Monitoring";
CM_ SG_ 1870 POD_OBC_evt_FET_Temp_SensorFlt "Temperature Sensor for Safety monitoring is fault";
CM_ SG_ 1870 POD_OBC_evt_FET_OverTemp "Over Temperature fault is found by Safety Monitoring";
CM_ SG_ 1870 POD_OBC_evt_Coolant_UnderTemp "Under Temperature fault is found by QM monitoring";
CM_ SG_ 1870 POD_OBC_evt_Coolant_Temp_SensorF "Cold Plate under temperature fault";
CM_ SG_ 1870 POD_OBC_evt_vout_ovflt_cmp_trig "Monitoring  CMPSS Output Over voltage Fault status";
CM_ SG_ 1870 POD_OBC_evt_vLineUVFlt "Line Undervoltage Fault";
CM_ SG_ 1870 POD_OBC_evt_vLineOVFlt "Line Overvoltage Fault";
CM_ SG_ 1870 POD_OBC_evt_vDCLinkUVFlt "DC Link Undervoltage Fault";
CM_ SG_ 1870 POD_OBC_evt_vDCLinkPchgFail "DC Link Precharge Failure";
CM_ SG_ 1870 POD_OBC_evt_vDCLinkOVFlt_SW "DC Link Overvoltage Fault triggered by SW";
CM_ SG_ 1870 POD_OBC_evt_vout_uvflt_sw_trig "Monitoring  SW Output Under voltage Fault status";
CM_ SG_ 1870 POD_OBC_evt_Vout_SensorErr "Output Voltage Sensor Error";
CM_ SG_ 1870 POD_OBC_evt_vout_ovflt_sw_trig "Monitoring  SW Output Over voltage Fault status";
CM_ SG_ 1870 POD_OBC_evt_vout_ovflt_hw_trig "Monitoring  HW Output Over voltage Fault status";
CM_ SG_ 1870 POD_OBC_evt_SFT_PMICFail "OBC external PMIC failure";
CM_ SG_ 1870 POD_OBC_evt_SFT_PFMFail "OBC PFM failure";
CM_ SG_ 1870 POD_OBC_evt_SFT_MemFail "OBC MCU internal memory (SRAM/CAN message RAM/Flash) failure";
CM_ SG_ 1870 POD_OBC_evt_SFT_ExtWDGFail "OBC external watchdog failure";
CM_ SG_ 1870 POD_OBC_evt_SFT_ClockFail "OBC MCU clock missing failure";
CM_ SG_ 1870 POD_OBC_evt_SFT_ADCFail "OBC MCU open/shorted ADC input failure";
CM_ SG_ 1870 POD_OBC_evt_ExtMem_Flt "Ext Flash Memory fault";
CM_ SG_ 1870 POD_OBC_evt_Threscheck_Flt "Threshold check fault";
CM_ SG_ 1870 POD_OBC_evt_SWData_Corrupt "The Software finds a corrupted data error";
CM_ SG_ 1870 POD_OBC_evt_SOPT_Flt "OBC Selftest Fault";
CM_ SG_ 341 POD_DCDC_Error_level_reversed0 "POD DCDC Error level reversed0";
CM_ SG_ 341 POD_DCDC_Err_Lvl "POD DCDC Err Lvl";
CM_ SG_ 341 POD_DCFC_Err_Lvl "POD DCFC Err Lvl";
CM_ SG_ 341 POD_DCDC_Error_level_reversed1 "POD DCDC Error level reversed1";
CM_ SG_ 341 POD_DCDC_Error_level_reversed2 "POD DCDC Error level reversed2";
CM_ SG_ 341 POD_DCDC_Error_level_reversed3 "POD DCDC Error level reversed3";
CM_ SG_ 341 POD_DCDC_Error_level_reversed4 "POD DCDC Error level reversed4";
CM_ SG_ 341 POD_DCDC_Error_level_reversed5 "POD DCDC Error level reversed5";
CM_ SG_ 341 POD_DCDC_Error_level_reversed6 "POD DCDC Error level reversed6";
CM_ SG_ 211 RCUO_FualtLevel_enum "RCU fault level";
CM_ SG_ 211 RCUO_PtAllowPwrMax "Maximum allowable power generation";
CM_ SG_ 211 RCUO_PtAllowPwrMin "Minimum allowable power generation";
CM_ SG_ 211 RCUO_WorkingSta_enum "RCU working status";
CM_ SG_ 211 RCUO_VehAvgFuleCnsm_Lp100km "100km/L fuel consumption";
CM_ SG_ 211 RCUO_ErrorCode_enum "RCU fault code";
CM_ SG_ 211 RCUO_TolFltNum_enum "Statistics on the number of RCU fault codes";
CM_ SG_ 298 RCUO_RCUActOutpPwr_kW "Actual generator power";
CM_ SG_ 298 PCU_FaultSts "PCU_FaultSts";
CM_ SG_ 298 PCU_FastTorqueFlag "PCU fast torque flag";
CM_ SG_ 298 PCU_CVC_ActvDischg_Sts "REX active discharge status";
CM_ SG_ 298 PCU_CVC_GenVoltAct "Actual generator voltage";
CM_ SG_ 298 PCU_CVC_GenCurrAct "Actual generator current";
CM_ SG_ 298 PCU_EngineFuelLvl "Engine fuel level";
CM_ SG_ 298 PCU_LowOilAlert "Low fuel alarm";
CM_ SG_ 298 PCU_FlowRate_Req "PCU waterpump request";
CM_ SG_ 298 EMS_ElectricFan_Req "EMS fan speed request";
CM_ SG_ 299 EMS_stMode "Enigne mode";
CM_ SG_ 299 EMS_EngSpd "Actual engine speed";
CM_ SG_ 299 EMS_EngTq "Actual engine torque";
CM_ SG_ 299 EMS_ClntTmp "Engine coolant temperature";
CM_ SG_ 300 GCU_ControlMode "Actual generator control mode";
CM_ SG_ 300 GCU_ISGSpd "Actual generator speed";
CM_ SG_ 300 GCU_ISGTq "Actual generator torque";
CM_ SG_ 301 RCU_FuelCutoffRequest "Engine fuel cut off request";
CM_ SG_ 301 RCU_EngTorqueCmd "Engine torque command";
CM_ SG_ 301 RCU_EnIdleTrgtSpdCmd "Engine Idle Target Speed command";
CM_ SG_ 302 RCU_GCUEnableReq "Generator enable request";
CM_ SG_ 302 RCU_GCUControlMode "Generator control mode request";
CM_ SG_ 302 RCU_GCUTorqueCmd "Generator torque command";
CM_ SG_ 302 RCU_GCUSpeedCmd "Generator speed command";
CM_ SG_ 302 RCU_GCUTorqueLimit "Generator torque limit";
CM_ SG_ 378 GCU_ISGTemp "Generator controller temperature";
CM_ SG_ 378 GCU_IGBTATemp "Generator controller temperature A";
CM_ SG_ 378 GCU_IGBTBTemp "Generator controller temperature B";
CM_ SG_ 378 GCU_IGBTCTemp "Generator controller temperature C";
CM_ SG_ 553 CRC_ADCU_COOLING_REQ "Checksum";
CM_ SG_ 553 ALIVE_ADCU_COOLING_REQ "Alive Counter";
CM_ SG_ 553 ADCU_Cooling_Req "ADCU Cooling Request";
CM_ SG_ 1282 CVC_srcNodeID "Network Management Signal";
CM_ SG_ 1282 CVC_CtrlBitVector "Network Management Signal";
CM_ SG_ 1282 CVC_usrData0 "Network Management Signal";
CM_ SG_ 1282 CVC_usrData1 "Network Management Signal";
CM_ SG_ 1282 CVC_usrData2 "Network Management Signal";
CM_ SG_ 1282 CVC_usrData3 "Network Management Signal";
CM_ SG_ 1282 CVC_usrData4 "Network Management Signal";
CM_ SG_ 1282 CVC_usrData5 "Network Management Signal";
CM_ SG_ 1299 BMS_srcNodeID "Network Management Signal";
CM_ SG_ 1299 BMS_CtrlBitVector "Network Management Signal";
CM_ SG_ 1299 BMS_usrData0 "Network Management Signal";
CM_ SG_ 1299 BMS_usrData1 "Network Management Signal";
CM_ SG_ 1299 BMS_usrData2 "Network Management Signal";
CM_ SG_ 1299 BMS_usrData3 "Network Management Signal";
CM_ SG_ 1299 BMS_usrData4 "Network Management Signal";
CM_ SG_ 1299 BMS_usrData5 "Network Management Signal";
CM_ SG_ 1306 RMCU_srcNodeID "Network Management Signal";
CM_ SG_ 1306 RMCU_CtrlBitVector "Network Management Signal";
CM_ SG_ 1306 RMCU_usrData0 "Network Management Signal";
CM_ SG_ 1306 RMCU_usrData1 "Network Management Signal";
CM_ SG_ 1306 RMCU_usrData2 "Network Management Signal";
CM_ SG_ 1306 RMCU_usrData3 "Network Management Signal";
CM_ SG_ 1306 RMCU_usrData4 "Network Management Signal";
CM_ SG_ 1306 RMCU_usrData5 "Network Management Signal";
CM_ SG_ 1307 FMCU_srcNodeID "Network Management Signal";
CM_ SG_ 1307 FMCU_CtrlBitVector "Network Management Signal";
CM_ SG_ 1307 FMCU_usrData0 "Network Management Signal";
CM_ SG_ 1307 FMCU_usrData1 "Network Management Signal";
CM_ SG_ 1307 FMCU_usrData2 "Network Management Signal";
CM_ SG_ 1307 FMCU_usrData3 "Network Management Signal";
CM_ SG_ 1307 FMCU_usrData4 "Network Management Signal";
CM_ SG_ 1307 FMCU_usrData5 "Network Management Signal";
CM_ SG_ 1311 EVCC_srcNodeID "Network Management Signal";
CM_ SG_ 1311 EVCC_CtrlBitVector "Network Management Signal";
CM_ SG_ 1311 EVCC_usrData0 "Network Management Signal";
CM_ SG_ 1311 EVCC_usrData1 "Network Management Signal";
CM_ SG_ 1311 EVCC_usrData2 "Network Management Signal";
CM_ SG_ 1311 EVCC_usrData3 "Network Management Signal";
CM_ SG_ 1311 EVCC_usrData4 "Network Management Signal";
CM_ SG_ 1311 EVCC_usrData5 "Network Management Signal";
CM_ SG_ 1336 PCU_srcNodeID "Network Management Signal";
CM_ SG_ 1336 PCU_CtrlBitVector "Network Management Signal";
CM_ SG_ 1336 PCU_usrData0 "Network Management Signal";
CM_ SG_ 1336 PCU_usrData1 "Network Management Signal";
CM_ SG_ 1336 PCU_usrData2 "Network Management Signal";
CM_ SG_ 1336 PCU_usrData3 "Network Management Signal";
CM_ SG_ 1336 PCU_usrData4 "Network Management Signal";
CM_ SG_ 1336 PCU_usrData5 "Network Management Signal";
CM_ SG_ 1341 POD_srcNodeID "Network Management Signal";
CM_ SG_ 1341 POD_CtrlBitVector "Network Management Signal";
CM_ SG_ 1341 POD_usrData0 "Network Management Signal";
CM_ SG_ 1341 POD_usrData1 "Network Management Signal";
CM_ SG_ 1341 POD_usrData2 "Network Management Signal";
CM_ SG_ 1341 POD_usrData3 "Network Management Signal";
CM_ SG_ 1341 POD_usrData4 "Network Management Signal";
CM_ SG_ 1341 POD_usrData5 "Network Management Signal";
CM_ SG_ 1683 BMS_DiagReqData0 "Data0";
CM_ SG_ 1683 BMS_DiagReqData1 "Data1";
CM_ SG_ 1683 BMS_DiagReqData2 "Data2";
CM_ SG_ 1683 BMS_DiagReqData3 "Data3";
CM_ SG_ 1683 BMS_DiagReqData4 "Data4";
CM_ SG_ 1683 BMS_DiagReqData5 "Data5";
CM_ SG_ 1683 BMS_DiagReqData6 "Data6";
CM_ SG_ 1683 BMS_DiagReqData7 "Data7";
CM_ SG_ 1683 BMS_DiagReqData8 "Data8";
CM_ SG_ 1683 BMS_DiagReqData9 "Data9";
CM_ SG_ 1683 BMS_DiagReqData10 "Data10";
CM_ SG_ 1683 BMS_DiagReqData11 "Data11";
CM_ SG_ 1683 BMS_DiagReqData12 "Data12";
CM_ SG_ 1683 BMS_DiagReqData13 "Data13";
CM_ SG_ 1683 BMS_DiagReqData14 "Data14";
CM_ SG_ 1683 BMS_DiagReqData15 "Data15";
CM_ SG_ 1683 BMS_DiagReqData16 "Data16";
CM_ SG_ 1683 BMS_DiagReqData17 "Data17";
CM_ SG_ 1683 BMS_DiagReqData18 "Data18";
CM_ SG_ 1683 BMS_DiagReqData19 "Data19";
CM_ SG_ 1683 BMS_DiagReqData20 "Data20";
CM_ SG_ 1683 BMS_DiagReqData21 "Data21";
CM_ SG_ 1683 BMS_DiagReqData22 "Data22";
CM_ SG_ 1683 BMS_DiagReqData23 "Data23";
CM_ SG_ 1683 BMS_DiagReqData24 "Data24";
CM_ SG_ 1683 BMS_DiagReqData25 "Data25";
CM_ SG_ 1683 BMS_DiagReqData26 "Data26";
CM_ SG_ 1683 BMS_DiagReqData27 "Data27";
CM_ SG_ 1683 BMS_DiagReqData28 "Data28";
CM_ SG_ 1683 BMS_DiagReqData29 "Data29";
CM_ SG_ 1683 BMS_DiagReqData30 "Data30";
CM_ SG_ 1683 BMS_DiagReqData31 "Data31";
CM_ SG_ 1683 BMS_DiagReqData32 "Data32";
CM_ SG_ 1683 BMS_DiagReqData33 "Data33";
CM_ SG_ 1683 BMS_DiagReqData34 "Data34";
CM_ SG_ 1683 BMS_DiagReqData35 "Data35";
CM_ SG_ 1683 BMS_DiagReqData36 "Data36";
CM_ SG_ 1683 BMS_DiagReqData37 "Data37";
CM_ SG_ 1683 BMS_DiagReqData38 "Data38";
CM_ SG_ 1683 BMS_DiagReqData39 "Data39";
CM_ SG_ 1683 BMS_DiagReqData40 "Data40";
CM_ SG_ 1683 BMS_DiagReqData41 "Data41";
CM_ SG_ 1683 BMS_DiagReqData42 "Data42";
CM_ SG_ 1683 BMS_DiagReqData43 "Data43";
CM_ SG_ 1683 BMS_DiagReqData44 "Data44";
CM_ SG_ 1683 BMS_DiagReqData45 "Data45";
CM_ SG_ 1683 BMS_DiagReqData46 "Data46";
CM_ SG_ 1683 BMS_DiagReqData47 "Data47";
CM_ SG_ 1683 BMS_DiagReqData48 "Data48";
CM_ SG_ 1683 BMS_DiagReqData49 "Data49";
CM_ SG_ 1683 BMS_DiagReqData50 "Data50";
CM_ SG_ 1683 BMS_DiagReqData51 "Data51";
CM_ SG_ 1683 BMS_DiagReqData52 "Data52";
CM_ SG_ 1683 BMS_DiagReqData53 "Data53";
CM_ SG_ 1683 BMS_DiagReqData54 "Data54";
CM_ SG_ 1683 BMS_DiagReqData55 "Data55";
CM_ SG_ 1683 BMS_DiagReqData56 "Data56";
CM_ SG_ 1683 BMS_DiagReqData57 "Data57";
CM_ SG_ 1683 BMS_DiagReqData58 "Data58";
CM_ SG_ 1683 BMS_DiagReqData59 "Data59";
CM_ SG_ 1683 BMS_DiagReqData60 "Data60";
CM_ SG_ 1683 BMS_DiagReqData61 "Data61";
CM_ SG_ 1683 BMS_DiagReqData62 "Data62";
CM_ SG_ 1683 BMS_DiagReqData63 "Data63";
BA_DEF_ BO_  "DiagRequest" ENUM  "No","Yes";
BA_DEF_ BO_  "DiagResponse" ENUM  "No","Yes";
BA_DEF_ BO_  "DiagState" ENUM  "No","Yes";
BA_DEF_ BO_  "GenMsgCycleTime" INT 0 65535;
BA_DEF_ BO_  "GenMsgCycleTimeFast" INT 0 65535;
BA_DEF_ BO_  "GenMsgDelayTime" INT 0 65535;
BA_DEF_ BO_  "GenMsgILSupport" ENUM  "No","Yes";
BA_DEF_ BO_  "GenMsgNrOfRepetition" INT 0 65535;
BA_DEF_ BO_  "GenMsgSendType" ENUM  "Cyclic","NoMsgSendType","NotUsed","NotUsed","NotUsed","NotUsed","NotUsed","IfActive","NoMsgSendType","NotUsed";
BA_DEF_ BO_  "NmAsrMessage" ENUM  "No","Yes";
BA_DEF_ BO_  "NmMessage" ENUM  "No","Yes";
BA_DEF_ SG_  "GenSigSendType" ENUM  "Cyclic","NoSigSendType","OnWriteWithRepetition","OnChange","OnChangeWithRepetition","IfActive","IfActiveWithRepetition","OnWrite","NotUsed","NotUsed","NotUsed","NotUsed","NotUsed";
BA_DEF_ SG_  "GenSigStartValue" INT 0 2147483647;
BA_DEF_ SG_  "GenSigTimeoutTime_ALL" INT 0 65535;
BA_DEF_ SG_  "InvalidValue" STRING ;
BA_DEF_ SG_  "GenSigInactiveValue" INT 0 2147483647;
BA_DEF_ BO_  "VFrameFormat" ENUM  "StandardCAN","ExtendedCAN","reserved","J1939PG","reserved","reserved","reserved","reserved","reserved","reserved","reserved","reserved","reserved","reserved","StandardCAN_FD","ExtendedCAN_FD";
BA_DEF_ BO_  "CANFD_BRS" ENUM  "0","1";
BA_DEF_ SG_  "SystemSignalLongSymbol" STRING ;
BA_DEF_DEF_  "DiagRequest" "No";
BA_DEF_DEF_  "DiagResponse" "No";
BA_DEF_DEF_  "DiagState" "No";
BA_DEF_DEF_  "GenMsgCycleTime" 0;
BA_DEF_DEF_  "GenMsgCycleTimeFast" 0;
BA_DEF_DEF_  "GenMsgDelayTime" 0;
BA_DEF_DEF_  "GenMsgILSupport" "Yes";
BA_DEF_DEF_  "GenMsgNrOfRepetition" 0;
BA_DEF_DEF_  "GenMsgSendType" "Cyclic";
BA_DEF_DEF_  "NmAsrMessage" "No";
BA_DEF_DEF_  "NmMessage" "No";
BA_DEF_DEF_  "GenSigSendType" "Cyclic";
BA_DEF_DEF_  "GenSigStartValue" 0;
BA_DEF_DEF_  "GenSigTimeoutTime_ALL" 0;
BA_DEF_DEF_  "InvalidValue" "";
BA_DEF_DEF_  "GenSigInactiveValue" 0;
BA_DEF_DEF_  "VFrameFormat" "StandardCAN_FD";
BA_DEF_DEF_  "CANFD_BRS" "1";
BA_DEF_DEF_  "SystemSignalLongSymbol" "";
BA_ "GenMsgCycleTime" BO_ 201 10;
BA_ "GenMsgCycleTime" BO_ 202 10;
BA_ "GenMsgCycleTime" BO_ 338 10;
BA_ "GenMsgCycleTime" BO_ 368 10;
BA_ "GenMsgCycleTime" BO_ 568 20;
BA_ "GenMsgCycleTime" BO_ 872 100;
BA_ "GenMsgCycleTime" BO_ 873 100;
BA_ "GenMsgCycleTime" BO_ 1080 100;
BA_ "GenMsgCycleTime" BO_ 1083 100;
BA_ "GenMsgCycleTime" BO_ 1085 100;
BA_ "GenMsgCycleTime" BO_ 1087 100;
BA_ "GenMsgCycleTime" BO_ 1179 1000;
BA_ "GenMsgSendType" BO_ 1976 1;
BA_ "GenMsgNrOfRepetition" BO_ 1976 2;
BA_ "GenMsgCycleTimeFast" BO_ 1976 50;
BA_ "GenMsgCycleTime" BO_ 91 100;
BA_ "GenMsgCycleTime" BO_ 203 10;
BA_ "GenMsgCycleTime" BO_ 204 10;
BA_ "GenMsgCycleTime" BO_ 339 10;
BA_ "GenMsgCycleTime" BO_ 369 10;
BA_ "GenMsgCycleTime" BO_ 569 20;
BA_ "GenMsgCycleTime" BO_ 874 100;
BA_ "GenMsgCycleTime" BO_ 875 100;
BA_ "GenMsgCycleTime" BO_ 1081 100;
BA_ "GenMsgCycleTime" BO_ 1082 100;
BA_ "GenMsgCycleTime" BO_ 1084 100;
BA_ "GenMsgCycleTime" BO_ 1091 100;
BA_ "GenMsgCycleTime" BO_ 1178 1000;
BA_ "GenMsgCycleTime" BO_ 661 20;
BA_ "GenMsgCycleTime" BO_ 662 100;
BA_ "GenMsgCycleTime" BO_ 663 100;
BA_ "GenMsgCycleTime" BO_ 664 100;
BA_ "GenMsgCycleTime" BO_ 695 100;
BA_ "GenMsgCycleTime" BO_ 787 100;
BA_ "GenMsgCycleTime" BO_ 803 100;
BA_ "GenMsgCycleTime" BO_ 870 100;
BA_ "GenMsgCycleTime" BO_ 1128 1000;
BA_ "GenMsgCycleTime" BO_ 1141 100;
BA_ "GenMsgCycleTime" BO_ 1172 1000;
BA_ "GenMsgCycleTime" BO_ 1864 100;
BA_ "GenMsgCycleTime" BO_ 1870 100;
BA_ "GenMsgCycleTime" BO_ 341 500;
BA_ "GenMsgCycleTime" BO_ 211 20;
BA_ "GenMsgCycleTime" BO_ 298 100;
BA_ "GenMsgCycleTime" BO_ 299 100;
BA_ "GenMsgCycleTime" BO_ 300 100;
BA_ "GenMsgCycleTime" BO_ 301 100;
BA_ "GenMsgCycleTime" BO_ 302 100;
BA_ "GenMsgCycleTime" BO_ 378 100;
BA_ "GenMsgCycleTime" BO_ 1909 100;
BA_ "GenMsgCycleTime" BO_ 553 100;
BA_ "GenMsgILSupport" BO_ 1282 0;
BA_ "GenMsgCycleTime" BO_ 1282 640;
BA_ "VFrameFormat" BO_ 1282 0;
BA_ "NmAsrMessage" BO_ 1282 1;
BA_ "NmMessage" BO_ 1282 1;
BA_ "GenMsgILSupport" BO_ 1299 0;
BA_ "GenMsgCycleTime" BO_ 1299 640;
BA_ "VFrameFormat" BO_ 1299 0;
BA_ "NmAsrMessage" BO_ 1299 1;
BA_ "NmMessage" BO_ 1299 1;
BA_ "GenMsgILSupport" BO_ 1306 0;
BA_ "GenMsgCycleTime" BO_ 1306 640;
BA_ "VFrameFormat" BO_ 1306 0;
BA_ "NmAsrMessage" BO_ 1306 1;
BA_ "NmMessage" BO_ 1306 1;
BA_ "GenMsgILSupport" BO_ 1307 0;
BA_ "GenMsgCycleTime" BO_ 1307 640;
BA_ "VFrameFormat" BO_ 1307 0;
BA_ "NmAsrMessage" BO_ 1307 1;
BA_ "NmMessage" BO_ 1307 1;
BA_ "GenMsgILSupport" BO_ 1311 0;
BA_ "GenMsgCycleTime" BO_ 1311 640;
BA_ "VFrameFormat" BO_ 1311 0;
BA_ "NmAsrMessage" BO_ 1311 1;
BA_ "NmMessage" BO_ 1311 1;
BA_ "GenMsgILSupport" BO_ 1336 0;
BA_ "GenMsgCycleTime" BO_ 1336 640;
BA_ "VFrameFormat" BO_ 1336 0;
BA_ "NmAsrMessage" BO_ 1336 1;
BA_ "NmMessage" BO_ 1336 1;
BA_ "GenMsgILSupport" BO_ 1341 0;
BA_ "GenMsgCycleTime" BO_ 1341 640;
BA_ "VFrameFormat" BO_ 1341 0;
BA_ "NmAsrMessage" BO_ 1341 1;
BA_ "NmMessage" BO_ 1341 1;
BA_ "GenMsgILSupport" BO_ 1683 0;
BA_ "DiagState" BO_ 1683 1;
BA_ "GenMsgSendType" BO_ 1683 1;
BA_ "DiagRequest" BO_ 1683 1;
BA_ "InvalidValue" SG_ 201 ALIVE_FMCU_Status "Fh";
BA_ "GenSigStartValue" SG_ 201 FMCU_MotorTq 4000;
BA_ "GenSigStartValue" SG_ 201 FMCU_MotorSpd 20000;
BA_ "InvalidValue" SG_ 201 FMCU_StsMCUFault "Fh";
BA_ "InvalidValue" SG_ 201 FMCU_MotorSpdSts "1h";
BA_ "InvalidValue" SG_ 201 FMCU_MotorTqSts "1h";
BA_ "InvalidValue" SG_ 201 FMCU_CVC_CtrlMode "Fh";
BA_ "InvalidValue" SG_ 201 FMCU_CVC_StsMode "Fh";
BA_ "InvalidValue" SG_ 202 ALIVE_FMCU_Ability "Fh";
BA_ "InvalidValue" SG_ 202 FMCU_CVC_PosTrqLmt "FFFh";
BA_ "GenSigStartValue" SG_ 202 FMCU_CVC_NegTrqLmt 4000;
BA_ "InvalidValue" SG_ 202 FMCU_CVC_NegTrqLmt "FFFh";
BA_ "GenSigStartValue" SG_ 202 FMCU_ActInputCurrent 2000;
BA_ "GenSigStartValue" SG_ 338 FMCU_FS_MCUTemp 50;
BA_ "GenSigStartValue" SG_ 338 FMCU_FS_MotTemp 50;
BA_ "GenSigStartValue" SG_ 338 FMCU_FS_TrqBlend 4000;
BA_ "GenSigStartValue" SG_ 368 FMCU_PhaseCurW 125;
BA_ "GenSigStartValue" SG_ 368 FMCU_PhaseCurV 125;
BA_ "GenSigStartValue" SG_ 368 FMCU_PhaseCurU 125;
BA_ "GenSigStartValue" SG_ 368 FMCU_MaxSpeedAllow 34000;
BA_ "GenSigStartValue" SG_ 368 FMCU_PhaseCurPeak 125;
BA_ "GenSigStartValue" SG_ 568 FMCU_IGBT_WTemp 50;
BA_ "GenSigStartValue" SG_ 568 FMCU_IGBT_VTemp 50;
BA_ "GenSigStartValue" SG_ 568 FMCU_IGBT_UTemp 50;
BA_ "GenSigStartValue" SG_ 568 FMCU_JunctionIGBT_WTemp 50;
BA_ "GenSigStartValue" SG_ 568 FMCU_JunctionIGBT_VTemp 50;
BA_ "GenSigStartValue" SG_ 568 FMCU_JunctionIGBT_UTemp 50;
BA_ "GenSigStartValue" SG_ 873 FMCU_CoolantTemp 50;
BA_ "InvalidValue" SG_ 873 FMCU_CoolantTemp "FFh";
BA_ "GenSigStartValue" SG_ 873 FMCU_MCUTemp 40;
BA_ "InvalidValue" SG_ 873 FMCU_MCUTemp "FFh";
BA_ "GenSigStartValue" SG_ 873 FMCU_MotorTemp 40;
BA_ "InvalidValue" SG_ 873 FMCU_MotorTemp "FFh";
BA_ "GenSigStartValue" SG_ 873 FMCU_MCUBoardTemp 40;
BA_ "InvalidValue" SG_ 873 FMCU_MCUBoardTemp "FFh";
BA_ "InvalidValue" SG_ 873 FMCU_StsActiveDischg "Fh";
BA_ "InvalidValue" SG_ 873 FMCU_TBOX_ModeMotorDrv "Fh";
BA_ "GenSigStartValue" SG_ 873 FMCU_MotorTemp1 40;
BA_ "InvalidValue" SG_ 873 FMCU_MotorTemp1 "FFh";
BA_ "GenSigStartValue" SG_ 873 FMCU_MotorTemp2 40;
BA_ "InvalidValue" SG_ 873 FMCU_MotorTemp2 "FFh";
BA_ "InvalidValue" SG_ 1179 ALIVE_FMCU_WarnMsg "Fh";
BA_ "GenSigSendType" SG_ 1976 FMCU_Req_RandomData 2;
BA_ "GenSigSendType" SG_ 1976 FMCU_Req_MAC 2;
BA_ "InvalidValue" SG_ 203 ALIVE_RMCU_Status "Fh";
BA_ "GenSigStartValue" SG_ 203 RMCU_MotorTq 4000;
BA_ "GenSigStartValue" SG_ 203 RMCU_MotorSpd 20000;
BA_ "InvalidValue" SG_ 203 RMCU_StsMCUFault "Fh";
BA_ "InvalidValue" SG_ 203 RMCU_MotorSpdValid "1h";
BA_ "InvalidValue" SG_ 203 RMCU_MotorTqValid "1h";
BA_ "InvalidValue" SG_ 203 RMCU_CVC_CtrlMode "Fh";
BA_ "InvalidValue" SG_ 203 RMCU_CVC_StsMode "Fh";
BA_ "InvalidValue" SG_ 204 ALIVE_RMCU_Ability "Fh";
BA_ "InvalidValue" SG_ 204 RMCU_CVC_PosTrqLmt "FFFh";
BA_ "GenSigStartValue" SG_ 204 RMCU_CVC_NegTrqLmt 4000;
BA_ "InvalidValue" SG_ 204 RMCU_CVC_NegTrqLmt "FFFh";
BA_ "GenSigStartValue" SG_ 204 RMCU_ActInputCurrent 2000;
BA_ "GenSigStartValue" SG_ 339 RMCU_FS_MCUTemp 50;
BA_ "GenSigStartValue" SG_ 339 RMCU_FS_MotTemp 50;
BA_ "GenSigStartValue" SG_ 339 RMCU_FS_TrqBlend 4000;
BA_ "GenSigStartValue" SG_ 369 RMCU_PhaseCurW 125;
BA_ "GenSigStartValue" SG_ 369 RMCU_PhaseCurV 125;
BA_ "GenSigStartValue" SG_ 369 RMCU_PhaseCurU 125;
BA_ "GenSigStartValue" SG_ 369 RMCU_MaxSpeedAllow 34000;
BA_ "GenSigStartValue" SG_ 369 RMCU_PhaseCurPeak 125;
BA_ "GenSigStartValue" SG_ 569 RMCU_IGBT_WTemp 50;
BA_ "GenSigStartValue" SG_ 569 RMCU_IGBT_VTemp 50;
BA_ "GenSigStartValue" SG_ 569 RMCU_IGBT_UTemp 50;
BA_ "GenSigStartValue" SG_ 569 RMCU_JunctionIGBT_WTemp 50;
BA_ "GenSigStartValue" SG_ 569 RMCU_JunctionIGBT_VTemp 50;
BA_ "GenSigStartValue" SG_ 569 RMCU_JunctionIGBT_UTemp 50;
BA_ "GenSigStartValue" SG_ 875 RMCU_CoolantTemp 50;
BA_ "InvalidValue" SG_ 875 RMCU_CoolantTemp "FFh";
BA_ "GenSigStartValue" SG_ 875 RMCU_MCUTemp 40;
BA_ "InvalidValue" SG_ 875 RMCU_MCUTemp "FFh";
BA_ "GenSigStartValue" SG_ 875 RMCU_MotorTemp 40;
BA_ "InvalidValue" SG_ 875 RMCU_MotorTemp "FFh";
BA_ "GenSigStartValue" SG_ 875 RMCU_MCUBoardTemp 40;
BA_ "InvalidValue" SG_ 875 RMCU_MCUBoardTemp "FFh";
BA_ "GenSigStartValue" SG_ 875 RMCU_MotorTemp1 40;
BA_ "InvalidValue" SG_ 875 RMCU_MotorTemp1 "FFh";
BA_ "GenSigStartValue" SG_ 875 RMCU_MotorTemp2 40;
BA_ "InvalidValue" SG_ 875 RMCU_MotorTemp2 "FFh";
BA_ "InvalidValue" SG_ 1178 ALIVE_RMCU_WarnMsg "Fh";
BA_ "InvalidValue" SG_ 661 ALIVE_POD_DCFC_Status "Fh";
BA_ "InvalidValue" SG_ 661 POD_DCFC_State_Contactor "Fh";
BA_ "GenSigStartValue" SG_ 661 POD_tempHVBusNeg 30;
BA_ "GenSigStartValue" SG_ 661 POD_tempHVBusPlus 30;
BA_ "InvalidValue" SG_ 662 ALIVE_POD_DCDC_Status "Fh";
BA_ "InvalidValue" SG_ 662 PDU_DCDC_StsCtrl "Fh";
BA_ "SystemSignalLongSymbol" SG_ 664 POD_OBC_evt_Invert_iDCIn_ocflt_s "POD_OBC_evt_Invert_iDCIn_ocflt_sw_trig";
BA_ "SystemSignalLongSymbol" SG_ 664 POD_OBC_evt_Invert_vDCin_uvflt_s "POD_OBC_evt_Invert_vDCin_uvflt_sw_trig";
BA_ "SystemSignalLongSymbol" SG_ 664 POD_OBC_evt_Invert_vDCIn_ovflt_s "POD_OBC_evt_Invert_vDCIn_ovflt_sw_trig";
BA_ "SystemSignalLongSymbol" SG_ 664 POD_OBC_evt_Invert_vACOut_ovflt_ "POD_OBC_evt_Invert_vACOut_ovflt_cmpss_trig";
BA_ "SystemSignalLongSymbol" SG_ 664 POD_OBC_evt_Invert_iACOut_ocflt_ "POD_OBC_evt_Invert_iACOut_ocflt_cmpss_trig";
BA_ "SystemSignalLongSymbol" SG_ 664 POD_OBC_evt_Invert_iACOut_o_0000 "POD_OBC_evt_Invert_iACOut_ocflt_sw_trig";
BA_ "SystemSignalLongSymbol" SG_ 664 POD_OBC_evt_Invert_vACOut_o_0000 "POD_OBC_evt_Invert_vACOut_ovflt_sw_trig";
BA_ "SystemSignalLongSymbol" SG_ 664 POD_OBC_evt_Invert_vACOut_uvflt_ "POD_OBC_evt_Invert_vACOut_uvflt_sw_trig";
BA_ "SystemSignalLongSymbol" SG_ 664 POD_OBC_evt_Invert_iDCIn_ocflt_c "POD_OBC_evt_Invert_iDCIn_ocflt_cmpss_trig";
BA_ "SystemSignalLongSymbol" SG_ 664 POD_OBC_evt_Invert_vDCIn_ovflt_c "POD_OBC_evt_Invert_vDCIn_ovflt_cmpss_trig";
BA_ "SystemSignalLongSymbol" SG_ 664 POD_OBC_evt_Invert_vDClink_uvflt "POD_OBC_evt_Invert_vDClink_uvflt_sw_trig";
BA_ "SystemSignalLongSymbol" SG_ 664 POD_OBC_evt_Invert_vDClink_ovflt "POD_OBC_evt_Invert_vDClink_ovflt_sw_trig";
BA_ "SystemSignalLongSymbol" SG_ 664 POD_OBC_evt_Invert_vDClink__0000 "POD_OBC_evt_Invert_vDClink_ovflt_cmpss_trig";
BA_ "SystemSignalLongSymbol" SG_ 664 POD_OBC_evt_Invert_vACOut_Sensor "POD_OBC_evt_Invert_vACOut_SensorErr";
BA_ "InvalidValue" SG_ 695 ALIVE_POD_OBC_StatusDischage "Fh";
BA_ "InvalidValue" SG_ 787 ALIVE_POD_OBC_StatusCharger1 "Fh";
BA_ "GenSigStartValue" SG_ 787 POD_GTW_statusOBC 7;
BA_ "InvalidValue" SG_ 787 POD_GTW_statusOBC "Fh";
BA_ "InvalidValue" SG_ 803 ALIVE_POD_OBC_StatusCharger2 "Fh";
BA_ "GenSigStartValue" SG_ 803 POD_GW_PhaseACInput 1;
BA_ "GenSigStartValue" SG_ 803 POD_tempACCharger 40;
BA_ "GenSigStartValue" SG_ 803 POD_tempColdplate 40;
BA_ "GenSigStartValue" SG_ 870 PDU_DCDC_Thermal_CpltTemp 40;
BA_ "GenSigStartValue" SG_ 870 PDU_DCDC_Thermal_IntTemp 40;
BA_ "GenSigStartValue" SG_ 870 POD_DCDC_Thermal_NegBBTemp 40;
BA_ "GenSigStartValue" SG_ 870 POD_DCDC_Thermal_PosBBTemp 40;
BA_ "GenSigStartValue" SG_ 870 POD_DCDC_Thermal_reversed0 40;
BA_ "GenSigStartValue" SG_ 870 PDU_DCDC_Thermal_CoolPwrReq 40;
BA_ "GenSigStartValue" SG_ 870 PDU_DCDC_Thermal_FlowRateReq 40;
BA_ "GenSigStartValue" SG_ 870 POD_DCDC_Thermal_PriFetTemp1 40;
BA_ "GenSigStartValue" SG_ 870 POD_DCDC_Thermal_PriFetTemp2 40;
BA_ "GenSigStartValue" SG_ 870 POD_DCDC_Thermal_OutFetTemp 40;
BA_ "GenSigStartValue" SG_ 870 POD_DCDC_Thermal_SecFetTemp 40;
BA_ "SystemSignalLongSymbol" SG_ 1141 POD_DCFC_evt_ChgPort_UnderVolt_S "POD_DCFC_evt_ChgPort_UnderVolt_SW";
BA_ "SystemSignalLongSymbol" SG_ 1141 POD_DCFC_evt_ChgPort_OverVolt_CM "POD_DCFC_evt_ChgPort_OverVolt_CMP";
BA_ "SystemSignalLongSymbol" SG_ 1141 POD_DCFC_evt_ChgPort_UnderVolt_C "POD_DCFC_evt_ChgPort_UnderVolt_CMP";
BA_ "SystemSignalLongSymbol" SG_ 1141 POD_DCFC_evt_ChgPort_RevrsPolari "POD_DCFC_evt_ChgPort_RevrsPolarityFlt";
BA_ "InvalidValue" SG_ 1172 ALIVE_POD_OBC_Err_Level "Fh";
BA_ "InvalidValue" SG_ 1172 POD_OBC_Err_Lvl "7h";
BA_ "GenSigStartValue" SG_ 1864 POD_tempPfcMosfet1 40;
BA_ "GenSigStartValue" SG_ 1864 POD_tempPfcMosfet2 40;
BA_ "GenSigStartValue" SG_ 1864 POD_tempDchvPri 40;
BA_ "GenSigStartValue" SG_ 1864 POD_tempDchvSec 40;
BA_ "SystemSignalLongSymbol" SG_ 1870 POD_OBC_evt_Coolant_Temp_SensorF "POD_OBC_evt_Coolant_Temp_SensorFlt";
BA_ "InvalidValue" SG_ 341 ALIVE_POD_DCDC_Error_Level "Fh";
BA_ "InvalidValue" SG_ 341 POD_DCDC_Err_Lvl "7h";
BA_ "InvalidValue" SG_ 341 POD_DCFC_Err_Lvl "7h";
BA_ "InvalidValue" SG_ 211 RCUO_FualtLevel_enum "7h";
BA_ "InvalidValue" SG_ 211 RCUO_PtAllowPwrMax "1FFh";
BA_ "InvalidValue" SG_ 211 RCUO_PtAllowPwrMin "1FFh";
BA_ "InvalidValue" SG_ 211 RCUO_WorkingSta_enum "1Fh";
BA_ "GenSigStartValue" SG_ 211 RCUO_VehAvgFuleCnsm_Lp100km 7;
BA_ "InvalidValue" SG_ 211 RCUO_VehAvgFuleCnsm_Lp100km "7h";
BA_ "InvalidValue" SG_ 211 RCUO_ErrorCode_enum "FFh";
BA_ "InvalidValue" SG_ 211 RCUO_TolFltNum_enum "FFh";
BA_ "InvalidValue" SG_ 298 RCUO_RCUActOutpPwr_kW "1FFh";
BA_ "InvalidValue" SG_ 298 PCU_FaultSts "1Fh";
BA_ "InvalidValue" SG_ 298 PCU_CVC_ActvDischg_Sts "3h";
BA_ "InvalidValue" SG_ 298 PCU_CVC_GenVoltAct "3FFFh";
BA_ "InvalidValue" SG_ 298 PCU_CVC_GenCurrAct "FFFFh";
BA_ "InvalidValue" SG_ 298 PCU_EngineFuelLvl "3FFh";
BA_ "InvalidValue" SG_ 298 PCU_LowOilAlert "3h";
BA_ "GenSigStartValue" SG_ 298 PCU_FlowRate_Req 40;
BA_ "InvalidValue" SG_ 298 PCU_FlowRate_Req "FFh";
BA_ "InvalidValue" SG_ 298 EMS_ElectricFan_Req "FFh";
BA_ "InvalidValue" SG_ 299 EMS_stMode "7h";
BA_ "InvalidValue" SG_ 299 EMS_EngSpd "FFFFh";
BA_ "InvalidValue" SG_ 299 EMS_EngTq "FFFh";
BA_ "InvalidValue" SG_ 299 EMS_ClntTmp "7FFh";
BA_ "InvalidValue" SG_ 300 GCU_ControlMode "3h";
BA_ "InvalidValue" SG_ 300 GCU_ISGSpd "FFFFh";
BA_ "InvalidValue" SG_ 300 GCU_ISGTq "FFFFh";
BA_ "InvalidValue" SG_ 301 RCU_FuelCutoffRequest "3h";
BA_ "InvalidValue" SG_ 301 RCU_EngTorqueCmd "FFFFh";
BA_ "InvalidValue" SG_ 301 RCU_EnIdleTrgtSpdCmd "FFFFh";
BA_ "InvalidValue" SG_ 302 RCU_GCUEnableReq "3h";
BA_ "InvalidValue" SG_ 302 RCU_GCUControlMode "3h";
BA_ "InvalidValue" SG_ 302 RCU_GCUSpeedCmd "FFFFh";
BA_ "InvalidValue" SG_ 302 RCU_GCUTorqueLimit "FFFFh";
BA_ "InvalidValue" SG_ 378 GCU_ISGTemp "FFh";
BA_ "InvalidValue" SG_ 378 GCU_IGBTATemp "FFh";
BA_ "InvalidValue" SG_ 378 GCU_IGBTBTemp "FFh";
BA_ "InvalidValue" SG_ 378 GCU_IGBTCTemp "FFh";
BA_ "GenSigTimeoutTime_ALL" SG_ 553 CRC_ADCU_COOLING_REQ 500;
BA_ "GenSigTimeoutTime_ALL" SG_ 553 ALIVE_ADCU_COOLING_REQ 500;
BA_ "InvalidValue" SG_ 553 ALIVE_ADCU_COOLING_REQ "Fh";
BA_ "GenSigTimeoutTime_ALL" SG_ 553 ADCU_Cooling_Req 500;
BA_ "InvalidValue" SG_ 553 ADCU_Cooling_Req "3h";
BA_ "GenSigTimeoutTime_ALL" SG_ 553 ADCU_RunState 500;
BA_ "InvalidValue" SG_ 553 ADCU_RunState "7h";
BA_ "GenSigTimeoutTime_ALL" SG_ 1282 CVC_srcNodeID 2000;
BA_ "InvalidValue" SG_ 1282 CVC_srcNodeID "FFh";
BA_ "GenSigTimeoutTime_ALL" SG_ 1282 CVC_CtrlBitVector 2000;
BA_ "GenSigTimeoutTime_ALL" SG_ 1282 CVC_usrData0 2000;
BA_ "GenSigStartValue" SG_ 1282 CVC_usrData0 255;
BA_ "GenSigTimeoutTime_ALL" SG_ 1282 CVC_usrData1 2000;
BA_ "GenSigStartValue" SG_ 1282 CVC_usrData1 255;
BA_ "GenSigTimeoutTime_ALL" SG_ 1282 CVC_usrData2 2000;
BA_ "GenSigStartValue" SG_ 1282 CVC_usrData2 255;
BA_ "GenSigTimeoutTime_ALL" SG_ 1282 CVC_usrData3 2000;
BA_ "GenSigStartValue" SG_ 1282 CVC_usrData3 255;
BA_ "GenSigTimeoutTime_ALL" SG_ 1282 CVC_usrData4 2000;
BA_ "GenSigStartValue" SG_ 1282 CVC_usrData4 255;
BA_ "GenSigTimeoutTime_ALL" SG_ 1282 CVC_usrData5 2000;
BA_ "GenSigStartValue" SG_ 1282 CVC_usrData5 255;
BA_ "GenSigTimeoutTime_ALL" SG_ 1299 BMS_srcNodeID 2000;
BA_ "GenSigStartValue" SG_ 1299 BMS_srcNodeID 19;
BA_ "InvalidValue" SG_ 1299 BMS_srcNodeID "FFh";
BA_ "GenSigTimeoutTime_ALL" SG_ 1299 BMS_CtrlBitVector 2000;
BA_ "GenSigTimeoutTime_ALL" SG_ 1299 BMS_usrData0 2000;
BA_ "GenSigStartValue" SG_ 1299 BMS_usrData0 255;
BA_ "GenSigTimeoutTime_ALL" SG_ 1299 BMS_usrData1 2000;
BA_ "GenSigStartValue" SG_ 1299 BMS_usrData1 255;
BA_ "GenSigTimeoutTime_ALL" SG_ 1299 BMS_usrData2 2000;
BA_ "GenSigStartValue" SG_ 1299 BMS_usrData2 255;
BA_ "GenSigTimeoutTime_ALL" SG_ 1299 BMS_usrData3 2000;
BA_ "GenSigStartValue" SG_ 1299 BMS_usrData3 255;
BA_ "GenSigTimeoutTime_ALL" SG_ 1299 BMS_usrData4 2000;
BA_ "GenSigStartValue" SG_ 1299 BMS_usrData4 255;
BA_ "GenSigTimeoutTime_ALL" SG_ 1299 BMS_usrData5 2000;
BA_ "GenSigStartValue" SG_ 1299 BMS_usrData5 255;
BA_ "GenSigTimeoutTime_ALL" SG_ 1306 RMCU_srcNodeID 2000;
BA_ "GenSigStartValue" SG_ 1306 RMCU_srcNodeID 26;
BA_ "InvalidValue" SG_ 1306 RMCU_srcNodeID "FFh";
BA_ "GenSigTimeoutTime_ALL" SG_ 1306 RMCU_CtrlBitVector 2000;
BA_ "GenSigTimeoutTime_ALL" SG_ 1306 RMCU_usrData0 2000;
BA_ "GenSigStartValue" SG_ 1306 RMCU_usrData0 255;
BA_ "GenSigTimeoutTime_ALL" SG_ 1306 RMCU_usrData1 2000;
BA_ "GenSigStartValue" SG_ 1306 RMCU_usrData1 255;
BA_ "GenSigTimeoutTime_ALL" SG_ 1306 RMCU_usrData2 2000;
BA_ "GenSigStartValue" SG_ 1306 RMCU_usrData2 255;
BA_ "GenSigTimeoutTime_ALL" SG_ 1306 RMCU_usrData3 2000;
BA_ "GenSigStartValue" SG_ 1306 RMCU_usrData3 255;
BA_ "GenSigTimeoutTime_ALL" SG_ 1306 RMCU_usrData4 2000;
BA_ "GenSigStartValue" SG_ 1306 RMCU_usrData4 255;
BA_ "GenSigTimeoutTime_ALL" SG_ 1306 RMCU_usrData5 2000;
BA_ "GenSigStartValue" SG_ 1306 RMCU_usrData5 255;
BA_ "GenSigTimeoutTime_ALL" SG_ 1307 FMCU_srcNodeID 2000;
BA_ "GenSigStartValue" SG_ 1307 FMCU_srcNodeID 27;
BA_ "InvalidValue" SG_ 1307 FMCU_srcNodeID "FFh";
BA_ "GenSigTimeoutTime_ALL" SG_ 1307 FMCU_CtrlBitVector 2000;
BA_ "GenSigTimeoutTime_ALL" SG_ 1307 FMCU_usrData0 2000;
BA_ "GenSigStartValue" SG_ 1307 FMCU_usrData0 255;
BA_ "GenSigTimeoutTime_ALL" SG_ 1307 FMCU_usrData1 2000;
BA_ "GenSigStartValue" SG_ 1307 FMCU_usrData1 255;
BA_ "GenSigTimeoutTime_ALL" SG_ 1307 FMCU_usrData2 2000;
BA_ "GenSigStartValue" SG_ 1307 FMCU_usrData2 255;
BA_ "GenSigTimeoutTime_ALL" SG_ 1307 FMCU_usrData3 2000;
BA_ "GenSigStartValue" SG_ 1307 FMCU_usrData3 255;
BA_ "GenSigTimeoutTime_ALL" SG_ 1307 FMCU_usrData4 2000;
BA_ "GenSigStartValue" SG_ 1307 FMCU_usrData4 255;
BA_ "GenSigTimeoutTime_ALL" SG_ 1307 FMCU_usrData5 2000;
BA_ "GenSigStartValue" SG_ 1307 FMCU_usrData5 255;
BA_ "GenSigTimeoutTime_ALL" SG_ 1311 EVCC_srcNodeID 2000;
BA_ "GenSigStartValue" SG_ 1311 EVCC_srcNodeID 31;
BA_ "InvalidValue" SG_ 1311 EVCC_srcNodeID "FFh";
BA_ "GenSigTimeoutTime_ALL" SG_ 1311 EVCC_CtrlBitVector 2000;
BA_ "GenSigTimeoutTime_ALL" SG_ 1311 EVCC_usrData0 2000;
BA_ "GenSigStartValue" SG_ 1311 EVCC_usrData0 255;
BA_ "GenSigTimeoutTime_ALL" SG_ 1311 EVCC_usrData1 2000;
BA_ "GenSigStartValue" SG_ 1311 EVCC_usrData1 255;
BA_ "GenSigTimeoutTime_ALL" SG_ 1311 EVCC_usrData2 2000;
BA_ "GenSigStartValue" SG_ 1311 EVCC_usrData2 255;
BA_ "GenSigTimeoutTime_ALL" SG_ 1311 EVCC_usrData3 2000;
BA_ "GenSigStartValue" SG_ 1311 EVCC_usrData3 255;
BA_ "GenSigTimeoutTime_ALL" SG_ 1311 EVCC_usrData4 2000;
BA_ "GenSigStartValue" SG_ 1311 EVCC_usrData4 255;
BA_ "GenSigTimeoutTime_ALL" SG_ 1311 EVCC_usrData5 2000;
BA_ "GenSigStartValue" SG_ 1311 EVCC_usrData5 255;
BA_ "GenSigTimeoutTime_ALL" SG_ 1336 PCU_srcNodeID 2000;
BA_ "InvalidValue" SG_ 1336 PCU_srcNodeID "FFh";
BA_ "GenSigTimeoutTime_ALL" SG_ 1336 PCU_CtrlBitVector 2000;
BA_ "GenSigTimeoutTime_ALL" SG_ 1336 PCU_usrData0 2000;
BA_ "GenSigStartValue" SG_ 1336 PCU_usrData0 255;
BA_ "GenSigTimeoutTime_ALL" SG_ 1336 PCU_usrData1 2000;
BA_ "GenSigStartValue" SG_ 1336 PCU_usrData1 255;
BA_ "GenSigTimeoutTime_ALL" SG_ 1336 PCU_usrData2 2000;
BA_ "GenSigStartValue" SG_ 1336 PCU_usrData2 255;
BA_ "GenSigTimeoutTime_ALL" SG_ 1336 PCU_usrData3 2000;
BA_ "GenSigStartValue" SG_ 1336 PCU_usrData3 255;
BA_ "GenSigTimeoutTime_ALL" SG_ 1336 PCU_usrData4 2000;
BA_ "GenSigStartValue" SG_ 1336 PCU_usrData4 255;
BA_ "GenSigTimeoutTime_ALL" SG_ 1336 PCU_usrData5 2000;
BA_ "GenSigStartValue" SG_ 1336 PCU_usrData5 255;
BA_ "GenSigTimeoutTime_ALL" SG_ 1341 POD_srcNodeID 2000;
BA_ "GenSigStartValue" SG_ 1341 POD_srcNodeID 61;
BA_ "InvalidValue" SG_ 1341 POD_srcNodeID "FFh";
BA_ "GenSigTimeoutTime_ALL" SG_ 1341 POD_CtrlBitVector 2000;
BA_ "GenSigTimeoutTime_ALL" SG_ 1341 POD_usrData0 2000;
BA_ "GenSigStartValue" SG_ 1341 POD_usrData0 255;
BA_ "GenSigTimeoutTime_ALL" SG_ 1341 POD_usrData1 2000;
BA_ "GenSigStartValue" SG_ 1341 POD_usrData1 255;
BA_ "GenSigTimeoutTime_ALL" SG_ 1341 POD_usrData2 2000;
BA_ "GenSigStartValue" SG_ 1341 POD_usrData2 255;
BA_ "GenSigTimeoutTime_ALL" SG_ 1341 POD_usrData3 2000;
BA_ "GenSigStartValue" SG_ 1341 POD_usrData3 255;
BA_ "GenSigTimeoutTime_ALL" SG_ 1341 POD_usrData4 2000;
BA_ "GenSigStartValue" SG_ 1341 POD_usrData4 255;
BA_ "GenSigTimeoutTime_ALL" SG_ 1341 POD_usrData5 2000;
BA_ "GenSigStartValue" SG_ 1341 POD_usrData5 255;
BA_ "GenSigSendType" SG_ 1683 BMS_DiagReqData0 1;
BA_ "GenSigSendType" SG_ 1683 BMS_DiagReqData1 1;
BA_ "GenSigSendType" SG_ 1683 BMS_DiagReqData2 1;
BA_ "GenSigSendType" SG_ 1683 BMS_DiagReqData3 1;
BA_ "GenSigSendType" SG_ 1683 BMS_DiagReqData4 1;
BA_ "GenSigSendType" SG_ 1683 BMS_DiagReqData5 1;
BA_ "GenSigSendType" SG_ 1683 BMS_DiagReqData6 1;
BA_ "GenSigSendType" SG_ 1683 BMS_DiagReqData7 1;
BA_ "GenSigSendType" SG_ 1683 BMS_DiagReqData8 1;
BA_ "GenSigSendType" SG_ 1683 BMS_DiagReqData9 1;
BA_ "GenSigSendType" SG_ 1683 BMS_DiagReqData10 1;
BA_ "GenSigSendType" SG_ 1683 BMS_DiagReqData11 1;
BA_ "GenSigSendType" SG_ 1683 BMS_DiagReqData12 1;
BA_ "GenSigSendType" SG_ 1683 BMS_DiagReqData13 1;
BA_ "GenSigSendType" SG_ 1683 BMS_DiagReqData14 1;
BA_ "GenSigSendType" SG_ 1683 BMS_DiagReqData15 1;
BA_ "GenSigSendType" SG_ 1683 BMS_DiagReqData16 1;
BA_ "GenSigSendType" SG_ 1683 BMS_DiagReqData17 1;
BA_ "GenSigSendType" SG_ 1683 BMS_DiagReqData18 1;
BA_ "GenSigSendType" SG_ 1683 BMS_DiagReqData19 1;
BA_ "GenSigSendType" SG_ 1683 BMS_DiagReqData20 1;
BA_ "GenSigSendType" SG_ 1683 BMS_DiagReqData21 1;
BA_ "GenSigSendType" SG_ 1683 BMS_DiagReqData22 1;
BA_ "GenSigSendType" SG_ 1683 BMS_DiagReqData23 1;
BA_ "GenSigSendType" SG_ 1683 BMS_DiagReqData24 1;
BA_ "GenSigSendType" SG_ 1683 BMS_DiagReqData25 1;
BA_ "GenSigSendType" SG_ 1683 BMS_DiagReqData26 1;
BA_ "GenSigSendType" SG_ 1683 BMS_DiagReqData27 1;
BA_ "GenSigSendType" SG_ 1683 BMS_DiagReqData28 1;
BA_ "GenSigSendType" SG_ 1683 BMS_DiagReqData29 1;
BA_ "GenSigSendType" SG_ 1683 BMS_DiagReqData30 1;
BA_ "GenSigSendType" SG_ 1683 BMS_DiagReqData31 1;
BA_ "GenSigSendType" SG_ 1683 BMS_DiagReqData32 1;
BA_ "GenSigSendType" SG_ 1683 BMS_DiagReqData33 1;
BA_ "GenSigSendType" SG_ 1683 BMS_DiagReqData34 1;
BA_ "GenSigSendType" SG_ 1683 BMS_DiagReqData35 1;
BA_ "GenSigSendType" SG_ 1683 BMS_DiagReqData36 1;
BA_ "GenSigSendType" SG_ 1683 BMS_DiagReqData37 1;
BA_ "GenSigSendType" SG_ 1683 BMS_DiagReqData38 1;
BA_ "GenSigSendType" SG_ 1683 BMS_DiagReqData39 1;
BA_ "GenSigSendType" SG_ 1683 BMS_DiagReqData40 1;
BA_ "GenSigSendType" SG_ 1683 BMS_DiagReqData41 1;
BA_ "GenSigSendType" SG_ 1683 BMS_DiagReqData42 1;
BA_ "GenSigSendType" SG_ 1683 BMS_DiagReqData43 1;
BA_ "GenSigSendType" SG_ 1683 BMS_DiagReqData44 1;
BA_ "GenSigSendType" SG_ 1683 BMS_DiagReqData45 1;
BA_ "GenSigSendType" SG_ 1683 BMS_DiagReqData46 1;
BA_ "GenSigSendType" SG_ 1683 BMS_DiagReqData47 1;
BA_ "GenSigSendType" SG_ 1683 BMS_DiagReqData48 1;
BA_ "GenSigSendType" SG_ 1683 BMS_DiagReqData49 1;
BA_ "GenSigSendType" SG_ 1683 BMS_DiagReqData50 1;
BA_ "GenSigSendType" SG_ 1683 BMS_DiagReqData51 1;
BA_ "GenSigSendType" SG_ 1683 BMS_DiagReqData52 1;
BA_ "GenSigSendType" SG_ 1683 BMS_DiagReqData53 1;
BA_ "GenSigSendType" SG_ 1683 BMS_DiagReqData54 1;
BA_ "GenSigSendType" SG_ 1683 BMS_DiagReqData55 1;
BA_ "GenSigSendType" SG_ 1683 BMS_DiagReqData56 1;
BA_ "GenSigSendType" SG_ 1683 BMS_DiagReqData57 1;
BA_ "GenSigSendType" SG_ 1683 BMS_DiagReqData58 1;
BA_ "GenSigSendType" SG_ 1683 BMS_DiagReqData59 1;
BA_ "GenSigSendType" SG_ 1683 BMS_DiagReqData60 1;
BA_ "GenSigSendType" SG_ 1683 BMS_DiagReqData61 1;
BA_ "GenSigSendType" SG_ 1683 BMS_DiagReqData62 1;
BA_ "GenSigSendType" SG_ 1683 BMS_DiagReqData63 1;
VAL_ 201 FMCU_StsMCUFault 0 "No Fault" 1 "Fault level 1" 2 "Fault level 2" 3 "Fault level 3" 4 "Fault level 4" 5 "Fault level 5" 6 "Fault level 6" ;
VAL_ 201 FMCU_MotorSpdSts 0 "Valid" 1 "Invalid" ;
VAL_ 201 FMCU_MotorTqSts 0 "Valid" 1 "Invalid" ;
VAL_ 201 FMCU_CVC_CtrlMode 0 "Inactive" 1 "Torque control mode" 2 "Speed Control mode" 3 "Limphome" 4 "crawling" ;
VAL_ 201 FMCU_CVC_StsMode 0 "Init" 1 "LvStandby(12V)" 5 "Standby" 6 "Torq" 7 "Speed" 9 "ActiveDischarge" 10 "Fault" 11 "PowerOff" 12 "AfterRun" ;
VAL_ 202 FMCU_ActInputVoltV 0 "Valid" 1 "Invalid" ;
VAL_ 202 FMCU_ActInputCurrentV 0 "Valid" 1 "Invalid" ;
VAL_ 368 FMCU_PowerReduceSts 0 "Not Reduced" 1 "Reduced" ;
VAL_ 368 FMCU_DragSts 0 "Normally drive" 1 "MCU fault and can be dragged" 2 "MCU fault and can not be dragged" ;
VAL_ 368 FMCU_HighVoltPowerOffReq 0 "No Request" 1 "Request" ;
VAL_ 568 FMCU_KL15 0 "invalid" 1 "valid" ;
VAL_ 568 FMCU_SSUState 0 "INT" 1 "PWM" 2 "FW" 3 "LA" 4 "HA" 5 "ER" 6 "CR" ;
VAL_ 568 FMCU_DampingState 0 "Damping disable" 1 "Damping active" ;
VAL_ 568 FMCU_IGBTState 0 "shutdown" 1 "Entering ASC from the upper bridge arm" 2 "Enter ASC from the lower bridge arm" 3 "normal work" ;
VAL_ 568 FMCU_ASRSts 0 "Inactive" 1 "Active" ;
VAL_ 872 FMCU_PhaseOverCurrentSWFault 0 "Normal" 1 "Error" ;
VAL_ 872 FMCU_MCUOverTempFault 0 "Normal" 1 "Error" ;
VAL_ 872 FMCU_MCUOverTempAlarm 0 "Normal" 1 "Error" ;
VAL_ 872 FMCU_MotOverTemp2Fault 0 "Normal" 1 "Error" ;
VAL_ 872 FMCU_MotTempSenFault 0 "Normal" 1 "Error" ;
VAL_ 872 FMCU_MotOverTemp1Fault 0 "Normal" 1 "Error" ;
VAL_ 872 FMCU_MotOverTempAlarm 0 "Normal" 1 "Error" ;
VAL_ 872 FMCU_MCUHVUnderVoltageFault 0 "Normal" 1 "Error" ;
VAL_ 872 FMCU_MCUHVUnderVoltageAlarm 0 "Normal" 1 "Error" ;
VAL_ 872 FMCU_MCUHVOverVoltageFault 0 "Normal" 1 "Error" ;
VAL_ 872 FMCU_MCUHVOverVoltageAlarm 0 "Normal" 1 "Error" ;
VAL_ 872 FMCU_MCUCurrentSenWFault 0 "Normal" 1 "Error" ;
VAL_ 872 FMCU_MCUCurrentSenVFault 0 "Normal" 1 "Error" ;
VAL_ 872 FMCU_MCUCurrentSenUFault 0 "Normal" 1 "Error" ;
VAL_ 872 FMCU_PhaseOverCurrentHWFault 0 "Normal" 1 "Error" ;
VAL_ 872 FMCU_MotOverFault 0 "Normal" 1 "Error" ;
VAL_ 872 FMCU_MotOverAlarm 0 "Normal" 1 "Error" ;
VAL_ 872 FMCU_12VUnderVoltageAlarm 0 "Normal" 1 "Error" ;
VAL_ 872 FMCU_12VOverVoltageAlarm 0 "Normal" 1 "Error" ;
VAL_ 872 FMCU_MCUHVSensorFault 0 "Normal" 1 "Error" ;
VAL_ 872 FMCU_MCUDisChgFault 0 "Normal" 1 "Error" ;
VAL_ 872 FMCU_MotBlockedFault 0 "Normal" 1 "Error" ;
VAL_ 872 FMCU_MotRotSenFault 0 "Normal" 1 "Error" ;
VAL_ 872 FMCU_BMSLostFault 0 "Normal" 1 "Error" ;
VAL_ 872 FMCU_CVCLostFault 0 "Normal" 1 "Error" ;
VAL_ 872 FMCU_CANBusoffFault 0 "Normal" 1 "Error" ;
VAL_ 872 FMCU_IGBTFault 0 "Normal" 1 "Error" ;
VAL_ 872 FMCU_MCUCurrentSenWZeroFault 0 "Normal" 1 "Error" ;
VAL_ 872 FMCU_MCUCurrentSenVZeroFault 0 "Normal" 1 "Error" ;
VAL_ 872 FMCU_MCUCurrentSenUZeroFault 0 "Normal" 1 "Error" ;
VAL_ 872 FMCU_MCUTempSenWFault 0 "Normal" 1 "Error" ;
VAL_ 872 FMCU_MCUTempSenVFault 0 "Normal" 1 "Error" ;
VAL_ 872 FMCU_MCUTempSenUFault 0 "Normal" 1 "Error" ;
VAL_ 872 FMCU_InitMode 0 "Normal" 1 "Error" ;
VAL_ 873 FMCU_StsActiveDischg 0 "No Active Discharge" 1 "Active Discharge" 2 "Failed Active Discharge" 3 "Finished Active Discharge" ;
VAL_ 873 FMCU_TBOX_ModeMotorDrv 1 "DispateEnergy" 2 "GenerateEnergy" 3 "Shutdown" 4 "Ready" 5 "Reserved" ;
VAL_ 1080 FMCU_HV_Fault_Sts 0 "Normal" 1 "Error" ;
VAL_ 1080 FMCU_Idc_Fault_Sts 0 "Normal" 1 "Error" ;
VAL_ 1080 FMCU_Mode_Fault_Sts 0 "Normal" 1 "Error" ;
VAL_ 1080 FMCU_MotDiag_Fault_Sts 0 "Normal" 1 "Error" ;
VAL_ 1080 FMCU_LVSup_Fault_Sts 0 "Normal" 1 "Error" ;
VAL_ 1080 FMCU_DrvModu_Fault_Sts 0 "Normal" 1 "Error" ;
VAL_ 1083 FMCU_Mem_Fault_Sts 0 "Normal" 1 "Error" ;
VAL_ 1083 FMCU_CS_Fault_Sts 0 "Normal" 1 "Error" ;
VAL_ 1083 FMCU_CANCom_Fault_Sts 0 "Normal" 1 "Error" ;
VAL_ 1083 FMCU_SSU_Fault_Sts 0 "Normal" 1 "Error" ;
VAL_ 1083 FMCU_Spd_Fault_Sts 0 "Normal" 1 "Error" ;
VAL_ 1083 FMCU_PwrModu_Fault_Sts 0 "Normal" 1 "Error" ;
VAL_ 1083 FMCU_PhaCur_Fault_Sts 0 "Normal" 1 "Error" ;
VAL_ 1085 FMCU_TrqCtl_Fault_Sts 0 "Normal" 1 "Error" ;
VAL_ 1085 FMCU_Thermal_Fault_Sts 0 "Normal" 1 "Error" ;
VAL_ 1085 FMCU_PosSen_Fault_Sts 0 "Normal" 1 "Error" ;
VAL_ 1085 FMCU_IOHW_Fault_Sts 0 "Normal" 1 "Error" ;
VAL_ 1087 FMCU_FS_SOPMonFault 0 "Normal" 1 "Error" ;
VAL_ 1087 FMCU_FS_MCUMonFault 0 "Normal" 1 "Error" ;
VAL_ 1087 FMCU_FS_SBCMonFault 0 "Normal" 1 "Error" ;
VAL_ 1087 FMCU_FS_TempMonFault 0 "Normal" 1 "Error" ;
VAL_ 1087 FMCU_FS_SpdMonFault 0 "Normal" 1 "Error" ;
VAL_ 1087 FMCU_FS_PhaCurMonFault 0 "Normal" 1 "Error" ;
VAL_ 1087 FMCU_FS_TrqMonFault 0 "Normal" 1 "Error" ;
VAL_ 1087 FMCU_FS_LVMonFault 0 "Normal" 1 "Error" ;
VAL_ 1087 FMCU_FS_HVFault 0 "Normal" 1 "Error" ;
VAL_ 1179 FMCU_Warning_Flag_1 0 "No Error" 1 "Error" ;
VAL_ 1179 FMCU_Warning_Flag_2 0 "No Error" 1 "Error" ;
VAL_ 1179 FMCU_Warning_Flag_3 0 "No Error" 1 "Error" ;
VAL_ 1179 FMCU_Warning_Flag_4 0 "No Error" 1 "Error" ;
VAL_ 1179 FMCU_Warning_Flag_5 0 "No Error" 1 "Error" ;
VAL_ 1179 FMCU_Warning_Flag_6 0 "No Error" 1 "Error" ;
VAL_ 1179 FMCU_Warning_Flag_7 0 "No Error" 1 "Error" ;
VAL_ 1179 FMCU_Warning_Flag_8 0 "No Error" 1 "Error" ;
VAL_ 1179 FMCU_Warning_Flag_9 0 "No Error" 1 "Error" ;
VAL_ 1179 FMCU_Warning_Flag_10 0 "No Error" 1 "Error" ;
VAL_ 1179 FMCU_Warning_Flag_11 0 "No Error" 1 "Error" ;
VAL_ 1179 FMCU_Warning_Flag_12 0 "No Error" 1 "Error" ;
VAL_ 203 RMCU_StsMCUFault 0 "No Fault" 1 "Fault level 1" 2 "Fault level 2" 3 "Fault level 3" 4 "Fault level 4" 5 "Fault level 5" 6 "Fault level 6" ;
VAL_ 203 RMCU_MotorSpdValid 0 "Valid" 1 "Invalid" ;
VAL_ 203 RMCU_MotorTqValid 0 "Valid" 1 "Invalid" ;
VAL_ 203 RMCU_CVC_CtrlMode 0 "Inactive" 1 "Torque control mode" 2 "Speed Control mode" 3 "Limphome" 4 "crawling" ;
VAL_ 203 RMCU_CVC_StsMode 0 "Init" 1 "LvStandby(12V)" 5 "Standby" 6 "Torq" 7 "Speed" 9 "ActiveDischarge" 10 "Fault" 11 "PowerOff" 12 "AfterRun" ;
VAL_ 204 RMCU_ActInputVoltV 0 "Valid" 1 "Invalid" ;
VAL_ 204 RMCU_ActInputCurrentV 0 "Valid" 1 "Invalid" ;
VAL_ 369 RMCU_PowerReduceSts 0 "Not Reduced" 1 "Reduced" ;
VAL_ 369 RMCU_DragSts 0 "Normally drive" 1 "MCU fault and can be dragged" 2 "MCU fault and can not be dragged" ;
VAL_ 369 RMCU_HighVoltPowerOffReq 0 "No Request" 1 "Request" ;
VAL_ 569 RMCU_KL15 0 "invalid" 1 "valid" ;
VAL_ 569 RMCU_SSUState 0 "INT" 1 "PWM" 2 "FW" 3 "LA" 4 "HA" 5 "ER" 6 "CR" ;
VAL_ 569 RMCU_DampingState 0 "Damping disable" 1 "Damping active" ;
VAL_ 569 RMCU_IGBTState 0 "shutdown" 1 "Entering ASC from the upper bridge arm" 2 "Enter ASC from the lower bridge arm" 3 "normal work" ;
VAL_ 569 RMCU_ASRSts 0 "Inactive" 1 "Active" ;
VAL_ 874 RMCU_PhaseOverCurrentSWFault 0 "Normal" 1 "Error" ;
VAL_ 874 RMCU_MCUOverTempFault 0 "Normal" 1 "Error" ;
VAL_ 874 RMCU_MCUOverTempAlarm 0 "Normal" 1 "Error" ;
VAL_ 874 RMCU_MotOverTemp2Fault 0 "Normal" 1 "Error" ;
VAL_ 874 RMCU_MotTempSenFault 0 "Normal" 1 "Error" ;
VAL_ 874 RMCU_MotOverTemp1Fault 0 "Normal" 1 "Error" ;
VAL_ 874 RMCU_MotOverTempAlarm 0 "Normal" 1 "Error" ;
VAL_ 874 RMCU_MCUHVUnderVoltageFault 0 "Normal" 1 "Error" ;
VAL_ 874 RMCU_MCUHVUnderVoltageAlarm 0 "Normal" 1 "Error" ;
VAL_ 874 RMCU_MCUHVOverVoltageFault 0 "Normal" 1 "Error" ;
VAL_ 874 RMCU_MCUHVOverVoltageAlarm 0 "Normal" 1 "Error" ;
VAL_ 874 RMCU_MCUCurrentSenWFault 0 "Normal" 1 "Error" ;
VAL_ 874 RMCU_MCUCurrentSenVFault 0 "Normal" 1 "Error" ;
VAL_ 874 RMCU_MCUCurrentSenUFault 0 "Normal" 1 "Error" ;
VAL_ 874 RMCU_PhaseOverCurrentHWFault 0 "Normal" 1 "Error" ;
VAL_ 874 RMCU_MotOverFault 0 "Normal" 1 "Error" ;
VAL_ 874 RMCU_MotOverAlarm 0 "Normal" 1 "Error" ;
VAL_ 874 RMCU_12VUnderVoltageAlarm 0 "Normal" 1 "Error" ;
VAL_ 874 RMCU_12VOverVoltageAlarm 0 "Normal" 1 "Error" ;
VAL_ 874 RMCU_MCUHVSensorFault 0 "Normal" 1 "Error" ;
VAL_ 874 RMCU_MCUDisChgFault 0 "Normal" 1 "Error" ;
VAL_ 874 RMCU_MotBlockedFault 0 "Normal" 1 "Error" ;
VAL_ 874 RMCU_MotRotSenFault 0 "Normal" 1 "Error" ;
VAL_ 874 RMCU_BMSLostFault 0 "Normal" 1 "Error" ;
VAL_ 874 RMCU_CVCLostFault 0 "Normal" 1 "Error" ;
VAL_ 874 RMCU_CANBusoffFault 0 "Normal" 1 "Error" ;
VAL_ 874 RMCU_IGBTFault 0 "Normal" 1 "Error" ;
VAL_ 874 RMCU_MCUCurrentSenWZeroFault 0 "Normal" 1 "Error" ;
VAL_ 874 RMCU_MCUCurrentSenVZeroFault 0 "Normal" 1 "Error" ;
VAL_ 874 RMCU_MCUCurrentSenUZeroFault 0 "Normal" 1 "Error" ;
VAL_ 874 RMCU_MCUTempSenWFault 0 "Normal" 1 "Error" ;
VAL_ 874 RMCU_MCUTempSenVFault 0 "Normal" 1 "Error" ;
VAL_ 874 RMCU_MCUTempSenUFault 0 "Normal" 1 "Error" ;
VAL_ 874 RMCU_InitMode 0 "Normal" 1 "Error" ;
VAL_ 875 RMCU_StsActiveDischg 0 "No Active Discharge" 1 "Active Discharge" 2 "Failed Active Discharge" 3 "Finished Active Discharge" ;
VAL_ 875 RMCU_TBOX_ModeMotorDrv 1 "DispateEnergy" 2 "GenerateEnergy" 3 "Shutdown" 4 "Ready" 5 "Reserved" ;
VAL_ 1081 RMCU_HV_Fault_Sts 0 "Normal" 1 "Error" ;
VAL_ 1081 RMCU_Idc_Fault_Sts 0 "Normal" 1 "Error" ;
VAL_ 1081 RMCU_Mode_Fault_Sts 0 "Normal" 1 "Error" ;
VAL_ 1081 RMCU_MotDiag_Fault_Sts 0 "Normal" 1 "Error" ;
VAL_ 1081 RMCU_LVSup_Fault_Sts 0 "Normal" 1 "Error" ;
VAL_ 1081 RMCU_DrvModu_Fault_Sts 0 "Normal" 1 "Error" ;
VAL_ 1082 RMCU_Mem_Fault_Sts 0 "Normal" 1 "Error" ;
VAL_ 1082 RMCU_CS_Fault_Sts 0 "Normal" 1 "Error" ;
VAL_ 1082 RMCU_CANCom_Fault_Sts 0 "Normal" 1 "Error" ;
VAL_ 1082 RMCU_SSU_Fault_Sts 0 "Normal" 1 "Error" ;
VAL_ 1082 RMCU_Spd_Fault_Sts 0 "Normal" 1 "Error" ;
VAL_ 1082 RMCU_PwrModu_Fault_Sts 0 "Normal" 1 "Error" ;
VAL_ 1082 RMCU_PhaCur_Fault_Sts 0 "Normal" 1 "Error" ;
VAL_ 1084 RMCU_TrqCtl_Fault_Sts 0 "Normal" 1 "Error" ;
VAL_ 1084 RMCU_Thermal_Fault_Sts 0 "Normal" 1 "Error" ;
VAL_ 1084 RMCU_PosSen_Fault_Sts 0 "Normal" 1 "Error" ;
VAL_ 1084 RMCU_IOHW_Fault_Sts 0 "Normal" 1 "Error" ;
VAL_ 1091 RMCU_FS_SOPMonFault 0 "Normal" 1 "Error" ;
VAL_ 1091 RMCU_FS_MCUMonFault 0 "Normal" 1 "Error" ;
VAL_ 1091 RMCU_FS_SBCMonFault 0 "Normal" 1 "Error" ;
VAL_ 1091 RMCU_FS_TempMonFault 0 "Normal" 1 "Error" ;
VAL_ 1091 RMCU_FS_SpdMonFault 0 "Normal" 1 "Error" ;
VAL_ 1091 RMCU_FS_PhaCurMonFault 0 "Normal" 1 "Error" ;
VAL_ 1091 RMCU_FS_TrqMonFault 0 "Normal" 1 "Error" ;
VAL_ 1091 RMCU_FS_LVMonFault 0 "Normal" 1 "Error" ;
VAL_ 1091 RMCU_FS_HVFault 0 "Normal" 1 "Error" ;
VAL_ 1178 RMCU_Warning_Flag_1 0 "No Error" 1 "Error" ;
VAL_ 1178 RMCU_Warning_Flag_2 0 "No Error" 1 "Error" ;
VAL_ 1178 RMCU_Warning_Flag_3 0 "No Error" 1 "Error" ;
VAL_ 1178 RMCU_Warning_Flag_4 0 "No Error" 1 "Error" ;
VAL_ 1178 RMCU_Warning_Flag_5 0 "No Error" 1 "Error" ;
VAL_ 1178 RMCU_Warning_Flag_6 0 "No Error" 1 "Error" ;
VAL_ 1178 RMCU_Warning_Flag_7 0 "No Error" 1 "Error" ;
VAL_ 1178 RMCU_Warning_Flag_8 0 "No Error" 1 "Error" ;
VAL_ 1178 RMCU_Warning_Flag_9 0 "No Error" 1 "Error" ;
VAL_ 1178 RMCU_Warning_Flag_10 0 "No Error" 1 "Error" ;
VAL_ 1178 RMCU_Warning_Flag_11 0 "No Error" 1 "Error" ;
VAL_ 1178 RMCU_Warning_Flag_12 0 "No Error" 1 "Error" ;
VAL_ 661 POD_DCFC_State_Contactor 0 "DCFC_CONTACTORS_OPEN" 1 "DCFC_CONTACTORS_CLOSING" 2 "DCFC_CONTACTRORS_CLOSED" 3 "DCFC_CONTACTORS_OPENING" 4 "DCFC_CONTACTORS_WELDED" 7 "DCFC_SNA" ;
VAL_ 662 PDU_DCDC_StsCtrl 0 "DCDC_OFF" 1 "DCDC_STANDBY" 2 "DCDC_ON" 3 "DCDC_RESERVED" 4 "DCDC_DEGRAEDED" 5 "DCDC_FAULT_SHUTDOWN" 6 "DCDC_EMEGENCY_SHUTDOWN" 7 "DCDC_SNA" ;
VAL_ 664 POD_OBC_evt_Invert_iDCIn_ocflt_s 0 "Normal" 1 "Error" ;
VAL_ 664 POD_OBC_evt_Invert_vDCin_uvflt_s 0 "Normal" 1 "Error" ;
VAL_ 664 POD_OBC_evt_Invert_vDCIn_ovflt_s 0 "Normal" 1 "Error" ;
VAL_ 664 POD_OBC_evt_Invert_vACOut_ovflt_ 0 "Normal" 1 "Error" ;
VAL_ 664 POD_OBC_evt_Invert_iACOut_ocflt_ 0 "Normal" 1 "Error" ;
VAL_ 664 POD_OBC_evt_Invert_iACOut_o_0000 0 "Normal" 1 "Error" ;
VAL_ 664 POD_OBC_evt_Invert_vACOut_o_0000 0 "Normal" 1 "Error" ;
VAL_ 664 POD_OBC_evt_Invert_vACOut_uvflt_ 0 "Normal" 1 "Error" ;
VAL_ 664 POD_OBC_evt_Invert_iDCIn_ocflt_c 0 "Normal" 1 "Error" ;
VAL_ 664 POD_OBC_evt_Invert_vDCIn_ovflt_c 0 "Normal" 1 "Error" ;
VAL_ 664 POD_OBC_evt_Invert_vDClink_uvflt 0 "Normal" 1 "Error" ;
VAL_ 664 POD_OBC_evt_Invert_vDClink_ovflt 0 "Normal" 1 "Error" ;
VAL_ 664 POD_OBC_evt_Invert_vDClink__0000 0 "Normal" 1 "Error" ;
VAL_ 664 POD_OBC_evt_Invert_vACOut_Sensor 0 "Normal" 1 "Error" ;
VAL_ 664 POD_OBC_Inv_iACOut_ImBalFlt 0 "Normal" 1 "Error" ;
VAL_ 664 POD_OBC_Inv_iACOut_ImBalWrn 0 "Normal" 1 "Error" ;
VAL_ 664 POD_OBC_Inv_FET_OverTempFlt 0 "Normal" 1 "Error" ;
VAL_ 664 POD_OBC_Inv_FET_TempWrn 0 "Normal" 1 "Error" ;
VAL_ 664 POD_OBC_Inv_FET_UnderTempFlt 0 "Normal" 1 "Error" ;
VAL_ 664 POD_OBC_Inv_Coolant_OverTempFlt 0 "Normal" 1 "Error" ;
VAL_ 664 POD_OBC_Inv_Coolant_TempWrn 0 "Normal" 1 "Error" ;
VAL_ 664 POD_OBC_Inv_Coolant_UnderTempFlt 0 "Normal" 1 "Error" ;
VAL_ 787 POD_GTW_statusOBC 0 "OBC_OFF" 1 "OBC_STANDBY" 2 "OBC_ON_NORMAL" 3 "OBC_ON_VOLTAGE" 4 "OBC_DEGRADED_ON_NORMAL" 5 "OBC_FAULT_SHUTDOWN" 6 "OBC_EMERGENCY_SHUTDOWN" 7 "OBC_DEGRADED_ON_VOLTAGE" 8 "OBC_ON_V2L" 9 "OBC_DEGRADED_ON_V2L" 10 "OBC_STS_SNA" ;
VAL_ 803 POD_GW_PhaseACInput 1 "AC 1 phase input" 3 "AC 3 phase input" ;
VAL_ 1172 POD_OBC_Err_Lvl 0 "No Fault" 1 "Level1-slight fault" 2 "Level2-Minor fault" 3 "Level3-General fault" 4 "Level4-Serious fault" 5 "Level5-Fatal fault" ;
VAL_ 341 POD_DCDC_Err_Lvl 0 "No Fault" 1 "Level1-slight fault" 2 "Level2-Minor fault" 3 "Level3-General fault" 4 "Level4-Serious fault" 5 "Level5-Fatal fault" ;
VAL_ 341 POD_DCFC_Err_Lvl 0 "No fault" 1 "Level1-Minor fault" 2 "Level2-Serious fault" 3 "Level3-Fatal fault" ;
VAL_ 211 RCUO_FualtLevel_enum 0 "No fault" 1 "Level 1 malfunction" 2 "Level 2 malfunction" 3 "Level 3 malfunction" 4 "Level 4 malfunction" 5 "Level 5 malfunction" ;
VAL_ 211 RCUO_WorkingSta_enum 0 "OFF" 1 "RCU_LVStandby" 2 "RCU_HVStandby" 3 "reserved" 4 "RCU_EngStartPhase1" 5 "RCU_EngStartPhase2" 6 "RCU_EngStartPhase3" 7 "RCU_DrivingChrg" 8 "RCU_RearOxy" 9 "RCU_FuelDet" 10 "RCU_CataWarm" 11 "RCU_ParkChrg" 12 "RCU_EngIdle" 13 "RCU_Rgn" 14 "reserved" 15 "reserved" 16 "RCU_EngStopPhase1" 17 "RCU_EngStopPhase2" 18 "RCU_EngStopPhase3" 19 "reserved" 20 "RCU_EmrgEngStop" 21 "RCU_Fault" 22 "reserved" 23 "reserved" 24 "reserved" ;
VAL_ 298 PCU_FaultSts 0 "Normal" 1 "Engine overtemperature" 2 "Generator overtemperature" 3 "Crash failure" 4 "Over voltage" 5 "Commnuication fault" 31 "Invalid" ;
VAL_ 298 PCU_FastTorqueFlag 0 "Inactive" 1 "Active" ;
VAL_ 298 PCU_CVC_ActvDischg_Sts 0 "Inactive" 1 "Active" 2 "Reserved" 3 "Invalid" ;
VAL_ 298 PCU_LowOilAlert 0 "No alert" 1 "Alert" 2 "Reserved" 3 "Invalid" ;
VAL_ 299 EMS_stMode 0 "KEY OFF" 1 "KEY ON" 2 "CRANK" 3 "RUN" 4 "STALL" 5 "POWER OFF DELAY" 6 "SHUTDOWN IN PROCESS" 7 "Reserved" ;
VAL_ 300 GCU_ControlMode 0 "Reserved" 1 "Torque mode" 2 "Speed mode" 3 "Invalid" ;
VAL_ 301 RCU_FuelCutoffRequest 0 "No request" 1 "Request" 2 "Reserved" 3 "Invalid" ;
VAL_ 302 RCU_GCUEnableReq 0 "No request" 1 "Request" 2 "Reserved" 3 "Invalid" ;
VAL_ 302 RCU_GCUControlMode 0 "Reserved" 1 "Torque mode" 2 "Speed mode" 3 "Invalid" ;
VAL_ 553 ADCU_Cooling_Req 0 "No Request" 1 "ADCU Cooling Request level 1" 2 "ADCU Cooling Request level 2" 3 "Invalid" ;
VAL_ 553 ADCU_RunState 0 "Waking Up" 1 "Awake" 2 "Prepare to Sleep" 3 "OTA" 4 "Reserved" 5 "Reserved" 6 "Reserved" 7 "Invalid" ;
